VERSION ""
BS_:
BU_:

BO_ 1545 DAS_telemetryRadar: 8 ETH
 SG_ DAS_TR_Counter: 54|2@1+ (1,0) [0|0] "" X
 SG_ DAS_TR_ObjIndex M: 0|5@1+ (1,0) [0|0] "" X
 SG_ DAS_TR_Obj00_Class m0: 5|3@1+ (1,0) [0|0] "" X
 SG_ DAS_TR_Obj00_Dx m0: 8|10@1+ (0.15625,0) [0|0] "m" X
 SG_ DAS_TR_Obj00_Dy m0: 18|6@1+ (0.5,-15.5) [0|0] "m" X
 SG_ DAS_TR_Obj00_Vx m0: 24|8@1+ (0.5,-63.5) [0|0] "m/s" X
 SG_ DAS_TR_Obj00_RCS m0: 32|8@1+ (0.25,-14) [0|0] "dB" X
 SG_ DAS_TR_Obj00_Length m0: 40|6@1+ (0.125,0) [0|0] "m" X
 SG_ DAS_TR_Obj00_MovingState m0: 46|2@1+ (1,0) [0|0] "" X
 SG_ DAS_TR_Obj00_Dz m0: 48|6@1+ (0.25,-5) [0|0] "m" X
 SG_ DAS_TR_Obj00_Exist m0: 56|5@1+ (3.125,0) [0|0] "%" X
 SG_ DAS_TR_Obj01_Class m1: 5|3@1+ (1,0) [0|0] "" X
 SG_ DAS_TR_Obj01_Dx m1: 8|10@1+ (0.15625,0) [0|0] "m" X
 SG_ DAS_TR_Obj01_Dy m1: 18|6@1+ (0.5,-15.5) [0|0] "m" X
 SG_ DAS_TR_Obj01_Vx m1: 24|8@1+ (0.5,-63.5) [0|0] "m/s" X
 SG_ DAS_TR_Obj01_RCS m1: 32|8@1+ (0.25,-14) [0|0] "dB" X
 SG_ DAS_TR_Obj01_Length m1: 40|6@1+ (0.125,0) [0|0] "m" X
 SG_ DAS_TR_Obj01_MovingState m1: 46|2@1+ (1,0) [0|0] "" X
 SG_ DAS_TR_Obj01_Dz m1: 48|6@1+ (0.25,-5) [0|0] "m" X
 SG_ DAS_TR_Obj01_Exist m1: 56|5@1+ (3.125,0) [0|0] "%" X
 SG_ DAS_TR_Obj02_Class m2: 5|3@1+ (1,0) [0|0] "" X
 SG_ DAS_TR_Obj02_Dx m2: 8|10@1+ (0.15625,0) [0|0] "m" X
 SG_ DAS_TR_Obj02_Dy m2: 18|6@1+ (0.5,-15.5) [0|0] "m" X
 SG_ DAS_TR_Obj02_Vx m2: 24|8@1+ (0.5,-63.5) [0|0] "m/s" X
 SG_ DAS_TR_Obj02_RCS m2: 32|8@1+ (0.25,-14) [0|0] "dB" X
 SG_ DAS_TR_Obj02_Length m2: 40|6@1+ (0.125,0) [0|0] "m" X
 SG_ DAS_TR_Obj02_MovingState m2: 46|2@1+ (1,0) [0|0] "" X
 SG_ DAS_TR_Obj02_Dz m2: 48|6@1+ (0.25,-5) [0|0] "m" X
 SG_ DAS_TR_Obj02_Exist m2: 56|5@1+ (3.125,0) [0|0] "%" X
 SG_ DAS_TR_Obj03_Class m3: 5|3@1+ (1,0) [0|0] "" X
 SG_ DAS_TR_Obj03_Dx m3: 8|10@1+ (0.15625,0) [0|0] "m" X
 SG_ DAS_TR_Obj03_Dy m3: 18|6@1+ (0.5,-15.5) [0|0] "m" X
 SG_ DAS_TR_Obj03_Vx m3: 24|8@1+ (0.5,-63.5) [0|0] "m/s" X
 SG_ DAS_TR_Obj03_RCS m3: 32|8@1+ (0.25,-14) [0|0] "dB" X
 SG_ DAS_TR_Obj03_Length m3: 40|6@1+ (0.125,0) [0|0] "m" X
 SG_ DAS_TR_Obj03_MovingState m3: 46|2@1+ (1,0) [0|0] "" X
 SG_ DAS_TR_Obj03_Dz m3: 48|6@1+ (0.25,-5) [0|0] "m" X
 SG_ DAS_TR_Obj03_Exist m3: 56|5@1+ (3.125,0) [0|0] "%" X
 SG_ DAS_TR_Obj04_Class m4: 5|3@1+ (1,0) [0|0] "" X
 SG_ DAS_TR_Obj04_Dx m4: 8|10@1+ (0.15625,0) [0|0] "m" X
 SG_ DAS_TR_Obj04_Dy m4: 18|6@1+ (0.5,-15.5) [0|0] "m" X
 SG_ DAS_TR_Obj04_Vx m4: 24|8@1+ (0.5,-63.5) [0|0] "m/s" X
 SG_ DAS_TR_Obj04_RCS m4: 32|8@1+ (0.25,-14) [0|0] "dB" X
 SG_ DAS_TR_Obj04_Length m4: 40|6@1+ (0.125,0) [0|0] "m" X
 SG_ DAS_TR_Obj04_MovingState m4: 46|2@1+ (1,0) [0|0] "" X
 SG_ DAS_TR_Obj04_Dz m4: 48|6@1+ (0.25,-5) [0|0] "m" X
 SG_ DAS_TR_Obj04_Exist m4: 56|5@1+ (3.125,0) [0|0] "%" X
 SG_ DAS_TR_Obj05_Class m5: 5|3@1+ (1,0) [0|0] "" X
 SG_ DAS_TR_Obj05_Dx m5: 8|10@1+ (0.15625,0) [0|0] "m" X
 SG_ DAS_TR_Obj05_Dy m5: 18|6@1+ (0.5,-15.5) [0|0] "m" X
 SG_ DAS_TR_Obj05_Vx m5: 24|8@1+ (0.5,-63.5) [0|0] "m/s" X
 SG_ DAS_TR_Obj05_RCS m5: 32|8@1+ (0.25,-14) [0|0] "dB" X
 SG_ DAS_TR_Obj05_Length m5: 40|6@1+ (0.125,0) [0|0] "m" X
 SG_ DAS_TR_Obj05_MovingState m5: 46|2@1+ (1,0) [0|0] "" X
 SG_ DAS_TR_Obj05_Dz m5: 48|6@1+ (0.25,-5) [0|0] "m" X
 SG_ DAS_TR_Obj05_Exist m5: 56|5@1+ (3.125,0) [0|0] "%" X
 SG_ DAS_TR_Obj06_Class m6: 5|3@1+ (1,0) [0|0] "" X
 SG_ DAS_TR_Obj06_Dx m6: 8|10@1+ (0.15625,0) [0|0] "m" X
 SG_ DAS_TR_Obj06_Dy m6: 18|6@1+ (0.5,-15.5) [0|0] "m" X
 SG_ DAS_TR_Obj06_Vx m6: 24|8@1+ (0.5,-63.5) [0|0] "m/s" X
 SG_ DAS_TR_Obj06_RCS m6: 32|8@1+ (0.25,-14) [0|0] "dB" X
 SG_ DAS_TR_Obj06_Length m6: 40|6@1+ (0.125,0) [0|0] "m" X
 SG_ DAS_TR_Obj06_MovingState m6: 46|2@1+ (1,0) [0|0] "" X
 SG_ DAS_TR_Obj06_Dz m6: 48|6@1+ (0.25,-5) [0|0] "m" X
 SG_ DAS_TR_Obj06_Exist m6: 56|5@1+ (3.125,0) [0|0] "%" X
 SG_ DAS_TR_Obj07_Class m7: 5|3@1+ (1,0) [0|0] "" X
 SG_ DAS_TR_Obj07_Dx m7: 8|10@1+ (0.15625,0) [0|0] "m" X
 SG_ DAS_TR_Obj07_Dy m7: 18|6@1+ (0.5,-15.5) [0|0] "m" X
 SG_ DAS_TR_Obj07_Vx m7: 24|8@1+ (0.5,-63.5) [0|0] "m/s" X
 SG_ DAS_TR_Obj07_RCS m7: 32|8@1+ (0.25,-14) [0|0] "dB" X
 SG_ DAS_TR_Obj07_Length m7: 40|6@1+ (0.125,0) [0|0] "m" X
 SG_ DAS_TR_Obj07_MovingState m7: 46|2@1+ (1,0) [0|0] "" X
 SG_ DAS_TR_Obj07_Dz m7: 48|6@1+ (0.25,-5) [0|0] "m" X
 SG_ DAS_TR_Obj07_Exist m7: 56|5@1+ (3.125,0) [0|0] "%" X
 SG_ DAS_TR_Obj08_Class m8: 5|3@1+ (1,0) [0|0] "" X
 SG_ DAS_TR_Obj08_Dx m8: 8|10@1+ (0.15625,0) [0|0] "m" X
 SG_ DAS_TR_Obj08_Dy m8: 18|6@1+ (0.5,-15.5) [0|0] "m" X
 SG_ DAS_TR_Obj08_Vx m8: 24|8@1+ (0.5,-63.5) [0|0] "m/s" X
 SG_ DAS_TR_Obj08_RCS m8: 32|8@1+ (0.25,-14) [0|0] "dB" X
 SG_ DAS_TR_Obj08_Length m8: 40|6@1+ (0.125,0) [0|0] "m" X
 SG_ DAS_TR_Obj08_MovingState m8: 46|2@1+ (1,0) [0|0] "" X
 SG_ DAS_TR_Obj08_Dz m8: 48|6@1+ (0.25,-5) [0|0] "m" X
 SG_ DAS_TR_Obj08_Exist m8: 56|5@1+ (3.125,0) [0|0] "%" X
 SG_ DAS_TR_Obj09_Class m9: 5|3@1+ (1,0) [0|0] "" X
 SG_ DAS_TR_Obj09_Dx m9: 8|10@1+ (0.15625,0) [0|0] "m" X
 SG_ DAS_TR_Obj09_Dy m9: 18|6@1+ (0.5,-15.5) [0|0] "m" X
 SG_ DAS_TR_Obj09_Vx m9: 24|8@1+ (0.5,-63.5) [0|0] "m/s" X
 SG_ DAS_TR_Obj09_RCS m9: 32|8@1+ (0.25,-14) [0|0] "dB" X
 SG_ DAS_TR_Obj09_Length m9: 40|6@1+ (0.125,0) [0|0] "m" X
 SG_ DAS_TR_Obj09_MovingState m9: 46|2@1+ (1,0) [0|0] "" X
 SG_ DAS_TR_Obj09_Dz m9: 48|6@1+ (0.25,-5) [0|0] "m" X
 SG_ DAS_TR_Obj09_Exist m9: 56|5@1+ (3.125,0) [0|0] "%" X
 SG_ DAS_TR_Obj10_Class m10: 5|3@1+ (1,0) [0|0] "" X
 SG_ DAS_TR_Obj10_Dx m10: 8|10@1+ (0.15625,0) [0|0] "m" X
 SG_ DAS_TR_Obj10_Dy m10: 18|6@1+ (0.5,-15.5) [0|0] "m" X
 SG_ DAS_TR_Obj10_Vx m10: 24|8@1+ (0.5,-63.5) [0|0] "m/s" X
 SG_ DAS_TR_Obj10_RCS m10: 32|8@1+ (0.25,-14) [0|0] "dB" X
 SG_ DAS_TR_Obj10_Length m10: 40|6@1+ (0.125,0) [0|0] "m" X
 SG_ DAS_TR_Obj10_MovingState m10: 46|2@1+ (1,0) [0|0] "" X
 SG_ DAS_TR_Obj10_Dz m10: 48|6@1+ (0.25,-5) [0|0] "m" X
 SG_ DAS_TR_Obj10_Exist m10: 56|5@1+ (3.125,0) [0|0] "%" X
 SG_ DAS_TR_Obj11_Class m11: 5|3@1+ (1,0) [0|0] "" X
 SG_ DAS_TR_Obj11_Dx m11: 8|10@1+ (0.15625,0) [0|0] "m" X
 SG_ DAS_TR_Obj11_Dy m11: 18|6@1+ (0.5,-15.5) [0|0] "m" X
 SG_ DAS_TR_Obj11_Vx m11: 24|8@1+ (0.5,-63.5) [0|0] "m/s" X
 SG_ DAS_TR_Obj11_RCS m11: 32|8@1+ (0.25,-14) [0|0] "dB" X
 SG_ DAS_TR_Obj11_Length m11: 40|6@1+ (0.125,0) [0|0] "m" X
 SG_ DAS_TR_Obj11_MovingState m11: 46|2@1+ (1,0) [0|0] "" X
 SG_ DAS_TR_Obj11_Dz m11: 48|6@1+ (0.25,-5) [0|0] "m" X
 SG_ DAS_TR_Obj11_Exist m11: 56|5@1+ (3.125,0) [0|0] "%" X
 SG_ DAS_TR_Obj12_Class m12: 5|3@1+ (1,0) [0|0] "" X
 SG_ DAS_TR_Obj12_Dx m12: 8|10@1+ (0.15625,0) [0|0] "m" X
 SG_ DAS_TR_Obj12_Dy m12: 18|6@1+ (0.5,-15.5) [0|0] "m" X
 SG_ DAS_TR_Obj12_Vx m12: 24|8@1+ (0.5,-63.5) [0|0] "m/s" X
 SG_ DAS_TR_Obj12_RCS m12: 32|8@1+ (0.25,-14) [0|0] "dB" X
 SG_ DAS_TR_Obj12_Length m12: 40|6@1+ (0.125,0) [0|0] "m" X
 SG_ DAS_TR_Obj12_MovingState m12: 46|2@1+ (1,0) [0|0] "" X
 SG_ DAS_TR_Obj12_Dz m12: 48|6@1+ (0.25,-5) [0|0] "m" X
 SG_ DAS_TR_Obj12_Exist m12: 56|5@1+ (3.125,0) [0|0] "%" X
 SG_ DAS_TR_Obj13_Class m13: 5|3@1+ (1,0) [0|0] "" X
 SG_ DAS_TR_Obj13_Dx m13: 8|10@1+ (0.15625,0) [0|0] "m" X
 SG_ DAS_TR_Obj13_Dy m13: 18|6@1+ (0.5,-15.5) [0|0] "m" X
 SG_ DAS_TR_Obj13_Vx m13: 24|8@1+ (0.5,-63.5) [0|0] "m/s" X
 SG_ DAS_TR_Obj13_RCS m13: 32|8@1+ (0.25,-14) [0|0] "dB" X
 SG_ DAS_TR_Obj13_Length m13: 40|6@1+ (0.125,0) [0|0] "m" X
 SG_ DAS_TR_Obj13_MovingState m13: 46|2@1+ (1,0) [0|0] "" X
 SG_ DAS_TR_Obj13_Dz m13: 48|6@1+ (0.25,-5) [0|0] "m" X
 SG_ DAS_TR_Obj13_Exist m13: 56|5@1+ (3.125,0) [0|0] "%" X
 SG_ DAS_TR_Obj14_Class m14: 5|3@1+ (1,0) [0|0] "" X
 SG_ DAS_TR_Obj14_Dx m14: 8|10@1+ (0.15625,0) [0|0] "m" X
 SG_ DAS_TR_Obj14_Dy m14: 18|6@1+ (0.5,-15.5) [0|0] "m" X
 SG_ DAS_TR_Obj14_Vx m14: 24|8@1+ (0.5,-63.5) [0|0] "m/s" X
 SG_ DAS_TR_Obj14_RCS m14: 32|8@1+ (0.25,-14) [0|0] "dB" X
 SG_ DAS_TR_Obj14_Length m14: 40|6@1+ (0.125,0) [0|0] "m" X
 SG_ DAS_TR_Obj14_MovingState m14: 46|2@1+ (1,0) [0|0] "" X
 SG_ DAS_TR_Obj14_Dz m14: 48|6@1+ (0.25,-5) [0|0] "m" X
 SG_ DAS_TR_Obj14_Exist m14: 56|5@1+ (3.125,0) [0|0] "%" X
 SG_ DAS_TR_Obj15_Class m15: 5|3@1+ (1,0) [0|0] "" X
 SG_ DAS_TR_Obj15_Dx m15: 8|10@1+ (0.15625,0) [0|0] "m" X
 SG_ DAS_TR_Obj15_Dy m15: 18|6@1+ (0.5,-15.5) [0|0] "m" X
 SG_ DAS_TR_Obj15_Vx m15: 24|8@1+ (0.5,-63.5) [0|0] "m/s" X
 SG_ DAS_TR_Obj15_RCS m15: 32|8@1+ (0.25,-14) [0|0] "dB" X
 SG_ DAS_TR_Obj15_Length m15: 40|6@1+ (0.125,0) [0|0] "m" X
 SG_ DAS_TR_Obj15_MovingState m15: 46|2@1+ (1,0) [0|0] "" X
 SG_ DAS_TR_Obj15_Dz m15: 48|6@1+ (0.25,-5) [0|0] "m" X
 SG_ DAS_TR_Obj15_Exist m15: 56|5@1+ (3.125,0) [0|0] "%" X
 SG_ DAS_TR_Obj16_Class m16: 5|3@1+ (1,0) [0|0] "" X
 SG_ DAS_TR_Obj16_Dx m16: 8|10@1+ (0.15625,0) [0|0] "m" X
 SG_ DAS_TR_Obj16_Dy m16: 18|6@1+ (0.5,-15.5) [0|0] "m" X
 SG_ DAS_TR_Obj16_Vx m16: 24|8@1+ (0.5,-63.5) [0|0] "m/s" X
 SG_ DAS_TR_Obj16_RCS m16: 32|8@1+ (0.25,-14) [0|0] "dB" X
 SG_ DAS_TR_Obj16_Length m16: 40|6@1+ (0.125,0) [0|0] "m" X
 SG_ DAS_TR_Obj16_MovingState m16: 46|2@1+ (1,0) [0|0] "" X
 SG_ DAS_TR_Obj16_Dz m16: 48|6@1+ (0.25,-5) [0|0] "m" X
 SG_ DAS_TR_Obj16_Exist m16: 56|5@1+ (3.125,0) [0|0] "%" X
 SG_ DAS_TR_Obj17_Class m17: 5|3@1+ (1,0) [0|0] "" X
 SG_ DAS_TR_Obj17_Dx m17: 8|10@1+ (0.15625,0) [0|0] "m" X
 SG_ DAS_TR_Obj17_Dy m17: 18|6@1+ (0.5,-15.5) [0|0] "m" X
 SG_ DAS_TR_Obj17_Vx m17: 24|8@1+ (0.5,-63.5) [0|0] "m/s" X
 SG_ DAS_TR_Obj17_RCS m17: 32|8@1+ (0.25,-14) [0|0] "dB" X
 SG_ DAS_TR_Obj17_Length m17: 40|6@1+ (0.125,0) [0|0] "m" X
 SG_ DAS_TR_Obj17_MovingState m17: 46|2@1+ (1,0) [0|0] "" X
 SG_ DAS_TR_Obj17_Dz m17: 48|6@1+ (0.25,-5) [0|0] "m" X
 SG_ DAS_TR_Obj17_Exist m17: 56|5@1+ (3.125,0) [0|0] "%" X
 SG_ DAS_TR_Obj18_Class m18: 5|3@1+ (1,0) [0|0] "" X
 SG_ DAS_TR_Obj18_Dx m18: 8|10@1+ (0.15625,0) [0|0] "m" X
 SG_ DAS_TR_Obj18_Dy m18: 18|6@1+ (0.5,-15.5) [0|0] "m" X
 SG_ DAS_TR_Obj18_Vx m18: 24|8@1+ (0.5,-63.5) [0|0] "m/s" X
 SG_ DAS_TR_Obj18_RCS m18: 32|8@1+ (0.25,-14) [0|0] "dB" X
 SG_ DAS_TR_Obj18_Length m18: 40|6@1+ (0.125,0) [0|0] "m" X
 SG_ DAS_TR_Obj18_MovingState m18: 46|2@1+ (1,0) [0|0] "" X
 SG_ DAS_TR_Obj18_Dz m18: 48|6@1+ (0.25,-5) [0|0] "m" X
 SG_ DAS_TR_Obj18_Exist m18: 56|5@1+ (3.125,0) [0|0] "%" X
 SG_ DAS_TR_Obj19_Class m19: 5|3@1+ (1,0) [0|0] "" X
 SG_ DAS_TR_Obj19_Dx m19: 8|10@1+ (0.15625,0) [0|0] "m" X
 SG_ DAS_TR_Obj19_Dy m19: 18|6@1+ (0.5,-15.5) [0|0] "m" X
 SG_ DAS_TR_Obj19_Vx m19: 24|8@1+ (0.5,-63.5) [0|0] "m/s" X
 SG_ DAS_TR_Obj19_RCS m19: 32|8@1+ (0.25,-14) [0|0] "dB" X
 SG_ DAS_TR_Obj19_Length m19: 40|6@1+ (0.125,0) [0|0] "m" X
 SG_ DAS_TR_Obj19_MovingState m19: 46|2@1+ (1,0) [0|0] "" X
 SG_ DAS_TR_Obj19_Dz m19: 48|6@1+ (0.25,-5) [0|0] "m" X
 SG_ DAS_TR_Obj19_Exist m19: 56|5@1+ (3.125,0) [0|0] "%" X
 SG_ DAS_TR_Obj20_Class m20: 5|3@1+ (1,0) [0|0] "" X
 SG_ DAS_TR_Obj20_Dx m20: 8|10@1+ (0.15625,0) [0|0] "m" X
 SG_ DAS_TR_Obj20_Dy m20: 18|6@1+ (0.5,-15.5) [0|0] "m" X
 SG_ DAS_TR_Obj20_Vx m20: 24|8@1+ (0.5,-63.5) [0|0] "m/s" X
 SG_ DAS_TR_Obj20_RCS m20: 32|8@1+ (0.25,-14) [0|0] "dB" X
 SG_ DAS_TR_Obj20_Length m20: 40|6@1+ (0.125,0) [0|0] "m" X
 SG_ DAS_TR_Obj20_MovingState m20: 46|2@1+ (1,0) [0|0] "" X
 SG_ DAS_TR_Obj20_Dz m20: 48|6@1+ (0.25,-5) [0|0] "m" X
 SG_ DAS_TR_Obj20_Exist m20: 56|5@1+ (3.125,0) [0|0] "%" X
 SG_ DAS_TR_Obj21_Class m21: 5|3@1+ (1,0) [0|0] "" X
 SG_ DAS_TR_Obj21_Dx m21: 8|10@1+ (0.15625,0) [0|0] "m" X
 SG_ DAS_TR_Obj21_Dy m21: 18|6@1+ (0.5,-15.5) [0|0] "m" X
 SG_ DAS_TR_Obj21_Vx m21: 24|8@1+ (0.5,-63.5) [0|0] "m/s" X
 SG_ DAS_TR_Obj21_RCS m21: 32|8@1+ (0.25,-14) [0|0] "dB" X
 SG_ DAS_TR_Obj21_Length m21: 40|6@1+ (0.125,0) [0|0] "m" X
 SG_ DAS_TR_Obj21_MovingState m21: 46|2@1+ (1,0) [0|0] "" X
 SG_ DAS_TR_Obj21_Dz m21: 48|6@1+ (0.25,-5) [0|0] "m" X
 SG_ DAS_TR_Obj21_Exist m21: 56|5@1+ (3.125,0) [0|0] "%" X
 SG_ DAS_TR_Obj22_Class m22: 5|3@1+ (1,0) [0|0] "" X
 SG_ DAS_TR_Obj22_Dx m22: 8|10@1+ (0.15625,0) [0|0] "m" X
 SG_ DAS_TR_Obj22_Dy m22: 18|6@1+ (0.5,-15.5) [0|0] "m" X
 SG_ DAS_TR_Obj22_Vx m22: 24|8@1+ (0.5,-63.5) [0|0] "m/s" X
 SG_ DAS_TR_Obj22_RCS m22: 32|8@1+ (0.25,-14) [0|0] "dB" X
 SG_ DAS_TR_Obj22_Length m22: 40|6@1+ (0.125,0) [0|0] "m" X
 SG_ DAS_TR_Obj22_MovingState m22: 46|2@1+ (1,0) [0|0] "" X
 SG_ DAS_TR_Obj22_Dz m22: 48|6@1+ (0.25,-5) [0|0] "m" X
 SG_ DAS_TR_Obj22_Exist m22: 56|5@1+ (3.125,0) [0|0] "%" X
 SG_ DAS_TR_Obj23_Class m23: 5|3@1+ (1,0) [0|0] "" X
 SG_ DAS_TR_Obj23_Dx m23: 8|10@1+ (0.15625,0) [0|0] "m" X
 SG_ DAS_TR_Obj23_Dy m23: 18|6@1+ (0.5,-15.5) [0|0] "m" X
 SG_ DAS_TR_Obj23_Vx m23: 24|8@1+ (0.5,-63.5) [0|0] "m/s" X
 SG_ DAS_TR_Obj23_RCS m23: 32|8@1+ (0.25,-14) [0|0] "dB" X
 SG_ DAS_TR_Obj23_Length m23: 40|6@1+ (0.125,0) [0|0] "m" X
 SG_ DAS_TR_Obj23_MovingState m23: 46|2@1+ (1,0) [0|0] "" X
 SG_ DAS_TR_Obj23_Dz m23: 48|6@1+ (0.25,-5) [0|0] "m" X
 SG_ DAS_TR_Obj23_Exist m23: 56|5@1+ (3.125,0) [0|0] "%" X
 SG_ DAS_TR_Obj24_Class m24: 5|3@1+ (1,0) [0|0] "" X
 SG_ DAS_TR_Obj24_Dx m24: 8|10@1+ (0.15625,0) [0|0] "m" X
 SG_ DAS_TR_Obj24_Dy m24: 18|6@1+ (0.5,-15.5) [0|0] "m" X
 SG_ DAS_TR_Obj24_Vx m24: 24|8@1+ (0.5,-63.5) [0|0] "m/s" X
 SG_ DAS_TR_Obj24_RCS m24: 32|8@1+ (0.25,-14) [0|0] "dB" X
 SG_ DAS_TR_Obj24_Length m24: 40|6@1+ (0.125,0) [0|0] "m" X
 SG_ DAS_TR_Obj24_MovingState m24: 46|2@1+ (1,0) [0|0] "" X
 SG_ DAS_TR_Obj24_Dz m24: 48|6@1+ (0.25,-5) [0|0] "m" X
 SG_ DAS_TR_Obj24_Exist m24: 56|5@1+ (3.125,0) [0|0] "%" X
 SG_ DAS_TR_Obj25_Class m25: 5|3@1+ (1,0) [0|0] "" X
 SG_ DAS_TR_Obj25_Dx m25: 8|10@1+ (0.15625,0) [0|0] "m" X
 SG_ DAS_TR_Obj25_Dy m25: 18|6@1+ (0.5,-15.5) [0|0] "m" X
 SG_ DAS_TR_Obj25_Vx m25: 24|8@1+ (0.5,-63.5) [0|0] "m/s" X
 SG_ DAS_TR_Obj25_RCS m25: 32|8@1+ (0.25,-14) [0|0] "dB" X
 SG_ DAS_TR_Obj25_Length m25: 40|6@1+ (0.125,0) [0|0] "m" X
 SG_ DAS_TR_Obj25_MovingState m25: 46|2@1+ (1,0) [0|0] "" X
 SG_ DAS_TR_Obj25_Dz m25: 48|6@1+ (0.25,-5) [0|0] "m" X
 SG_ DAS_TR_Obj25_Exist m25: 56|5@1+ (3.125,0) [0|0] "%" X
 SG_ DAS_TR_Obj26_Class m26: 5|3@1+ (1,0) [0|0] "" X
 SG_ DAS_TR_Obj26_Dx m26: 8|10@1+ (0.15625,0) [0|0] "m" X
 SG_ DAS_TR_Obj26_Dy m26: 18|6@1+ (0.5,-15.5) [0|0] "m" X
 SG_ DAS_TR_Obj26_Vx m26: 24|8@1+ (0.5,-63.5) [0|0] "m/s" X
 SG_ DAS_TR_Obj26_RCS m26: 32|8@1+ (0.25,-14) [0|0] "dB" X
 SG_ DAS_TR_Obj26_Length m26: 40|6@1+ (0.125,0) [0|0] "m" X
 SG_ DAS_TR_Obj26_MovingState m26: 46|2@1+ (1,0) [0|0] "" X
 SG_ DAS_TR_Obj26_Dz m26: 48|6@1+ (0.25,-5) [0|0] "m" X
 SG_ DAS_TR_Obj26_Exist m26: 56|5@1+ (3.125,0) [0|0] "%" X
 SG_ DAS_TR_Obj27_Class m27: 5|3@1+ (1,0) [0|0] "" X
 SG_ DAS_TR_Obj27_Dx m27: 8|10@1+ (0.15625,0) [0|0] "m" X
 SG_ DAS_TR_Obj27_Dy m27: 18|6@1+ (0.5,-15.5) [0|0] "m" X
 SG_ DAS_TR_Obj27_Vx m27: 24|8@1+ (0.5,-63.5) [0|0] "m/s" X
 SG_ DAS_TR_Obj27_RCS m27: 32|8@1+ (0.25,-14) [0|0] "dB" X
 SG_ DAS_TR_Obj27_Length m27: 40|6@1+ (0.125,0) [0|0] "m" X
 SG_ DAS_TR_Obj27_MovingState m27: 46|2@1+ (1,0) [0|0] "" X
 SG_ DAS_TR_Obj27_Dz m27: 48|6@1+ (0.25,-5) [0|0] "m" X
 SG_ DAS_TR_Obj27_Exist m27: 56|5@1+ (3.125,0) [0|0] "%" X
 SG_ DAS_TR_Obj28_Class m28: 5|3@1+ (1,0) [0|0] "" X
 SG_ DAS_TR_Obj28_Dx m28: 8|10@1+ (0.15625,0) [0|0] "m" X
 SG_ DAS_TR_Obj28_Dy m28: 18|6@1+ (0.5,-15.5) [0|0] "m" X
 SG_ DAS_TR_Obj28_Vx m28: 24|8@1+ (0.5,-63.5) [0|0] "m/s" X
 SG_ DAS_TR_Obj28_RCS m28: 32|8@1+ (0.25,-14) [0|0] "dB" X
 SG_ DAS_TR_Obj28_Length m28: 40|6@1+ (0.125,0) [0|0] "m" X
 SG_ DAS_TR_Obj28_MovingState m28: 46|2@1+ (1,0) [0|0] "" X
 SG_ DAS_TR_Obj28_Dz m28: 48|6@1+ (0.25,-5) [0|0] "m" X
 SG_ DAS_TR_Obj28_Exist m28: 56|5@1+ (3.125,0) [0|0] "%" X
 SG_ DAS_TR_Obj29_Class m29: 5|3@1+ (1,0) [0|0] "" X
 SG_ DAS_TR_Obj29_Dx m29: 8|10@1+ (0.15625,0) [0|0] "m" X
 SG_ DAS_TR_Obj29_Dy m29: 18|6@1+ (0.5,-15.5) [0|0] "m" X
 SG_ DAS_TR_Obj29_Vx m29: 24|8@1+ (0.5,-63.5) [0|0] "m/s" X
 SG_ DAS_TR_Obj29_RCS m29: 32|8@1+ (0.25,-14) [0|0] "dB" X
 SG_ DAS_TR_Obj29_Length m29: 40|6@1+ (0.125,0) [0|0] "m" X
 SG_ DAS_TR_Obj29_MovingState m29: 46|2@1+ (1,0) [0|0] "" X
 SG_ DAS_TR_Obj29_Dz m29: 48|6@1+ (0.25,-5) [0|0] "m" X
 SG_ DAS_TR_Obj29_Exist m29: 56|5@1+ (3.125,0) [0|0] "%" X
 SG_ DAS_TR_Obj30_Class m30: 5|3@1+ (1,0) [0|0] "" X
 SG_ DAS_TR_Obj30_Dx m30: 8|10@1+ (0.15625,0) [0|0] "m" X
 SG_ DAS_TR_Obj30_Dy m30: 18|6@1+ (0.5,-15.5) [0|0] "m" X
 SG_ DAS_TR_Obj30_Vx m30: 24|8@1+ (0.5,-63.5) [0|0] "m/s" X
 SG_ DAS_TR_Obj30_RCS m30: 32|8@1+ (0.25,-14) [0|0] "dB" X
 SG_ DAS_TR_Obj30_Length m30: 40|6@1+ (0.125,0) [0|0] "m" X
 SG_ DAS_TR_Obj30_MovingState m30: 46|2@1+ (1,0) [0|0] "" X
 SG_ DAS_TR_Obj30_Dz m30: 48|6@1+ (0.25,-5) [0|0] "m" X
 SG_ DAS_TR_Obj30_Exist m30: 56|5@1+ (3.125,0) [0|0] "%" X
 SG_ DAS_TR_Obj31_Class m31: 5|3@1+ (1,0) [0|0] "" X
 SG_ DAS_TR_Obj31_Dx m31: 8|10@1+ (0.15625,0) [0|0] "m" X
 SG_ DAS_TR_Obj31_Dy m31: 18|6@1+ (0.5,-15.5) [0|0] "m" X
 SG_ DAS_TR_Obj31_Vx m31: 24|8@1+ (0.5,-63.5) [0|0] "m/s" X
 SG_ DAS_TR_Obj31_RCS m31: 32|8@1+ (0.25,-14) [0|0] "dB" X
 SG_ DAS_TR_Obj31_Length m31: 40|6@1+ (0.125,0) [0|0] "m" X
 SG_ DAS_TR_Obj31_MovingState m31: 46|2@1+ (1,0) [0|0] "" X
 SG_ DAS_TR_Obj31_Dz m31: 48|6@1+ (0.25,-5) [0|0] "m" X
 SG_ DAS_TR_Obj31_Exist m31: 56|5@1+ (3.125,0) [0|0] "%" X

BO_ 1625 DAS_udsResponse: 8 ETH
 SG_ DAS_udsResponseData: 0|54@0+ (1024,0) [0|0] "" X

BO_ 585 DAS_visualDebug: 8 ETH
 SG_ DAS_accSmartSpeedActive: 48|1@1+ (1,0) [0|0] "" X
 SG_ DAS_accSmartSpeedState: 49|3@1+ (1,0) [0|0] "" X
 SG_ DAS_autosteerBottsDotsUsage: 12|2@1+ (1,0) [0|0] "" X
 SG_ DAS_autosteerHPPUsage: 6|2@1+ (1,0) [0|0] "" X
 SG_ DAS_autosteerHealthAnomalyLevel: 18|3@1+ (1,0) [0|0] "" X
 SG_ DAS_autosteerHealthState: 21|3@1+ (1,0) [0|0] "" X
 SG_ DAS_autosteerModelUsage: 10|2@1+ (1,0) [0|0] "" X
 SG_ DAS_autosteerNavigationUsage: 8|2@1+ (1,0) [0|0] "" X
 SG_ DAS_autosteerVehiclesUsage: 4|2@1+ (1,0) [0|0] "" X
 SG_ DAS_behaviorType: 56|2@1+ (1,0) [0|0] "" X
 SG_ DAS_devAppInterfaceEnabled: 38|1@1+ (1,0) [0|0] "" X
 SG_ DAS_lastAutosteerAbortReason: 32|6@1+ (1,0) [0|0] "" X
 SG_ DAS_lastLinePreferenceReason: 24|4@1+ (1,0) [0|0] "" X
 SG_ DAS_navAvailable: 39|1@1+ (1,0) [0|0] "" X
 SG_ DAS_navDistance: 40|8@1+ (100,0) [0|0] "" X
 SG_ DAS_offsetSide: 14|2@1+ (1,0) [0|0] "" X
 SG_ DAS_plannerState: 28|4@1+ (1,0) [0|0] "" X
 SG_ DAS_rearVehDetectedThisCycle: 60|1@1+ (1,0) [0|0] "" X
 SG_ DAS_roadSurfaceType: 16|2@1+ (1,0) [0|0] "" X
 SG_ DAS_ulcInProgress: 52|1@1+ (1,0) [0|0] "" X
 SG_ DAS_ulcType: 58|2@1+ (1,0) [0|0] "" X

BO_ 809 DAS_warningMatrix0: 8 ETH
 SG_ DAS_w002_ldwDisabled: 1|1@1+ (1,0) [0|0] "" X
 SG_ DAS_w003_isaDisabled: 2|1@1+ (1,0) [0|0] "" X
 SG_ DAS_w004_accDisabled: 3|1@1+ (1,0) [0|0] "" X
 SG_ DAS_w005_fcwCancelled: 4|1@1+ (1,0) [0|0] "" X
 SG_ DAS_w006_aebCancelled: 5|1@1+ (1,0) [0|0] "" X
 SG_ DAS_w007_ahlbDisabled: 6|1@1+ (1,0) [0|0] "" X
 SG_ DAS_w008_parkDisabled: 7|1@1+ (1,0) [0|0] "" X
 SG_ DAS_w009_aebFault: 8|1@1+ (1,0) [0|0] "" X
 SG_ DAS_w010_radcCalibIssue: 9|1@1+ (1,0) [0|0] "" X
 SG_ DAS_w011_scaEvent: 10|1@1+ (1,0) [0|0] "" X
 SG_ DAS_w012_Cam_BootFailure: 11|1@1+ (1,0) [0|0] "" X
 SG_ DAS_w013_Cam_Watchdog: 12|1@1+ (1,0) [0|0] "" X
 SG_ DAS_w014_swAssert: 13|1@1+ (1,0) [0|0] "" X
 SG_ DAS_w015_Camera_Failsafes: 14|1@1+ (1,0) [0|0] "" X
 SG_ DAS_w016_aeb_e_event: 15|1@1+ (1,0) [0|0] "" X
 SG_ DAS_w017_Cam_Msg_MIA: 16|1@1+ (1,0) [0|0] "" X
 SG_ DAS_w018_ECU_Power_Issue: 17|1@1+ (1,0) [0|0] "" X
 SG_ DAS_w019_ECU_Stack_Overflow: 18|1@1+ (1,0) [0|0] "" X
 SG_ DAS_w020_ECU_checkstopError: 19|1@1+ (1,0) [0|0] "" X
 SG_ DAS_w021_ECU_Temperature_Issue: 20|1@1+ (1,0) [0|0] "" X
 SG_ DAS_w022_ECU_EEPROM_Failure: 21|1@1+ (1,0) [0|0] "" X
 SG_ DAS_w023_ECU_Cam_Statemismatc: 22|1@1+ (1,0) [0|0] "" X
 SG_ DAS_w024_ECU_Watchdog_Reset: 23|1@1+ (1,0) [0|0] "" X
 SG_ DAS_w025_LC_Steering_Override: 24|1@1+ (1,0) [0|0] "" X
 SG_ DAS_w026_ECU_timingIssue: 25|1@1+ (1,0) [0|0] "" X
 SG_ DAS_w027_ECU_Reset_Fault: 26|1@1+ (1,0) [0|0] "" X
 SG_ DAS_w028_spi_rx_error: 27|1@1+ (1,0) [0|0] "" X
 SG_ DAS_w029_spi_tx_error: 28|1@1+ (1,0) [0|0] "" X
 SG_ DAS_w030_Heater_Issue: 29|1@1+ (1,0) [0|0] "" X
 SG_ DAS_w031_canRxError: 30|1@1+ (1,0) [0|0] "" X
 SG_ DAS_w032_canTxError: 31|1@1+ (1,0) [0|0] "" X
 SG_ DAS_w033_gtwMia: 32|1@1+ (1,0) [0|0] "" X
 SG_ DAS_w034_sccmMia: 33|1@1+ (1,0) [0|0] "" X
 SG_ DAS_w035_espMia: 34|1@1+ (1,0) [0|0] "" X
 SG_ DAS_w036_bdyMia: 35|1@1+ (1,0) [0|0] "" X
 SG_ DAS_w037_camTacIssue: 36|1@1+ (1,0) [0|0] "" X
 SG_ DAS_w038_camFailure: 37|1@1+ (1,0) [0|0] "" X
 SG_ DAS_w039_sdm_rcm_Mia: 38|1@1+ (1,0) [0|0] "" X
 SG_ DAS_w040_autopilotAngleSaturated: 39|1@1+ (1,0) [0|0] "" X
 SG_ DAS_w041_autopilotRateSaturated: 40|1@1+ (1,0) [0|0] "" X
 SG_ DAS_w042_autopilotAborting: 41|1@1+ (1,0) [0|0] "" X
 SG_ DAS_w043_camLongRunTime: 42|1@1+ (1,0) [0|0] "" X
 SG_ DAS_w044_appMobileyeFailure: 43|1@1+ (1,0) [0|0] "" X
 SG_ DAS_w045_radMia: 44|1@1+ (1,0) [0|0] "" X
 SG_ DAS_w046_eepromRecordAbsent: 45|1@1+ (1,0) [0|0] "" X
 SG_ DAS_w047_edrEvent: 46|1@1+ (1,0) [0|0] "" X
 SG_ DAS_w048_DAS_Features_Disabled: 47|1@1+ (1,0) [0|0] "" X
 SG_ DAS_w049_eyeqVersionMismatch: 48|1@1+ (1,0) [0|0] "" X
 SG_ DAS_w050_aeb_event: 49|1@1+ (1,0) [0|0] "" X
 SG_ DAS_w051_radcEcuIssue: 50|1@1+ (1,0) [0|0] "" X
 SG_ DAS_w052_radcSensorIssue: 51|1@1+ (1,0) [0|0] "" X
 SG_ DAS_w053_radcCommIssue: 52|1@1+ (1,0) [0|0] "" X
 SG_ DAS_w054_camAutofix: 53|1@1+ (1,0) [0|0] "" X
 SG_ DAS_w055_radcVersionMismatch: 54|1@1+ (1,0) [0|0] "" X
 SG_ DAS_w056_diMia: 55|1@1+ (1,0) [0|0] "" X
 SG_ DAS_w057_mcuMia: 56|1@1+ (1,0) [0|0] "" X
 SG_ DAS_w058_epbMia: 57|1@1+ (1,0) [0|0] "" X
 SG_ DAS_w059_parkMia: 58|1@1+ (1,0) [0|0] "" X
 SG_ DAS_w060_fcw_event: 59|1@1+ (1,0) [0|0] "" X
 SG_ DAS_w061_airSuspensionMia: 60|1@1+ (1,0) [0|0] "" X
 SG_ DAS_w062_radcAlignment: 61|1@1+ (1,0) [0|0] "" X
 SG_ DAS_w063_parkVersionMismatch: 62|1@1+ (1,0) [0|0] "" X
 SG_ DAS_w064_epasMia: 63|1@1+ (1,0) [0|0] "" X

BO_ 873 DAS_warningMatrix1: 8 ETH
 SG_ DAS_w065_deserializerOvercurrent: 0|1@1+ (1,0) [0|0] "" X
 SG_ DAS_w066_deserializerLockLost: 1|1@1+ (1,0) [0|0] "" X
 SG_ DAS_w067_steeringAlignment: 2|1@1+ (1,0) [0|0] "" X
 SG_ DAS_w068_vlInconsistency: 3|1@1+ (1,0) [0|0] "" X
 SG_ DAS_w069_apcSpaceMasked: 4|1@1+ (1,0) [0|0] "" X
 SG_ DAS_w070_apcIncompleteCal: 5|1@1+ (1,0) [0|0] "" X
 SG_ DAS_w071_selfparkStarted: 6|1@1+ (1,0) [0|0] "" X
 SG_ DAS_w072_selfparkComplete: 7|1@1+ (1,0) [0|0] "" X
 SG_ DAS_w073_issueEscalatedLDW: 8|1@1+ (1,0) [0|0] "" X
 SG_ DAS_w074_inPathStationaryObst: 9|1@1+ (1,0) [0|0] "" X
 SG_ DAS_w075_scMia: 10|1@1+ (1,0) [0|0] "" X
 SG_ DAS_w076_mobilEyeSetC: 11|1@1+ (1,0) [0|0] "" X
 SG_ DAS_w077_pmmActive: 12|1@1+ (1,0) [0|0] "" X
 SG_ DAS_w078_pmmActive2: 13|1@1+ (1,0) [0|0] "" X
 SG_ DAS_w079_edrAvailable: 14|1@1+ (1,0) [0|0] "" X
 SG_ DAS_w080_accFailedActivation: 15|1@1+ (1,0) [0|0] "" X
 SG_ DAS_w081_pmmActiveBraking: 16|1@1+ (1,0) [0|0] "" X
 SG_ DAS_w082_inPathFSviolation: 17|1@1+ (1,0) [0|0] "" X
 SG_ DAS_w083_inPathRADObject: 18|1@1+ (1,0) [0|0] "" X
 SG_ DAS_w084_pmmIPSO: 19|1@1+ (1,0) [0|0] "" X
 SG_ DAS_w085_pmmSteering: 20|1@1+ (1,0) [0|0] "" X
 SG_ DAS_w086_robCollision: 21|1@1+ (1,0) [0|0] "" X
 SG_ DAS_w087_DEPRECATED: 22|1@1+ (1,0) [0|0] "" X
 SG_ DAS_w088_DEPRECATED: 23|1@1+ (1,0) [0|0] "" X
 SG_ DAS_w089_DEPRECATED: 24|1@1+ (1,0) [0|0] "" X
 SG_ DAS_w090_DEPRECATED: 25|1@1+ (1,0) [0|0] "" X
 SG_ DAS_w091_DEPRECATED: 26|1@1+ (1,0) [0|0] "" X
 SG_ DAS_w092_DEPRECATED: 27|1@1+ (1,0) [0|0] "" X
 SG_ DAS_w093_DEPRECATED: 28|1@1+ (1,0) [0|0] "" X
 SG_ DAS_w094_DEPRECATED: 29|1@1+ (1,0) [0|0] "" X
 SG_ DAS_w095_DEPRECATED: 30|1@1+ (1,0) [0|0] "" X
 SG_ DAS_w096_DEPRECATED: 31|1@1+ (1,0) [0|0] "" X
 SG_ DAS_w097_DEPRECATED: 32|1@1+ (1,0) [0|0] "" X
 SG_ DAS_w098_DEPRECATED: 33|1@1+ (1,0) [0|0] "" X
 SG_ DAS_w099_DEPRECATED: 34|1@1+ (1,0) [0|0] "" X
 SG_ DAS_w100_DEPRECATED: 35|1@1+ (1,0) [0|0] "" X
 SG_ DAS_w101_DEPRECATED: 36|1@1+ (1,0) [0|0] "" X
 SG_ DAS_w102_DEPRECATED: 37|1@1+ (1,0) [0|0] "" X
 SG_ DAS_w103_robExperimentalAEB: 38|1@1+ (1,0) [0|0] "" X
 SG_ DAS_w104_DEPRECATED: 39|1@1+ (1,0) [0|0] "" X
 SG_ DAS_w105_DEPRECATED: 40|1@1+ (1,0) [0|0] "" X
 SG_ DAS_w106_torsionBarCalibrated: 41|1@1+ (1,0) [0|0] "" X

BO_ 841 DAS_warningMatrix3: 8 ETH
 SG_ DAS_w193_camWindshieldUnclean: 0|1@1+ (1,0) [0|0] "" X
 SG_ DAS_w194_accDriverResumeRqrd: 1|1@1+ (1,0) [0|0] "" X
 SG_ DAS_w195_scwUnavailable: 2|1@1+ (1,0) [0|0] "" X
 SG_ DAS_w196_stopSignWarning: 3|1@1+ (1,0) [0|0] "" X
 SG_ DAS_w197_redLightWarning: 4|1@1+ (1,0) [0|0] "" X
 SG_ DAS_w198_tsrUnavailable: 5|1@1+ (1,0) [0|0] "" X
 SG_ DAS_w199_apcAbort: 6|1@1+ (1,0) [0|0] "" X
 SG_ DAS_w200_lcSlowdown: 7|1@1+ (1,0) [0|0] "" X
 SG_ DAS_w201_lcAborting: 8|1@1+ (1,0) [0|0] "" X
 SG_ DAS_w202_scwNoisyEnvironment: 9|1@1+ (1,0) [0|0] "" X
 SG_ DAS_w203_apcActivation: 10|1@1+ (1,0) [0|0] "" X
 SG_ DAS_w204_apcFinalFront: 11|1@1+ (1,0) [0|0] "" X
 SG_ DAS_w205_apcFinalRear: 12|1@1+ (1,0) [0|0] "" X
 SG_ DAS_w206_autosteerNotEnabled: 13|1@1+ (1,0) [0|0] "" X
 SG_ DAS_w207_autosteerUnavailable: 14|1@1+ (1,0) [0|0] "" X
 SG_ DAS_w208_rackDetected: 15|1@1+ (1,0) [0|0] "" X
 SG_ DAS_w209_autoSummonRequest: 16|1@1+ (1,0) [0|0] "" X
 SG_ DAS_w210_camObstrcted: 17|1@1+ (1,0) [0|0] "" X
 SG_ DAS_w211_accNoSeatBelt: 18|1@1+ (1,0) [0|0] "" X
 SG_ DAS_w212_lcUnavailableStrikeOut: 19|1@1+ (1,0) [0|0] "" X
 SG_ DAS_w213_autosteerStruckOut: 20|1@1+ (1,0) [0|0] "" X
 SG_ DAS_w214_driverNotIntracting: 21|1@1+ (1,0) [0|0] "" X
 SG_ DAS_w215_contDriverNotIntracting: 22|1@1+ (1,0) [0|0] "" X
 SG_ DAS_w216_driverOverriding: 23|1@1+ (1,0) [0|0] "" X
 SG_ DAS_w217_lcUnavailableSpeeding: 24|1@1+ (1,0) [0|0] "" X
 SG_ DAS_w218_lcSpeedExceededLimit: 25|1@1+ (1,0) [0|0] "" X
 SG_ DAS_w219_lcTempUnavailableSpeed: 26|1@1+ (1,0) [0|0] "" X
 SG_ DAS_w220_lcTempUnavailableRoad: 27|1@1+ (1,0) [0|0] "" X
 SG_ DAS_w221_accRadarBlind: 28|1@1+ (1,0) [0|0] "" X
 SG_ DAS_w222_accCameraBlind: 29|1@1+ (1,0) [0|0] "" X
 SG_ DAS_w223_accObjectInPath: 30|1@1+ (1,0) [0|0] "" X
 SG_ DAS_w224_accCameraCalibration: 31|1@1+ (1,0) [0|0] "" X
 SG_ DAS_w225_lcDegradedVisSpeedLmt: 32|1@1+ (1,0) [0|0] "" X
 SG_ DAS_w226_lcCamCalNeededSpeedLmt: 33|1@1+ (1,0) [0|0] "" X
 SG_ DAS_w227_virtualWallBlocked: 34|1@1+ (1,0) [0|0] "" X
 SG_ DAS_w228_DEPRECATED: 35|1@1+ (1,0) [0|0] "" X
 SG_ DAS_w229_alcUltrasoundDamaged: 36|1@1+ (1,0) [0|0] "" X
 SG_ DAS_w230_alcUltrasoundBlocked: 37|1@1+ (1,0) [0|0] "" X
 SG_ DAS_w231_idfEvent: 38|1@1+ (1,0) [0|0] "" X

BO_ 2020 DATLGR_info: 4 ETH
 SG_ DATLGR_serialNum: 0|32@0+ (1,0) [0|0] "" X

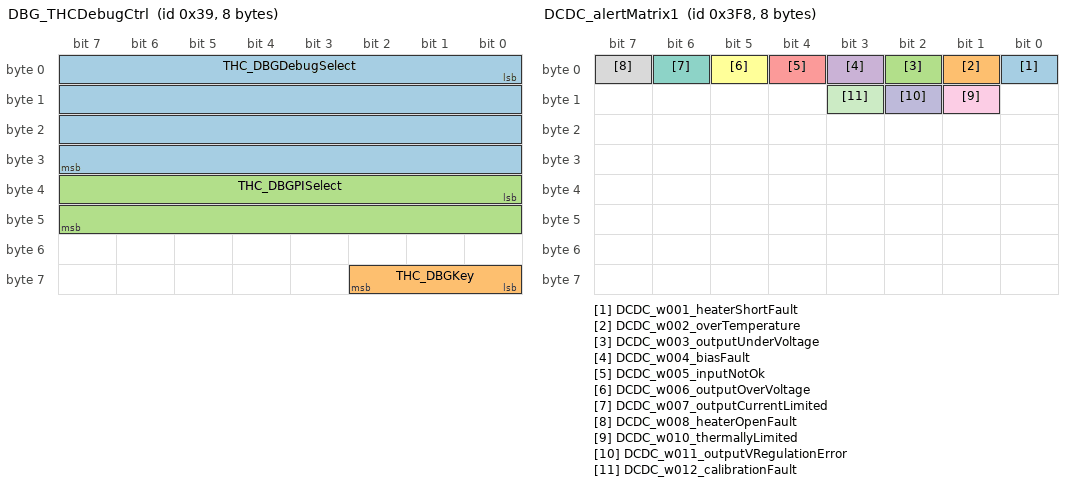
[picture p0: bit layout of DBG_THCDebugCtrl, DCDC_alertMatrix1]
BO_ 57 DBG_THCDebugCtrl: 8 ETH
 SG_ THC_DBGDebugSelect: 0|32@1+ (1,0) [0|0] "" X
 SG_ THC_DBGKey: 56|3@1+ (1,0) [0|0] "" X
 SG_ THC_DBGPISelect: 32|16@1+ (1,0) [0|0] "" X

BO_ 1016 DCDC_alertMatrix1: 8 ETH
 SG_ DCDC_w001_heaterShortFault: 0|1@1+ (1,0) [0|0] "" X
 SG_ DCDC_w002_overTemperature: 1|1@1+ (1,0) [0|0] "" X
 SG_ DCDC_w003_outputUnderVoltage: 2|1@1+ (1,0) [0|0] "" X
 SG_ DCDC_w004_biasFault: 3|1@1+ (1,0) [0|0] "" X
 SG_ DCDC_w005_inputNotOk: 4|1@1+ (1,0) [0|0] "" X
 SG_ DCDC_w006_outputOverVoltage: 5|1@1+ (1,0) [0|0] "" X
 SG_ DCDC_w007_outputCurrentLimited: 6|1@1+ (1,0) [0|0] "" X
 SG_ DCDC_w008_heaterOpenFault: 7|1@1+ (1,0) [0|0] "" X
 SG_ DCDC_w010_thermallyLimited: 9|1@1+ (1,0) [0|0] "" X
 SG_ DCDC_w011_outputVRegulationError: 10|1@1+ (1,0) [0|0] "" X
 SG_ DCDC_w012_calibrationFault: 11|1@1+ (1,0) [0|0] "" X

BO_ 1616 DCDC_info: 8 ETH
 SG_ DCDC_infoIndex M: 0|8@1+ (1,0) [0|0] "" X
 SG_ DCDC_buildType m0: 8|2@1+ (1,0) [0|0] "" X
 SG_ DCDC_buildConfiguration m0: 16|16@1+ (1,0) [0|0] "" X
 SG_ DCDC_binaryCRC m0: 32|32@1+ (1,0) [0|0] "" X
 SG_ DCDC_bootloaderSvnRevision m1: 8|24@1+ (1,0) [0|0] "" X
 SG_ DCDC_bootloaderSvnUrlHash m1: 32|32@1+ (1,0) [0|0] "" X
 SG_ DCDC_appComponentID m2: 16|16@1+ (1,0) [0|0] "" X
 SG_ DCDC_pcbaPlusAssemblyID m3: 16|16@1+ (1,0) [0|0] "" X
 SG_ DCDC_usagePlusSubusageID m3: 32|32@1+ (1,0) [0|0] "" X
 SG_ DCDC_componentSvnRevision m4: 8|24@1+ (1,0) [0|0] "" X
 SG_ DCDC_componentSvnUrlHash m4: 32|32@1+ (1,0) [0|0] "" X

BO_ 528 DCDC_statusPartial: 2 ETH
 SG_ DCDC_outputCurrent: 0|8@1+ (1,0) [0|0] "A" X
 SG_ DCDC_outputVoltage: 8|8@1+ (0.1,0) [0|0] "V" X

BO_ 1552 DCDC_udsResponse: 8 ETH
 SG_ DCDC_udsResponseData: 0|54@0+ (1024,0) [0|0] "" X

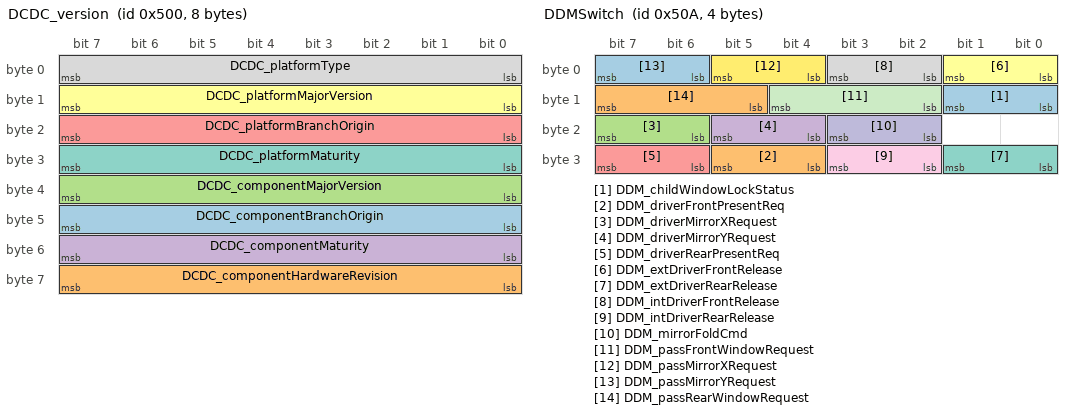
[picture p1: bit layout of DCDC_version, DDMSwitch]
BO_ 1280 DCDC_version: 8 ETH
 SG_ DCDC_componentBranchOrigin: 40|8@1+ (1,0) [0|0] "" X
 SG_ DCDC_componentHardwareRevision: 56|8@1+ (1,0) [0|0] "" X
 SG_ DCDC_componentMajorVersion: 32|8@1+ (1,0) [0|0] "" X
 SG_ DCDC_componentMaturity: 48|8@1+ (1,0) [0|0] "" X
 SG_ DCDC_platformBranchOrigin: 16|8@1+ (1,0) [0|0] "" X
 SG_ DCDC_platformMajorVersion: 8|8@1+ (1,0) [0|0] "" X
 SG_ DCDC_platformMaturity: 24|8@1+ (1,0) [0|0] "" X
 SG_ DCDC_platformType: 0|8@1+ (1,0) [0|0] "" X

BO_ 100 DDMStatus_partial: 1 ETH
 SG_ DDM_driverRepeaterState: 0|2@1+ (1,0) [0|0] "" X

BO_ 1290 DDMSwitch: 4 ETH
 SG_ DDM_childWindowLockStatus: 8|2@1+ (1,0) [0|0] "" X
 SG_ DDM_driverFrontPresentReq: 28|2@1+ (1,0) [0|0] "" X
 SG_ DDM_driverMirrorXRequest: 22|2@1+ (1,0) [0|0] "" X
 SG_ DDM_driverMirrorYRequest: 20|2@1+ (1,0) [0|0] "" X
 SG_ DDM_driverRearPresentReq: 30|2@1+ (1,0) [0|0] "" X
 SG_ DDM_extDriverFrontRelease: 0|2@1+ (1,0) [0|0] "" X
 SG_ DDM_extDriverRearRelease: 24|2@1+ (1,0) [0|0] "" X
 SG_ DDM_intDriverFrontRelease: 2|2@1+ (1,0) [0|0] "" X
 SG_ DDM_intDriverRearRelease: 26|2@1+ (1,0) [0|0] "" X
 SG_ DDM_mirrorFoldCmd: 18|2@1+ (1,0) [0|0] "" X
 SG_ DDM_passFrontWindowRequest: 10|3@1+ (1,0) [0|0] "" X
 SG_ DDM_passMirrorXRequest: 4|2@1+ (1,0) [0|0] "" X
 SG_ DDM_passMirrorYRequest: 6|2@1+ (1,0) [0|0] "" X
 SG_ DDM_passRearWindowRequest: 13|3@1+ (1,0) [0|0] "" X

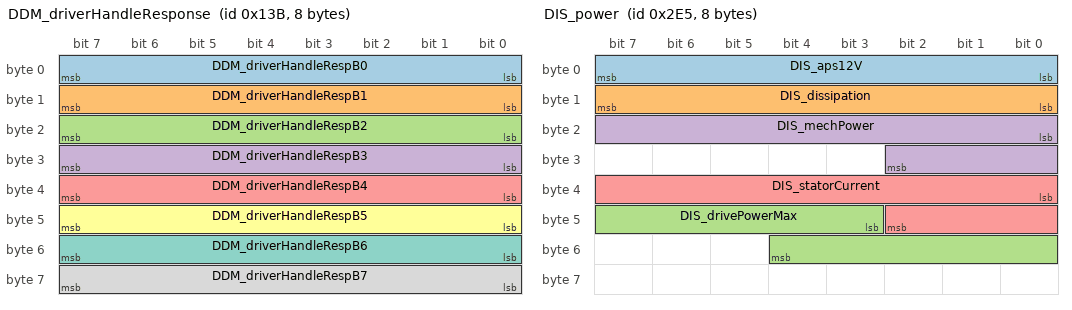
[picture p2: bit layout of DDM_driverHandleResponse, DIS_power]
BO_ 315 DDM_driverHandleResponse: 8 ETH
 SG_ DDM_driverHandleRespB0: 0|8@1+ (1,0) [0|0] "" X
 SG_ DDM_driverHandleRespB1: 8|8@1+ (1,0) [0|0] "" X
 SG_ DDM_driverHandleRespB2: 16|8@1+ (1,0) [0|0] "" X
 SG_ DDM_driverHandleRespB3: 24|8@1+ (1,0) [0|0] "" X
 SG_ DDM_driverHandleRespB4: 32|8@1+ (1,0) [0|0] "" X
 SG_ DDM_driverHandleRespB5: 40|8@1+ (1,0) [0|0] "" X
 SG_ DDM_driverHandleRespB6: 48|8@1+ (1,0) [0|0] "" X
 SG_ DDM_driverHandleRespB7: 56|8@1+ (1,0) [0|0] "" X

BO_ 554 DDM_frontHandleStatus: 8 ETH
 SG_ DF_componentHardwareId: 8|8@1+ (1,0) [0|0] "" X
 SG_ DF_componentMajorVersion: 16|8@1+ (1,0) [0|0] "" X
 SG_ DF_componentMinorVersion: 24|8@1+ (1,0) [0|0] "" X
 SG_ DF_errorResp: 0|1@1+ (1,0) [0|0] "" X
 SG_ DF_mainState: 48|8@1+ (1,0) [0|0] "" X
 SG_ DF_motorState: 56|8@1+ (1,0) [0|0] "" X
 SG_ DF_presentReq: 3|1@1+ (1,0) [0|0] "" X
 SG_ DF_releaseReq: 2|1@1+ (1,0) [0|0] "" X
 SG_ DF_svnOrAngle: 32|16@0+ (1,0) [0|0] "" X
 SG_ DF_targetPosition: 4|4@1+ (1,0) [0|0] "" X

BO_ 570 DDM_rearHandleStatus: 8 ETH
 SG_ DR_componentHardwareId: 8|8@1+ (1,0) [0|0] "" X
 SG_ DR_componentMajorVersion: 16|8@1+ (1,0) [0|0] "" X
 SG_ DR_componentMinorVersion: 24|8@1+ (1,0) [0|0] "" X
 SG_ DR_errorResp: 0|1@1+ (1,0) [0|0] "" X
 SG_ DR_mainState: 48|8@1+ (1,0) [0|0] "" X
 SG_ DR_motorState: 56|8@1+ (1,0) [0|0] "" X
 SG_ DR_presentReq: 3|1@1+ (1,0) [0|0] "" X
 SG_ DR_releaseReq: 2|1@1+ (1,0) [0|0] "" X
 SG_ DR_svnOrAngle: 32|16@0+ (1,0) [0|0] "" X
 SG_ DR_targetPosition: 4|4@1+ (1,0) [0|0] "" X

BO_ 1690 DDM_udsResponse: 8 ETH
 SG_ DDM_udsResponseData: 0|54@0+ (1024,0) [0|0] "" X

BO_ 1306 DDM_version: 8 ETH
 SG_ DDM_componentBranchOrigin: 40|8@1+ (1,0) [0|0] "" X
 SG_ DDM_componentHardwareRevision: 56|8@1+ (1,0) [0|0] "" X
 SG_ DDM_componentMajorVersion: 32|8@1+ (1,0) [0|0] "" X
 SG_ DDM_componentMaturity: 48|8@1+ (1,0) [0|0] "" X
 SG_ DDM_componentSvn: 8|24@0+ (1,0) [0|0] "" X
 SG_ DDM_platformType: 0|8@1+ (1,0) [0|0] "" X

BO_ 934 DIS_alertMatrix1: 8 ETH
 SG_ DIS_f001_hwPhaseAgateDrive: 0|1@1+ (1,0) [0|0] "" X
 SG_ DIS_f002_hwPhaseBgateDrive: 1|1@1+ (1,0) [0|0] "" X
 SG_ DIS_f003_hwPhaseCgateDrive: 2|1@1+ (1,0) [0|0] "" X
 SG_ DIS_f004_hwPhaseApeak: 3|1@1+ (1,0) [0|0] "" X
 SG_ DIS_f005_hwPhaseBpeak: 4|1@1+ (1,0) [0|0] "" X
 SG_ DIS_f006_hwPhaseCpeak: 5|1@1+ (1,0) [0|0] "" X
 SG_ DIS_f007_hwHvilNotPresent: 6|1@1+ (1,0) [0|0] "" X
 SG_ DIS_f008_hwEncoderA: 7|1@1+ (1,0) [0|0] "" X
 SG_ DIS_f009_hwEncoderB: 8|1@1+ (1,0) [0|0] "" X
 SG_ DIS_f010_hwPedalMonitorReset: 9|1@1+ (1,0) [0|0] "" X
 SG_ DIS_f011_swPowerStageNotReady: 10|1@1+ (1,0) [0|0] "" X
 SG_ DIS_f012_accel5VSupply: 11|1@1+ (1,0) [0|0] "" X
 SG_ DIS_f013_powerPcbSensor: 12|1@1+ (1,0) [0|0] "" X
 SG_ DIS_f014_activeDamping: 13|1@1+ (1,0) [0|0] "" X
 SG_ DIS_f015_immobilizer: 14|1@1+ (1,0) [0|0] "" X
 SG_ DIS_f016_safeStateApplied: 15|1@1+ (1,0) [0|0] "" X
 SG_ DIS_f017_hwPedalMonitor: 16|1@1+ (1,0) [0|0] "" X
 SG_ DIS_f018_hw12vSupplyUV: 17|1@1+ (1,0) [0|0] "" X
 SG_ DIS_f019_hwAccelPedalPower: 18|1@1+ (1,0) [0|0] "" X
 SG_ DIS_f020_hwMotorEncoder: 19|1@1+ (1,0) [0|0] "" X
 SG_ DIS_f021_hwBusOV: 20|1@1+ (1,0) [0|0] "" X
 SG_ DIS_f022_hw5vSupplyUV: 21|1@1+ (1,0) [0|0] "" X
 SG_ DIS_f023_carNotParked: 22|1@1+ (1,0) [0|0] "" X
 SG_ DIS_f024_selfTest: 23|1@1+ (1,0) [0|0] "" X
 SG_ DIS_f025_phaseApeak: 24|1@1+ (1,0) [0|0] "" X
 SG_ DIS_f026_phaseBpeak: 25|1@1+ (1,0) [0|0] "" X
 SG_ DIS_f027_phaseCpeak: 26|1@1+ (1,0) [0|0] "" X
 SG_ DIS_f028_phaseArms: 27|1@1+ (1,0) [0|0] "" X
 SG_ DIS_f029_phaseBrms: 28|1@1+ (1,0) [0|0] "" X
 SG_ DIS_f030_phaseCrms: 29|1@1+ (1,0) [0|0] "" X
 SG_ DIS_f031_phaseAcurrentOffset: 30|1@1+ (1,0) [0|0] "" X
 SG_ DIS_f032_phaseBcurrentOffset: 31|1@1+ (1,0) [0|0] "" X
 SG_ DIS_f033_phaseAcurrentSensor: 32|1@1+ (1,0) [0|0] "" X
 SG_ DIS_f034_phaseBcurrentSensor: 33|1@1+ (1,0) [0|0] "" X
 SG_ DIS_f035_phaseCurrentBalance: 34|1@1+ (1,0) [0|0] "" X
 SG_ DIS_f036_busOV: 35|1@1+ (1,0) [0|0] "" X
 SG_ DIS_f037_busUV: 36|1@1+ (1,0) [0|0] "" X
 SG_ DIS_f038_busVsensor: 37|1@1+ (1,0) [0|0] "" X
 SG_ DIS_f039_regenLimited: 38|1@1+ (1,0) [0|0] "" X
 SG_ DIS_f040_disMIA: 39|1@1+ (1,0) [0|0] "" X
 SG_ DIS_f041_hwFloodDetection: 40|1@1+ (1,0) [0|0] "" X
 SG_ DIS_f042_inletSensor: 41|1@1+ (1,0) [0|0] "" X
 SG_ DIS_f043_outletOT: 42|1@1+ (1,0) [0|0] "" X
 SG_ DIS_f044_outletUT: 43|1@1+ (1,0) [0|0] "" X
 SG_ DIS_f045_outletSensor: 44|1@1+ (1,0) [0|0] "" X
 SG_ DIS_f046_statorOT: 45|1@1+ (1,0) [0|0] "" X
 SG_ DIS_f047_statorSensor1: 46|1@1+ (1,0) [0|0] "" X
 SG_ DIS_f048_statorSensor2: 47|1@1+ (1,0) [0|0] "" X
 SG_ DIS_f049_statorSensorDiff: 48|1@1+ (1,0) [0|0] "" X
 SG_ DIS_f050_noStatorSensor: 49|1@1+ (1,0) [0|0] "" X
 SG_ DIS_f051_batteryOvercurrent: 50|1@1+ (1,0) [0|0] "" X
 SG_ DIS_f052_rotorBrazeFail: 51|1@1+ (1,0) [0|0] "" X
 SG_ DIS_f053_externalAlert: 52|1@1+ (1,0) [0|0] "" X
 SG_ DIS_f054_driveInverterOT: 53|1@1+ (1,0) [0|0] "" X
 SG_ DIS_f055_trqCrossCheck: 54|1@1+ (1,0) [0|0] "" X
 SG_ DIS_f056_ambientOT: 55|1@1+ (1,0) [0|0] "" X
 SG_ DIS_f057_ambientUT: 56|1@1+ (1,0) [0|0] "" X
 SG_ DIS_f058_ambientSensor: 57|1@1+ (1,0) [0|0] "" X
 SG_ DIS_f059_heatsinkOT: 58|1@1+ (1,0) [0|0] "" X
 SG_ DIS_f060_heatsinkUT: 59|1@1+ (1,0) [0|0] "" X
 SG_ DIS_f061_heatsinkSensor: 60|1@1+ (1,0) [0|0] "" X
 SG_ DIS_f062_systemLimpMode: 61|1@1+ (1,0) [0|0] "" X
 SG_ DIS_f063_systemGracefulPowerOff: 62|1@1+ (1,0) [0|0] "" X
 SG_ DIS_f064_torqueIntervention: 63|1@1+ (1,0) [0|0] "" X

BO_ 950 DIS_alertMatrix2: 8 ETH
 SG_ DIS_f065_unused65: 0|1@1+ (1,0) [0|0] "" X
 SG_ DIS_f066_unused66: 1|1@1+ (1,0) [0|0] "" X
 SG_ DIS_f067_unused67: 2|1@1+ (1,0) [0|0] "" X
 SG_ DIS_f068_stwAngleMIA: 3|1@1+ (1,0) [0|0] "" X
 SG_ DIS_f069_securityControlMIA: 4|1@1+ (1,0) [0|0] "" X
 SG_ DIS_f070_12vSupplySensor: 5|1@1+ (1,0) [0|0] "" X
 SG_ DIS_f071_busDisconnected: 6|1@1+ (1,0) [0|0] "" X
 SG_ DIS_f072_gateDriveFaultCounter: 7|1@1+ (1,0) [0|0] "" X
 SG_ DIS_f073_motorSpeed: 8|1@1+ (1,0) [0|0] "" X
 SG_ DIS_f074_motorEncoder: 9|1@1+ (1,0) [0|0] "" X
 SG_ DIS_f075_motorSpeedMismatch: 10|1@1+ (1,0) [0|0] "" X
 SG_ DIS_f076_12vSupplyOV: 11|1@1+ (1,0) [0|0] "" X
 SG_ DIS_f077_12vSupplyUV: 12|1@1+ (1,0) [0|0] "" X
 SG_ DIS_f078_adcRefLow: 13|1@1+ (1,0) [0|0] "" X
 SG_ DIS_f079_adcRefHigh: 14|1@1+ (1,0) [0|0] "" X
 SG_ DIS_f080_accelSynch: 15|1@1+ (1,0) [0|0] "" X
 SG_ DIS_f081_accelTrack1: 16|1@1+ (1,0) [0|0] "" X
 SG_ DIS_f082_accelTrack2: 17|1@1+ (1,0) [0|0] "" X
 SG_ DIS_f083_brakePedalSensor: 18|1@1+ (1,0) [0|0] "" X
 SG_ DIS_f084_batteryCurrentEstimate: 19|1@1+ (1,0) [0|0] "" X
 SG_ DIS_f085_proximityInEnable: 20|1@1+ (1,0) [0|0] "" X
 SG_ DIS_f086_hvilNotPresent: 21|1@1+ (1,0) [0|0] "" X
 SG_ DIS_f087_gtwMIA: 22|1@1+ (1,0) [0|0] "" X
 SG_ DIS_f088_mcuMIA: 23|1@1+ (1,0) [0|0] "" X
 SG_ DIS_f089_shifterMIA: 24|1@1+ (1,0) [0|0] "" X
 SG_ DIS_f090_pmMIA: 25|1@1+ (1,0) [0|0] "" X
 SG_ DIS_f091_espMIA: 26|1@1+ (1,0) [0|0] "" X
 SG_ DIS_f092_bmsMIA: 27|1@1+ (1,0) [0|0] "" X
 SG_ DIS_f093_canHardware: 28|1@1+ (1,0) [0|0] "" X
 SG_ DIS_f094_canData: 29|1@1+ (1,0) [0|0] "" X
 SG_ DIS_f095_canOverrun: 30|1@1+ (1,0) [0|0] "" X
 SG_ DIS_f096_memoryError: 31|1@1+ (1,0) [0|0] "" X
 SG_ DIS_f097_eepromError: 32|1@1+ (1,0) [0|0] "" X
 SG_ DIS_f098_intTimeTooLong: 33|1@1+ (1,0) [0|0] "" X
 SG_ DIS_f099_threadOverrun: 34|1@1+ (1,0) [0|0] "" X
 SG_ DIS_f100_assertion: 35|1@1+ (1,0) [0|0] "" X
 SG_ DIS_f101_cruiseInputInvalid: 36|1@1+ (1,0) [0|0] "" X
 SG_ DIS_f102_shiftInputInvalid: 37|1@1+ (1,0) [0|0] "" X
 SG_ DIS_f103_lowFlow: 38|1@1+ (1,0) [0|0] "" X
 SG_ DIS_f104_proximityIrrational: 39|1@1+ (1,0) [0|0] "" X
 SG_ DIS_f105_chgMIA: 40|1@1+ (1,0) [0|0] "" X
 SG_ DIS_f106_absMIA: 41|1@1+ (1,0) [0|0] "" X
 SG_ DIS_f107_fpgaError: 42|1@1+ (1,0) [0|0] "" X
 SG_ DIS_f108_stateTrans: 43|1@1+ (1,0) [0|0] "" X
 SG_ DIS_f109_cruiseMIA: 44|1@1+ (1,0) [0|0] "" X
 SG_ DIS_f110_brakeMIA: 45|1@1+ (1,0) [0|0] "" X
 SG_ DIS_f111_badPhaseSensorCalib: 46|1@1+ (1,0) [0|0] "" X
 SG_ DIS_f112_noPhaseCurrent: 47|1@1+ (1,0) [0|0] "" X
 SG_ DIS_f113_noFuncHeatsinkSensor: 48|1@1+ (1,0) [0|0] "" X
 SG_ DIS_f114_noMotorSpeed: 49|1@1+ (1,0) [0|0] "" X
 SG_ DIS_f115_heatsinkTempImbalance: 50|1@1+ (1,0) [0|0] "" X
 SG_ DIS_f116_powerConvIrrational: 51|1@1+ (1,0) [0|0] "" X
 SG_ DIS_f117_diMIA: 52|1@1+ (1,0) [0|0] "" X
 SG_ DIS_f118_canBusHeavy: 53|1@1+ (1,0) [0|0] "" X
 SG_ DIS_f119_canBusLight: 54|1@1+ (1,0) [0|0] "" X
 SG_ DIS_f120_canBusOff: 55|1@1+ (1,0) [0|0] "" X
 SG_ DIS_f121_motorControlRegulation: 56|1@1+ (1,0) [0|0] "" X
 SG_ DIS_f122_highStackUsage: 57|1@1+ (1,0) [0|0] "" X
 SG_ DIS_f123_lossMotorControl: 58|1@1+ (1,0) [0|0] "" X
 SG_ DIS_f124_cruiseFault: 59|1@1+ (1,0) [0|0] "" X
 SG_ DIS_f125_noBatteryPower: 60|1@1+ (1,0) [0|0] "" X
 SG_ DIS_f126_limpMode: 61|1@1+ (1,0) [0|0] "" X
 SG_ DIS_f127_gracefulPowerOff: 62|1@1+ (1,0) [0|0] "" X
 SG_ DIS_f128_fpgaVersionMismatch: 63|1@1+ (1,0) [0|0] "" X

BO_ 966 DIS_alertMatrix3: 8 ETH
 SG_ DIS_w001_hwPhaseAgateDrive: 0|1@1+ (1,0) [0|0] "" X
 SG_ DIS_w002_hwPhaseBgateDrive: 1|1@1+ (1,0) [0|0] "" X
 SG_ DIS_w003_hwPhaseCgateDrive: 2|1@1+ (1,0) [0|0] "" X
 SG_ DIS_w004_hwPhaseApeak: 3|1@1+ (1,0) [0|0] "" X
 SG_ DIS_w005_hwPhaseBpeak: 4|1@1+ (1,0) [0|0] "" X
 SG_ DIS_w006_hwPhaseCpeak: 5|1@1+ (1,0) [0|0] "" X
 SG_ DIS_w007_hwHvilNotPresent: 6|1@1+ (1,0) [0|0] "" X
 SG_ DIS_w008_hwEncoderA: 7|1@1+ (1,0) [0|0] "" X
 SG_ DIS_w009_hwEncoderB: 8|1@1+ (1,0) [0|0] "" X
 SG_ DIS_w010_hwPedalMonitorReset: 9|1@1+ (1,0) [0|0] "" X
 SG_ DIS_w011_swPowerStageNotReady: 10|1@1+ (1,0) [0|0] "" X
 SG_ DIS_w012_accel5VSupply: 11|1@1+ (1,0) [0|0] "" X
 SG_ DIS_w013_powerPcbSensor: 12|1@1+ (1,0) [0|0] "" X
 SG_ DIS_w014_activeDamping: 13|1@1+ (1,0) [0|0] "" X
 SG_ DIS_w015_immobilizer: 14|1@1+ (1,0) [0|0] "" X
 SG_ DIS_w016_safeStateApplied: 15|1@1+ (1,0) [0|0] "" X
 SG_ DIS_w017_hwPedalMonitor: 16|1@1+ (1,0) [0|0] "" X
 SG_ DIS_w018_hw12vSupplyUV: 17|1@1+ (1,0) [0|0] "" X
 SG_ DIS_w019_hwAccelPedalPower: 18|1@1+ (1,0) [0|0] "" X
 SG_ DIS_w020_hwMotorEncoder: 19|1@1+ (1,0) [0|0] "" X
 SG_ DIS_w021_hwBusOV: 20|1@1+ (1,0) [0|0] "" X
 SG_ DIS_w022_hw5vSupplyUV: 21|1@1+ (1,0) [0|0] "" X
 SG_ DIS_w023_carNotParked: 22|1@1+ (1,0) [0|0] "" X
 SG_ DIS_w024_selfTest: 23|1@1+ (1,0) [0|0] "" X
 SG_ DIS_w025_phaseApeak: 24|1@1+ (1,0) [0|0] "" X
 SG_ DIS_w026_phaseBpeak: 25|1@1+ (1,0) [0|0] "" X
 SG_ DIS_w027_phaseCpeak: 26|1@1+ (1,0) [0|0] "" X
 SG_ DIS_w028_phaseArms: 27|1@1+ (1,0) [0|0] "" X
 SG_ DIS_w029_phaseBrms: 28|1@1+ (1,0) [0|0] "" X
 SG_ DIS_w030_phaseCrms: 29|1@1+ (1,0) [0|0] "" X
 SG_ DIS_w031_phaseAcurrentOffset: 30|1@1+ (1,0) [0|0] "" X
 SG_ DIS_w032_phaseBcurrentOffset: 31|1@1+ (1,0) [0|0] "" X
 SG_ DIS_w033_phaseAcurrentSensor: 32|1@1+ (1,0) [0|0] "" X
 SG_ DIS_w034_phaseBcurrentSensor: 33|1@1+ (1,0) [0|0] "" X
 SG_ DIS_w035_phaseCurrentBalance: 34|1@1+ (1,0) [0|0] "" X
 SG_ DIS_w036_busOV: 35|1@1+ (1,0) [0|0] "" X
 SG_ DIS_w037_busUV: 36|1@1+ (1,0) [0|0] "" X
 SG_ DIS_w038_busVsensor: 37|1@1+ (1,0) [0|0] "" X
 SG_ DIS_w039_regenLimited: 38|1@1+ (1,0) [0|0] "" X
 SG_ DIS_w040_disMIA: 39|1@1+ (1,0) [0|0] "" X
 SG_ DIS_w041_hwFloodDetection: 40|1@1+ (1,0) [0|0] "" X
 SG_ DIS_w042_inletSensor: 41|1@1+ (1,0) [0|0] "" X
 SG_ DIS_w043_outletOT: 42|1@1+ (1,0) [0|0] "" X
 SG_ DIS_w044_outletUT: 43|1@1+ (1,0) [0|0] "" X
 SG_ DIS_w045_outletSensor: 44|1@1+ (1,0) [0|0] "" X
 SG_ DIS_w046_statorOT: 45|1@1+ (1,0) [0|0] "" X
 SG_ DIS_w047_statorSensor1: 46|1@1+ (1,0) [0|0] "" X
 SG_ DIS_w048_statorSensor2: 47|1@1+ (1,0) [0|0] "" X
 SG_ DIS_w049_statorSensorDiff: 48|1@1+ (1,0) [0|0] "" X
 SG_ DIS_w050_noStatorSensor: 49|1@1+ (1,0) [0|0] "" X
 SG_ DIS_w051_batteryOvercurrent: 50|1@1+ (1,0) [0|0] "" X
 SG_ DIS_w052_rotorBrazeFail: 51|1@1+ (1,0) [0|0] "" X
 SG_ DIS_w053_externalAlert: 52|1@1+ (1,0) [0|0] "" X
 SG_ DIS_w054_driveInverterOT: 53|1@1+ (1,0) [0|0] "" X
 SG_ DIS_w055_trqCrossCheck: 54|1@1+ (1,0) [0|0] "" X
 SG_ DIS_w056_ambientOT: 55|1@1+ (1,0) [0|0] "" X
 SG_ DIS_w057_ambientUT: 56|1@1+ (1,0) [0|0] "" X
 SG_ DIS_w058_ambientSensor: 57|1@1+ (1,0) [0|0] "" X
 SG_ DIS_w059_heatsinkOT: 58|1@1+ (1,0) [0|0] "" X
 SG_ DIS_w060_heatsinkUT: 59|1@1+ (1,0) [0|0] "" X
 SG_ DIS_w061_heatsinkSensor: 60|1@1+ (1,0) [0|0] "" X
 SG_ DIS_w062_systemLimpMode: 61|1@1+ (1,0) [0|0] "" X
 SG_ DIS_w063_systemGracefulPowerOff: 62|1@1+ (1,0) [0|0] "" X
 SG_ DIS_w064_torqueIntervention: 63|1@1+ (1,0) [0|0] "" X

BO_ 982 DIS_alertMatrix4: 8 ETH
 SG_ DIS_w065_unused65: 0|1@1+ (1,0) [0|0] "" X
 SG_ DIS_w066_unused66: 1|1@1+ (1,0) [0|0] "" X
 SG_ DIS_w067_unused67: 2|1@1+ (1,0) [0|0] "" X
 SG_ DIS_w068_stwAngleMIA: 3|1@1+ (1,0) [0|0] "" X
 SG_ DIS_w069_securityControlMIA: 4|1@1+ (1,0) [0|0] "" X
 SG_ DIS_w070_12vSupplySensor: 5|1@1+ (1,0) [0|0] "" X
 SG_ DIS_w071_busDisconnected: 6|1@1+ (1,0) [0|0] "" X
 SG_ DIS_w072_gateDriveFaultCounter: 7|1@1+ (1,0) [0|0] "" X
 SG_ DIS_w073_motorSpeed: 8|1@1+ (1,0) [0|0] "" X
 SG_ DIS_w074_motorEncoder: 9|1@1+ (1,0) [0|0] "" X
 SG_ DIS_w075_motorSpeedMismatch: 10|1@1+ (1,0) [0|0] "" X
 SG_ DIS_w076_12vSupplyOV: 11|1@1+ (1,0) [0|0] "" X
 SG_ DIS_w077_12vSupplyUV: 12|1@1+ (1,0) [0|0] "" X
 SG_ DIS_w078_adcRefLow: 13|1@1+ (1,0) [0|0] "" X
 SG_ DIS_w079_adcRefHigh: 14|1@1+ (1,0) [0|0] "" X
 SG_ DIS_w080_accelSynch: 15|1@1+ (1,0) [0|0] "" X
 SG_ DIS_w081_accelTrack1: 16|1@1+ (1,0) [0|0] "" X
 SG_ DIS_w082_accelTrack2: 17|1@1+ (1,0) [0|0] "" X
 SG_ DIS_w083_brakePedalSensor: 18|1@1+ (1,0) [0|0] "" X
 SG_ DIS_w084_batteryCurrentEstimate: 19|1@1+ (1,0) [0|0] "" X
 SG_ DIS_w085_proximityInEnable: 20|1@1+ (1,0) [0|0] "" X
 SG_ DIS_w086_hvilNotPresent: 21|1@1+ (1,0) [0|0] "" X
 SG_ DIS_w087_gtwMIA: 22|1@1+ (1,0) [0|0] "" X
 SG_ DIS_w088_mcuMIA: 23|1@1+ (1,0) [0|0] "" X
 SG_ DIS_w089_shifterMIA: 24|1@1+ (1,0) [0|0] "" X
 SG_ DIS_w090_pmMIA: 25|1@1+ (1,0) [0|0] "" X
 SG_ DIS_w091_espMIA: 26|1@1+ (1,0) [0|0] "" X
 SG_ DIS_w092_bmsMIA: 27|1@1+ (1,0) [0|0] "" X
 SG_ DIS_w093_canHardware: 28|1@1+ (1,0) [0|0] "" X
 SG_ DIS_w094_canData: 29|1@1+ (1,0) [0|0] "" X
 SG_ DIS_w095_canOverrun: 30|1@1+ (1,0) [0|0] "" X
 SG_ DIS_w096_memoryError: 31|1@1+ (1,0) [0|0] "" X
 SG_ DIS_w097_eepromError: 32|1@1+ (1,0) [0|0] "" X
 SG_ DIS_w098_intTimeTooLong: 33|1@1+ (1,0) [0|0] "" X
 SG_ DIS_w099_threadOverrun: 34|1@1+ (1,0) [0|0] "" X
 SG_ DIS_w100_assertion: 35|1@1+ (1,0) [0|0] "" X
 SG_ DIS_w101_cruiseInputInvalid: 36|1@1+ (1,0) [0|0] "" X
 SG_ DIS_w102_shiftInputInvalid: 37|1@1+ (1,0) [0|0] "" X
 SG_ DIS_w103_lowFlow: 38|1@1+ (1,0) [0|0] "" X
 SG_ DIS_w104_proximityIrrational: 39|1@1+ (1,0) [0|0] "" X
 SG_ DIS_w105_chgMIA: 40|1@1+ (1,0) [0|0] "" X
 SG_ DIS_w106_absMIA: 41|1@1+ (1,0) [0|0] "" X
 SG_ DIS_w107_fpgaError: 42|1@1+ (1,0) [0|0] "" X
 SG_ DIS_w108_stateTrans: 43|1@1+ (1,0) [0|0] "" X
 SG_ DIS_w109_cruiseMIA: 44|1@1+ (1,0) [0|0] "" X
 SG_ DIS_w110_brakeMIA: 45|1@1+ (1,0) [0|0] "" X
 SG_ DIS_w111_badPhaseSensorCalib: 46|1@1+ (1,0) [0|0] "" X
 SG_ DIS_w112_noPhaseCurrent: 47|1@1+ (1,0) [0|0] "" X
 SG_ DIS_w113_noFuncHeatsinkSensor: 48|1@1+ (1,0) [0|0] "" X
 SG_ DIS_w114_noMotorSpeed: 49|1@1+ (1,0) [0|0] "" X
 SG_ DIS_w115_heatsinkTempImbalance: 50|1@1+ (1,0) [0|0] "" X
 SG_ DIS_w116_powerConvIrrational: 51|1@1+ (1,0) [0|0] "" X
 SG_ DIS_w117_diMIA: 52|1@1+ (1,0) [0|0] "" X
 SG_ DIS_w118_canBusHeavy: 53|1@1+ (1,0) [0|0] "" X
 SG_ DIS_w119_canBusLight: 54|1@1+ (1,0) [0|0] "" X
 SG_ DIS_w120_canBusOff: 55|1@1+ (1,0) [0|0] "" X
 SG_ DIS_w121_motorControlRegulation: 56|1@1+ (1,0) [0|0] "" X
 SG_ DIS_w122_highStackUsage: 57|1@1+ (1,0) [0|0] "" X
 SG_ DIS_w123_lossMotorControl: 58|1@1+ (1,0) [0|0] "" X
 SG_ DIS_w124_cruiseFault: 59|1@1+ (1,0) [0|0] "" X
 SG_ DIS_w125_noBatteryPower: 60|1@1+ (1,0) [0|0] "" X
 SG_ DIS_w126_limpMode: 61|1@1+ (1,0) [0|0] "" X
 SG_ DIS_w127_gracefulPowerOff: 62|1@1+ (1,0) [0|0] "" X
 SG_ DIS_w128_fpgaVersionMismatch: 63|1@1+ (1,0) [0|0] "" X

BO_ 998 DIS_alertMatrix5: 8 ETH
 SG_ DIS_u001_brakeShiftReq: 0|1@1+ (1,0) [0|0] "" X
 SG_ DIS_u002_shiftDenied: 1|1@1+ (1,0) [0|0] "" X
 SG_ DIS_u003_unparkReq: 2|1@1+ (1,0) [0|0] "" X
 SG_ DIS_u004_brakeOverride: 3|1@1+ (1,0) [0|0] "" X
 SG_ DIS_u005_cruiseCancelled: 4|1@1+ (1,0) [0|0] "" X
 SG_ DIS_u006_driverLeft: 5|1@1+ (1,0) [0|0] "" X
 SG_ DIS_u007_keyNotAuthenticated: 6|1@1+ (1,0) [0|0] "" X
 SG_ DIS_u008_proximityDriveDenial: 7|1@1+ (1,0) [0|0] "" X
 SG_ DIS_u009_regenOffOverride: 8|1@1+ (1,0) [0|0] "" X
 SG_ DIS_u010_pedalFoul: 9|1@1+ (1,0) [0|0] "" X
 SG_ DIS_u011_driveRailNotRequested: 10|1@1+ (1,0) [0|0] "" X
 SG_ DIS_u012_accelPressedInNP: 11|1@1+ (1,0) [0|0] "" X
 SG_ DIS_u013_bothPedalsPressed: 12|1@1+ (1,0) [0|0] "" X
 SG_ DIS_u014_notOkToStartDrive: 13|1@1+ (1,0) [0|0] "" X
 SG_ DIS_u015_crsNotAvailable: 14|1@1+ (1,0) [0|0] "" X
 SG_ DIS_u016_EBRreleased: 15|1@1+ (1,0) [0|0] "" X
 SG_ DIS_u017_tireFitmentChanged: 16|1@1+ (1,0) [0|0] "" X
 SG_ DIS_u018_crsFrontCameraBlind: 17|1@1+ (1,0) [0|0] "" X
 SG_ DIS_u019_crsFrontRadarBlind: 18|1@1+ (1,0) [0|0] "" X
 SG_ DIS_u020_crsSeatbeltUnbuckled: 19|1@1+ (1,0) [0|0] "" X
 SG_ DIS_u021_rearMotorMode: 20|1@1+ (1,0) [0|0] "" X
 SG_ DIS_u022_frontMotorMode: 21|1@1+ (1,0) [0|0] "" X
 SG_ DIS_u023_holdReleaseRqrd: 22|1@1+ (1,0) [0|0] "" X
 SG_ DIS_u026_brakeStand: 23|1@1+ (1,0) [0|0] "" X
 SG_ DIS_u027_pedalMisapplication: 24|1@1+ (1,0) [0|0] "" X

BO_ 74 DIS_alertMatrix6: 8 ETH
 SG_ DIS_f129_epbNotApplied: 0|1@1+ (1,0) [0|0] "" X
 SG_ DIS_f130_aebFault: 1|1@1+ (1,0) [0|0] "" X
 SG_ DIS_f131_highSpeedWearLimit: 2|1@1+ (1,0) [0|0] "" X
 SG_ DIS_f132_floodSensor: 3|1@1+ (1,0) [0|0] "" X
 SG_ DIS_f133_capacitorOT: 4|1@1+ (1,0) [0|0] "" X
 SG_ DIS_f134_wheelSpeedIrrational: 5|1@1+ (1,0) [0|0] "" X
 SG_ DIS_f135_vehicleHoldFault: 6|1@1+ (1,0) [0|0] "" X
 SG_ DIS_f136_spiError: 7|1@1+ (1,0) [0|0] "" X
 SG_ DIS_f137_unused137: 8|1@1+ (1,0) [0|0] "" X
 SG_ DIS_f138_unused138: 9|1@1+ (1,0) [0|0] "" X
 SG_ DIS_f139_unused139: 10|1@1+ (1,0) [0|0] "" X
 SG_ DIS_f140_unused140: 11|1@1+ (1,0) [0|0] "" X
 SG_ DIS_f141_dasMIA: 12|1@1+ (1,0) [0|0] "" X
 SG_ DIS_f142_highLashAngle: 13|1@1+ (1,0) [0|0] "" X
 SG_ DIS_f143_mcuLimitActive: 14|1@1+ (1,0) [0|0] "" X
 SG_ DIS_f144_configMismatch: 15|1@1+ (1,0) [0|0] "" X
 SG_ DIS_f145_unused145: 16|1@1+ (1,0) [0|0] "" X
 SG_ DIS_f146_unused146: 17|1@1+ (1,0) [0|0] "" X
 SG_ DIS_f147_highTorqueWearLimit: 18|1@1+ (1,0) [0|0] "" X
 SG_ DIS_f148_overtorqueUsed: 19|1@1+ (1,0) [0|0] "" X
 SG_ DIS_f149_oilPumpFailure: 20|1@1+ (1,0) [0|0] "" X
 SG_ DIS_f150_busVD: 21|1@1+ (1,0) [0|0] "" X
 SG_ DIS_f151_shockTorqueLimiter: 22|1@1+ (1,0) [0|0] "" X
 SG_ DIS_f152_linError: 23|1@1+ (1,0) [0|0] "" X
 SG_ DIS_f153_oilPump: 24|1@1+ (1,0) [0|0] "" X
 SG_ DIS_f154_resolver: 25|1@1+ (1,0) [0|0] "" X
 SG_ DIS_f155_vcfrontMIA: 26|1@1+ (1,0) [0|0] "" X
 SG_ DIS_f156_currentObserver: 27|1@1+ (1,0) [0|0] "" X
 SG_ DIS_f157_unused157: 28|1@1+ (1,0) [0|0] "" X
 SG_ DIS_f158_unused158: 29|1@1+ (1,0) [0|0] "" X
 SG_ DIS_f159_unused159: 30|1@1+ (1,0) [0|0] "" X
 SG_ DIS_f160_busVoltageAnomaly: 31|1@1+ (1,0) [0|0] "" X
 SG_ DIS_f161_unused161: 32|1@1+ (1,0) [0|0] "" X
 SG_ DIS_f162_tasMIA: 33|1@1+ (1,0) [0|0] "" X
 SG_ DIS_f163_unused163: 34|1@1+ (1,0) [0|0] "" X
 SG_ DIS_f164_unused164: 35|1@1+ (1,0) [0|0] "" X
 SG_ DIS_f165_unused165: 36|1@1+ (1,0) [0|0] "" X
 SG_ DIS_f166_unused166: 37|1@1+ (1,0) [0|0] "" X
 SG_ DIS_f167_unused167: 38|1@1+ (1,0) [0|0] "" X
 SG_ DIS_f168_unused168: 39|1@1+ (1,0) [0|0] "" X
 SG_ DIS_f169_unused169: 40|1@1+ (1,0) [0|0] "" X
 SG_ DIS_f170_unused170: 41|1@1+ (1,0) [0|0] "" X
 SG_ DIS_f171_unused171: 42|1@1+ (1,0) [0|0] "" X
 SG_ DIS_f172_unused172: 43|1@1+ (1,0) [0|0] "" X
 SG_ DIS_f173_unused173: 44|1@1+ (1,0) [0|0] "" X
 SG_ DIS_f174_unused174: 45|1@1+ (1,0) [0|0] "" X
 SG_ DIS_f175_unused175: 46|1@1+ (1,0) [0|0] "" X
 SG_ DIS_f176_unused176: 47|1@1+ (1,0) [0|0] "" X
 SG_ DIS_f177_unused177: 48|1@1+ (1,0) [0|0] "" X
 SG_ DIS_f178_unused178: 49|1@1+ (1,0) [0|0] "" X
 SG_ DIS_f179_unused179: 50|1@1+ (1,0) [0|0] "" X
 SG_ DIS_f180_unused180: 51|1@1+ (1,0) [0|0] "" X
 SG_ DIS_f181_unused181: 52|1@1+ (1,0) [0|0] "" X
 SG_ DIS_f182_unused182: 53|1@1+ (1,0) [0|0] "" X
 SG_ DIS_f183_unused183: 54|1@1+ (1,0) [0|0] "" X
 SG_ DIS_f184_unused184: 55|1@1+ (1,0) [0|0] "" X
 SG_ DIS_f185_unused185: 56|1@1+ (1,0) [0|0] "" X
 SG_ DIS_f186_unused186: 57|1@1+ (1,0) [0|0] "" X
 SG_ DIS_f187_unused187: 58|1@1+ (1,0) [0|0] "" X
 SG_ DIS_f188_unused188: 59|1@1+ (1,0) [0|0] "" X
 SG_ DIS_f189_unused189: 60|1@1+ (1,0) [0|0] "" X
 SG_ DIS_f190_unused190: 61|1@1+ (1,0) [0|0] "" X
 SG_ DIS_f191_unused191: 62|1@1+ (1,0) [0|0] "" X
 SG_ DIS_f192_mechanical3PS: 63|1@1+ (1,0) [0|0] "" X

BO_ 75 DIS_alertMatrix7: 8 ETH
 SG_ DIS_w129_epbNotApplied: 0|1@1+ (1,0) [0|0] "" X
 SG_ DIS_w130_aebFault: 1|1@1+ (1,0) [0|0] "" X
 SG_ DIS_w131_highSpeedWearLimit: 2|1@1+ (1,0) [0|0] "" X
 SG_ DIS_w132_floodSensor: 3|1@1+ (1,0) [0|0] "" X
 SG_ DIS_w133_capacitorOT: 4|1@1+ (1,0) [0|0] "" X
 SG_ DIS_w134_wheelSpeedIrrational: 5|1@1+ (1,0) [0|0] "" X
 SG_ DIS_w135_vehicleHoldFault: 6|1@1+ (1,0) [0|0] "" X
 SG_ DIS_w136_spiError: 7|1@1+ (1,0) [0|0] "" X
 SG_ DIS_w137_unused137: 8|1@1+ (1,0) [0|0] "" X
 SG_ DIS_w138_unused138: 9|1@1+ (1,0) [0|0] "" X
 SG_ DIS_w139_unused139: 10|1@1+ (1,0) [0|0] "" X
 SG_ DIS_w140_unused140: 11|1@1+ (1,0) [0|0] "" X
 SG_ DIS_w141_dasMIA: 12|1@1+ (1,0) [0|0] "" X
 SG_ DIS_w142_highLashAngle: 13|1@1+ (1,0) [0|0] "" X
 SG_ DIS_w143_mcuLimitActive: 14|1@1+ (1,0) [0|0] "" X
 SG_ DIS_w144_configMismatch: 15|1@1+ (1,0) [0|0] "" X
 SG_ DIS_w145_unused145: 16|1@1+ (1,0) [0|0] "" X
 SG_ DIS_w146_unused146: 17|1@1+ (1,0) [0|0] "" X
 SG_ DIS_w147_highTorqueWearLimit: 18|1@1+ (1,0) [0|0] "" X
 SG_ DIS_w148_overtorqueUsed: 19|1@1+ (1,0) [0|0] "" X
 SG_ DIS_w149_oilPumpFailure: 20|1@1+ (1,0) [0|0] "" X
 SG_ DIS_w150_busVD: 21|1@1+ (1,0) [0|0] "" X
 SG_ DIS_w151_shockTorqueLimiter: 22|1@1+ (1,0) [0|0] "" X
 SG_ DIS_w152_linError: 23|1@1+ (1,0) [0|0] "" X
 SG_ DIS_w153_oilPump: 24|1@1+ (1,0) [0|0] "" X
 SG_ DIS_w154_resolver: 25|1@1+ (1,0) [0|0] "" X
 SG_ DIS_w155_vcfrontMIA: 26|1@1+ (1,0) [0|0] "" X
 SG_ DIS_w156_currentObserver: 27|1@1+ (1,0) [0|0] "" X
 SG_ DIS_w157_unused157: 28|1@1+ (1,0) [0|0] "" X
 SG_ DIS_w158_unused158: 29|1@1+ (1,0) [0|0] "" X
 SG_ DIS_w159_unused159: 30|1@1+ (1,0) [0|0] "" X
 SG_ DIS_w160_busVoltageAnomaly: 31|1@1+ (1,0) [0|0] "" X
 SG_ DIS_w161_unused161: 32|1@1+ (1,0) [0|0] "" X
 SG_ DIS_w162_tasMIA: 33|1@1+ (1,0) [0|0] "" X
 SG_ DIS_w163_unused163: 34|1@1+ (1,0) [0|0] "" X
 SG_ DIS_w164_unused164: 35|1@1+ (1,0) [0|0] "" X
 SG_ DIS_w165_unused165: 36|1@1+ (1,0) [0|0] "" X
 SG_ DIS_w166_unused166: 37|1@1+ (1,0) [0|0] "" X
 SG_ DIS_w167_unused167: 38|1@1+ (1,0) [0|0] "" X
 SG_ DIS_w168_unused168: 39|1@1+ (1,0) [0|0] "" X
 SG_ DIS_w169_unused169: 40|1@1+ (1,0) [0|0] "" X
 SG_ DIS_w170_unused170: 41|1@1+ (1,0) [0|0] "" X
 SG_ DIS_w171_unused171: 42|1@1+ (1,0) [0|0] "" X
 SG_ DIS_w172_unused172: 43|1@1+ (1,0) [0|0] "" X
 SG_ DIS_w173_unused173: 44|1@1+ (1,0) [0|0] "" X
 SG_ DIS_w174_unused174: 45|1@1+ (1,0) [0|0] "" X
 SG_ DIS_w175_unused175: 46|1@1+ (1,0) [0|0] "" X
 SG_ DIS_w176_unused176: 47|1@1+ (1,0) [0|0] "" X
 SG_ DIS_w177_unused177: 48|1@1+ (1,0) [0|0] "" X
 SG_ DIS_w178_unused178: 49|1@1+ (1,0) [0|0] "" X
 SG_ DIS_w179_unused179: 50|1@1+ (1,0) [0|0] "" X
 SG_ DIS_w180_unused180: 51|1@1+ (1,0) [0|0] "" X
 SG_ DIS_w181_unused181: 52|1@1+ (1,0) [0|0] "" X
 SG_ DIS_w182_unused182: 53|1@1+ (1,0) [0|0] "" X
 SG_ DIS_w183_unused183: 54|1@1+ (1,0) [0|0] "" X
 SG_ DIS_w184_unused184: 55|1@1+ (1,0) [0|0] "" X
 SG_ DIS_w185_unused185: 56|1@1+ (1,0) [0|0] "" X
 SG_ DIS_w186_unused186: 57|1@1+ (1,0) [0|0] "" X
 SG_ DIS_w187_unused187: 58|1@1+ (1,0) [0|0] "" X
 SG_ DIS_w188_unused188: 59|1@1+ (1,0) [0|0] "" X
 SG_ DIS_w189_unused189: 60|1@1+ (1,0) [0|0] "" X
 SG_ DIS_w190_unused190: 61|1@1+ (1,0) [0|0] "" X
 SG_ DIS_w191_unused191: 62|1@1+ (1,0) [0|0] "" X
 SG_ DIS_w192_mechanical3PS: 63|1@1+ (1,0) [0|0] "" X

BO_ 1654 DIS_info: 8 ETH
 SG_ DIS_infoIndex M: 0|8@1+ (1,0) [0|0] "" X
 SG_ DIS_buildType m10: 8|8@1+ (1,0) [0|0] "" X
 SG_ DIS_buildConfigurationId m10: 16|16@1+ (1,0) [0|0] "" X
 SG_ DIS_hardwareId m10: 32|16@1+ (1,0) [0|0] "" X
 SG_ DIS_componentId m10: 48|16@1+ (1,0) [0|0] "" X
 SG_ DIS_pcbaId m11: 16|8@1+ (1,0) [0|0] "" X
 SG_ DIS_assemblyId m11: 24|8@1+ (1,0) [0|0] "" X
 SG_ DIS_usageId m11: 32|16@1+ (1,0) [0|0] "" X
 SG_ DIS_subUsageId m11: 48|16@1+ (1,0) [0|0] "" X
 SG_ DIS_applicationSvnRevision m12: 8|24@1+ (1,0) [0|0] "" X
 SG_ DIS_applicationSvnUrlHash m12: 32|32@1+ (1,0) [0|0] "" X
 SG_ DIS_applicationCrc m13: 32|32@1+ (1,0) [0|0] "" X
 SG_ DIS_bootloaderSvnRevision m14: 8|24@1+ (1,0) [0|0] "" X
 SG_ DIS_bootloaderSvnUrlHash m14: 32|32@1+ (1,0) [0|0] "" X
 SG_ DIS_FPGA_version m16: 16|8@1+ (1,0) [0|0] "" X
 SG_ DIS_appGitHash m17: 10|54@1+ (4,0) [0|0] "" X
 SG_ DIS_bootGitHash m18: 10|54@1+ (4,0) [0|0] "" X
 SG_ DIS_platformTyp m19: 8|8@1+ (1,0) [0|0] "" X
 SG_ DIS_infoBootLdUdsProtocolVersion m20: 8|8@1+ (1,0) [0|0] "" X
 SG_ DIS_bootloaderCrc m20: 32|32@1+ (1,0) [0|0] "" X

BO_ 741 DIS_power: 8 ETH
 SG_ DIS_aps12V: 0|8@1+ (0.1,0) [0|0] "V" X
 SG_ DIS_dissipation: 8|8@1+ (125,0) [0|0] "W" X
 SG_ DIS_drivePowerMax: 43|10@1+ (1,0) [0|0] "kW" X
 SG_ DIS_mechPower: 16|11@1- (0.5,0) [0|0] "kW" X
 SG_ DIS_statorCurrent: 32|11@1+ (1,0) [0|0] "A" X

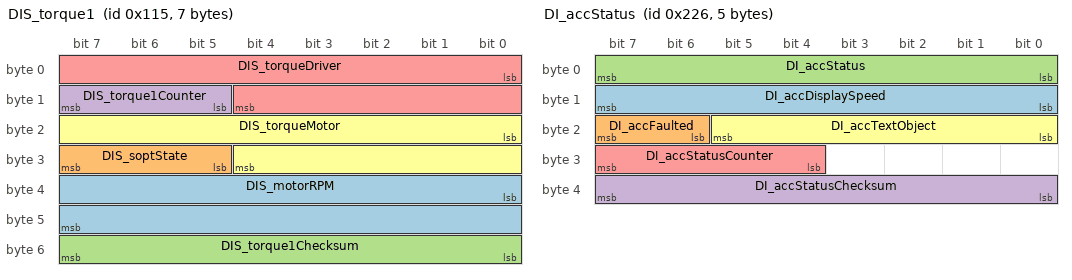
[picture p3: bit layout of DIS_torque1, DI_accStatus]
BO_ 277 DIS_torque1: 7 ETH
 SG_ DIS_motorRPM: 32|16@1- (1,0) [0|0] "RPM" X
 SG_ DIS_soptState: 29|3@1+ (1,0) [0|0] "" X
 SG_ DIS_torque1Checksum: 48|8@1+ (1,0) [0|0] "" X
 SG_ DIS_torque1Counter: 13|3@1+ (1,0) [0|0] "" X
 SG_ DIS_torqueDriver: 0|13@1- (0.25,0) [0|0] "Nm" X
 SG_ DIS_torqueMotor: 16|13@1- (0.25,0) [0|0] "Nm" X

BO_ 1686 DIS_udsResponse: 8 ETH
 SG_ DIS_udsResponseData: 0|54@0+ (1024,0) [0|0] "" X

BO_ 550 DI_accStatus: 5 ETH
 SG_ DI_accDisplaySpeed: 8|8@1+ (1,0) [0|0] "" X
 SG_ DI_accFaulted: 22|2@1+ (1,0) [0|0] "" X
 SG_ DI_accStatus: 0|8@1+ (2,0) [0|0] "" X
 SG_ DI_accStatusChecksum: 32|8@1+ (1,0) [0|0] "" X
 SG_ DI_accStatusCounter: 28|4@1+ (1,0) [0|0] "" X
 SG_ DI_accTextObject: 16|6@1+ (1,0) [0|0] "" X

BO_ 41 DI_alertMatrix1: 8 ETH
 SG_ DI_f001_hwPhaseAgateDrive: 0|1@1+ (1,0) [0|0] "" X
 SG_ DI_f002_hwPhaseBgateDrive: 1|1@1+ (1,0) [0|0] "" X
 SG_ DI_f003_hwPhaseCgateDrive: 2|1@1+ (1,0) [0|0] "" X
 SG_ DI_f004_hwPhaseApeak: 3|1@1+ (1,0) [0|0] "" X
 SG_ DI_f005_hwPhaseBpeak: 4|1@1+ (1,0) [0|0] "" X
 SG_ DI_f006_hwPhaseCpeak: 5|1@1+ (1,0) [0|0] "" X
 SG_ DI_f007_hwHvilNotPresent: 6|1@1+ (1,0) [0|0] "" X
 SG_ DI_f008_hwEncoderA: 7|1@1+ (1,0) [0|0] "" X
 SG_ DI_f009_hwEncoderB: 8|1@1+ (1,0) [0|0] "" X
 SG_ DI_f010_hwPedalMonitorReset: 9|1@1+ (1,0) [0|0] "" X
 SG_ DI_f011_swPowerStageNotReady: 10|1@1+ (1,0) [0|0] "" X
 SG_ DI_f012_accel5VSupply: 11|1@1+ (1,0) [0|0] "" X
 SG_ DI_f013_powerPcbSensor: 12|1@1+ (1,0) [0|0] "" X
 SG_ DI_f014_activeDamping: 13|1@1+ (1,0) [0|0] "" X
 SG_ DI_f015_immobilizer: 14|1@1+ (1,0) [0|0] "" X
 SG_ DI_f016_safeStateApplied: 15|1@1+ (1,0) [0|0] "" X
 SG_ DI_f017_hwPedalMonitor: 16|1@1+ (1,0) [0|0] "" X
 SG_ DI_f018_hw12vSupplyUV: 17|1@1+ (1,0) [0|0] "" X
 SG_ DI_f019_hwAccelPedalPower: 18|1@1+ (1,0) [0|0] "" X
 SG_ DI_f020_hwMotorEncoder: 19|1@1+ (1,0) [0|0] "" X
 SG_ DI_f021_hwBusOV: 20|1@1+ (1,0) [0|0] "" X
 SG_ DI_f022_hw5vSupplyUV: 21|1@1+ (1,0) [0|0] "" X
 SG_ DI_f023_carNotParked: 22|1@1+ (1,0) [0|0] "" X
 SG_ DI_f024_selfTest: 23|1@1+ (1,0) [0|0] "" X
 SG_ DI_f025_phaseApeak: 24|1@1+ (1,0) [0|0] "" X
 SG_ DI_f026_phaseBpeak: 25|1@1+ (1,0) [0|0] "" X
 SG_ DI_f027_phaseCpeak: 26|1@1+ (1,0) [0|0] "" X
 SG_ DI_f028_phaseArms: 27|1@1+ (1,0) [0|0] "" X
 SG_ DI_f029_phaseBrms: 28|1@1+ (1,0) [0|0] "" X
 SG_ DI_f030_phaseCrms: 29|1@1+ (1,0) [0|0] "" X
 SG_ DI_f031_phaseAcurrentOffset: 30|1@1+ (1,0) [0|0] "" X
 SG_ DI_f032_phaseBcurrentOffset: 31|1@1+ (1,0) [0|0] "" X
 SG_ DI_f033_phaseAcurrentSensor: 32|1@1+ (1,0) [0|0] "" X
 SG_ DI_f034_phaseBcurrentSensor: 33|1@1+ (1,0) [0|0] "" X
 SG_ DI_f035_phaseCurrentBalance: 34|1@1+ (1,0) [0|0] "" X
 SG_ DI_f036_busOV: 35|1@1+ (1,0) [0|0] "" X
 SG_ DI_f037_busUV: 36|1@1+ (1,0) [0|0] "" X
 SG_ DI_f038_busVsensor: 37|1@1+ (1,0) [0|0] "" X
 SG_ DI_f039_regenLimited: 38|1@1+ (1,0) [0|0] "" X
 SG_ DI_f040_disMIA: 39|1@1+ (1,0) [0|0] "" X
 SG_ DI_f041_hwFloodDetection: 40|1@1+ (1,0) [0|0] "" X
 SG_ DI_f042_inletSensor: 41|1@1+ (1,0) [0|0] "" X
 SG_ DI_f043_outletOT: 42|1@1+ (1,0) [0|0] "" X
 SG_ DI_f044_outletUT: 43|1@1+ (1,0) [0|0] "" X
 SG_ DI_f045_outletSensor: 44|1@1+ (1,0) [0|0] "" X
 SG_ DI_f046_statorOT: 45|1@1+ (1,0) [0|0] "" X
 SG_ DI_f047_statorSensor1: 46|1@1+ (1,0) [0|0] "" X
 SG_ DI_f048_statorSensor2: 47|1@1+ (1,0) [0|0] "" X
 SG_ DI_f049_statorSensorDiff: 48|1@1+ (1,0) [0|0] "" X
 SG_ DI_f050_noStatorSensor: 49|1@1+ (1,0) [0|0] "" X
 SG_ DI_f051_batteryOvercurrent: 50|1@1+ (1,0) [0|0] "" X
 SG_ DI_f052_rotorBrazeFail: 51|1@1+ (1,0) [0|0] "" X
 SG_ DI_f053_externalAlert: 52|1@1+ (1,0) [0|0] "" X
 SG_ DI_f054_driveInverterOT: 53|1@1+ (1,0) [0|0] "" X
 SG_ DI_f055_trqCrossCheck: 54|1@1+ (1,0) [0|0] "" X
 SG_ DI_f056_ambientOT: 55|1@1+ (1,0) [0|0] "" X
 SG_ DI_f057_ambientUT: 56|1@1+ (1,0) [0|0] "" X
 SG_ DI_f058_ambientSensor: 57|1@1+ (1,0) [0|0] "" X
 SG_ DI_f059_heatsinkOT: 58|1@1+ (1,0) [0|0] "" X
 SG_ DI_f060_heatsinkUT: 59|1@1+ (1,0) [0|0] "" X
 SG_ DI_f061_heatsinkSensor: 60|1@1+ (1,0) [0|0] "" X
 SG_ DI_f062_systemLimpMode: 61|1@1+ (1,0) [0|0] "" X
 SG_ DI_f063_systemGracefulPowerOff: 62|1@1+ (1,0) [0|0] "" X
 SG_ DI_f064_torqueIntervention: 63|1@1+ (1,0) [0|0] "" X

BO_ 42 DI_alertMatrix2: 8 ETH
 SG_ DI_f065_brkMIA: 0|1@1+ (1,0) [0|0] "" X
 SG_ DI_f066_cpcMIA: 1|1@1+ (1,0) [0|0] "" X
 SG_ DI_f067_engMIA: 2|1@1+ (1,0) [0|0] "" X
 SG_ DI_f068_stwAngleMIA: 3|1@1+ (1,0) [0|0] "" X
 SG_ DI_f069_securityControlMIA: 4|1@1+ (1,0) [0|0] "" X
 SG_ DI_f070_12vSupplySensor: 5|1@1+ (1,0) [0|0] "" X
 SG_ DI_f071_busDisconnected: 6|1@1+ (1,0) [0|0] "" X
 SG_ DI_f072_gateDriveFaultCounter: 7|1@1+ (1,0) [0|0] "" X
 SG_ DI_f073_motorSpeed: 8|1@1+ (1,0) [0|0] "" X
 SG_ DI_f074_motorEncoder: 9|1@1+ (1,0) [0|0] "" X
 SG_ DI_f075_motorSpeedMismatch: 10|1@1+ (1,0) [0|0] "" X
 SG_ DI_f076_12vSupplyOV: 11|1@1+ (1,0) [0|0] "" X
 SG_ DI_f077_12vSupplyUV: 12|1@1+ (1,0) [0|0] "" X
 SG_ DI_f078_adcRefLow: 13|1@1+ (1,0) [0|0] "" X
 SG_ DI_f079_adcRefHigh: 14|1@1+ (1,0) [0|0] "" X
 SG_ DI_f080_accelSynch: 15|1@1+ (1,0) [0|0] "" X
 SG_ DI_f081_accelTrack1: 16|1@1+ (1,0) [0|0] "" X
 SG_ DI_f082_accelTrack2: 17|1@1+ (1,0) [0|0] "" X
 SG_ DI_f083_brakePedalSensor: 18|1@1+ (1,0) [0|0] "" X
 SG_ DI_f084_batteryCurrentEstimate: 19|1@1+ (1,0) [0|0] "" X
 SG_ DI_f085_proximityInEnable: 20|1@1+ (1,0) [0|0] "" X
 SG_ DI_f086_hvilNotPresent: 21|1@1+ (1,0) [0|0] "" X
 SG_ DI_f087_gtwMIA: 22|1@1+ (1,0) [0|0] "" X
 SG_ DI_f088_mcuMIA: 23|1@1+ (1,0) [0|0] "" X
 SG_ DI_f089_shifterMIA: 24|1@1+ (1,0) [0|0] "" X
 SG_ DI_f090_pmMIA: 25|1@1+ (1,0) [0|0] "" X
 SG_ DI_f091_espMIA: 26|1@1+ (1,0) [0|0] "" X
 SG_ DI_f092_bmsMIA: 27|1@1+ (1,0) [0|0] "" X
 SG_ DI_f093_canHardware: 28|1@1+ (1,0) [0|0] "" X
 SG_ DI_f094_canData: 29|1@1+ (1,0) [0|0] "" X
 SG_ DI_f095_canOverrun: 30|1@1+ (1,0) [0|0] "" X
 SG_ DI_f096_memoryError: 31|1@1+ (1,0) [0|0] "" X
 SG_ DI_f097_eepromError: 32|1@1+ (1,0) [0|0] "" X
 SG_ DI_f098_intTimeTooLong: 33|1@1+ (1,0) [0|0] "" X
 SG_ DI_f099_threadOverrun: 34|1@1+ (1,0) [0|0] "" X
 SG_ DI_f100_assertion: 35|1@1+ (1,0) [0|0] "" X
 SG_ DI_f101_cruiseInputInvalid: 36|1@1+ (1,0) [0|0] "" X
 SG_ DI_f102_shiftInputInvalid: 37|1@1+ (1,0) [0|0] "" X
 SG_ DI_f103_lowFlow: 38|1@1+ (1,0) [0|0] "" X
 SG_ DI_f104_proximityIrrational: 39|1@1+ (1,0) [0|0] "" X
 SG_ DI_f105_chgMIA: 40|1@1+ (1,0) [0|0] "" X
 SG_ DI_f106_absMIA: 41|1@1+ (1,0) [0|0] "" X
 SG_ DI_f107_fpgaError: 42|1@1+ (1,0) [0|0] "" X
 SG_ DI_f108_stateTrans: 43|1@1+ (1,0) [0|0] "" X
 SG_ DI_f109_cruiseMIA: 44|1@1+ (1,0) [0|0] "" X
 SG_ DI_f110_brakeMIA: 45|1@1+ (1,0) [0|0] "" X
 SG_ DI_f111_badPhaseSensorCalib: 46|1@1+ (1,0) [0|0] "" X
 SG_ DI_f112_noPhaseCurrent: 47|1@1+ (1,0) [0|0] "" X
 SG_ DI_f113_noFuncHeatsinkSensor: 48|1@1+ (1,0) [0|0] "" X
 SG_ DI_f114_noMotorSpeed: 49|1@1+ (1,0) [0|0] "" X
 SG_ DI_f115_heatsinkTempImbalance: 50|1@1+ (1,0) [0|0] "" X
 SG_ DI_f116_powerConvIrrational: 51|1@1+ (1,0) [0|0] "" X
 SG_ DI_f117_diMIA: 52|1@1+ (1,0) [0|0] "" X
 SG_ DI_f118_canBusHeavy: 53|1@1+ (1,0) [0|0] "" X
 SG_ DI_f119_canBusLight: 54|1@1+ (1,0) [0|0] "" X
 SG_ DI_f120_canBusOff: 55|1@1+ (1,0) [0|0] "" X
 SG_ DI_f121_motorControlRegulation: 56|1@1+ (1,0) [0|0] "" X
 SG_ DI_f122_highStackUsage: 57|1@1+ (1,0) [0|0] "" X
 SG_ DI_f123_lossMotorControl: 58|1@1+ (1,0) [0|0] "" X
 SG_ DI_f124_cruiseFault: 59|1@1+ (1,0) [0|0] "" X
 SG_ DI_f125_noBatteryPower: 60|1@1+ (1,0) [0|0] "" X
 SG_ DI_f126_limpMode: 61|1@1+ (1,0) [0|0] "" X
 SG_ DI_f127_gracefulPowerOff: 62|1@1+ (1,0) [0|0] "" X
 SG_ DI_f128_fpgaVersionMismatch: 63|1@1+ (1,0) [0|0] "" X

BO_ 43 DI_alertMatrix3: 8 ETH
 SG_ DI_w001_hwPhaseAgateDrive: 0|1@1+ (1,0) [0|0] "" X
 SG_ DI_w002_hwPhaseBgateDrive: 1|1@1+ (1,0) [0|0] "" X
 SG_ DI_w003_hwPhaseCgateDrive: 2|1@1+ (1,0) [0|0] "" X
 SG_ DI_w004_hwPhaseApeak: 3|1@1+ (1,0) [0|0] "" X
 SG_ DI_w005_hwPhaseBpeak: 4|1@1+ (1,0) [0|0] "" X
 SG_ DI_w006_hwPhaseCpeak: 5|1@1+ (1,0) [0|0] "" X
 SG_ DI_w007_hwHvilNotPresent: 6|1@1+ (1,0) [0|0] "" X
 SG_ DI_w008_hwEncoderA: 7|1@1+ (1,0) [0|0] "" X
 SG_ DI_w009_hwEncoderB: 8|1@1+ (1,0) [0|0] "" X
 SG_ DI_w010_hwPedalMonitorReset: 9|1@1+ (1,0) [0|0] "" X
 SG_ DI_w011_swPowerStageNotReady: 10|1@1+ (1,0) [0|0] "" X
 SG_ DI_w012_accel5VSupply: 11|1@1+ (1,0) [0|0] "" X
 SG_ DI_w013_powerPcbSensor: 12|1@1+ (1,0) [0|0] "" X
 SG_ DI_w014_activeDamping: 13|1@1+ (1,0) [0|0] "" X
 SG_ DI_w015_immobilizer: 14|1@1+ (1,0) [0|0] "" X
 SG_ DI_w016_safeStateApplied: 15|1@1+ (1,0) [0|0] "" X
 SG_ DI_w017_hwPedalMonitor: 16|1@1+ (1,0) [0|0] "" X
 SG_ DI_w018_hw12vSupplyUV: 17|1@1+ (1,0) [0|0] "" X
 SG_ DI_w019_hwAccelPedalPower: 18|1@1+ (1,0) [0|0] "" X
 SG_ DI_w020_hwMotorEncoder: 19|1@1+ (1,0) [0|0] "" X
 SG_ DI_w021_hwBusOV: 20|1@1+ (1,0) [0|0] "" X
 SG_ DI_w022_hw5vSupplyUV: 21|1@1+ (1,0) [0|0] "" X
 SG_ DI_w023_carNotParked: 22|1@1+ (1,0) [0|0] "" X
 SG_ DI_w024_selfTest: 23|1@1+ (1,0) [0|0] "" X
 SG_ DI_w025_phaseApeak: 24|1@1+ (1,0) [0|0] "" X
 SG_ DI_w026_phaseBpeak: 25|1@1+ (1,0) [0|0] "" X
 SG_ DI_w027_phaseCpeak: 26|1@1+ (1,0) [0|0] "" X
 SG_ DI_w028_phaseArms: 27|1@1+ (1,0) [0|0] "" X
 SG_ DI_w029_phaseBrms: 28|1@1+ (1,0) [0|0] "" X
 SG_ DI_w030_phaseCrms: 29|1@1+ (1,0) [0|0] "" X
 SG_ DI_w031_phaseAcurrentOffset: 30|1@1+ (1,0) [0|0] "" X
 SG_ DI_w032_phaseBcurrentOffset: 31|1@1+ (1,0) [0|0] "" X
 SG_ DI_w033_phaseAcurrentSensor: 32|1@1+ (1,0) [0|0] "" X
 SG_ DI_w034_phaseBcurrentSensor: 33|1@1+ (1,0) [0|0] "" X
 SG_ DI_w035_phaseCurrentBalance: 34|1@1+ (1,0) [0|0] "" X
 SG_ DI_w036_busOV: 35|1@1+ (1,0) [0|0] "" X
 SG_ DI_w037_busUV: 36|1@1+ (1,0) [0|0] "" X
 SG_ DI_w038_busVsensor: 37|1@1+ (1,0) [0|0] "" X
 SG_ DI_w039_regenLimited: 38|1@1+ (1,0) [0|0] "" X
 SG_ DI_w040_disMIA: 39|1@1+ (1,0) [0|0] "" X
 SG_ DI_w041_hwFloodDetection: 40|1@1+ (1,0) [0|0] "" X
 SG_ DI_w042_inletSensor: 41|1@1+ (1,0) [0|0] "" X
 SG_ DI_w043_outletOT: 42|1@1+ (1,0) [0|0] "" X
 SG_ DI_w044_outletUT: 43|1@1+ (1,0) [0|0] "" X
 SG_ DI_w045_outletSensor: 44|1@1+ (1,0) [0|0] "" X
 SG_ DI_w046_statorOT: 45|1@1+ (1,0) [0|0] "" X
 SG_ DI_w047_statorSensor1: 46|1@1+ (1,0) [0|0] "" X
 SG_ DI_w048_statorSensor2: 47|1@1+ (1,0) [0|0] "" X
 SG_ DI_w049_statorSensorDiff: 48|1@1+ (1,0) [0|0] "" X
 SG_ DI_w050_noStatorSensor: 49|1@1+ (1,0) [0|0] "" X
 SG_ DI_w051_batteryOvercurrent: 50|1@1+ (1,0) [0|0] "" X
 SG_ DI_w052_rotorBrazeFail: 51|1@1+ (1,0) [0|0] "" X
 SG_ DI_w053_externalAlert: 52|1@1+ (1,0) [0|0] "" X
 SG_ DI_w054_driveInverterOT: 53|1@1+ (1,0) [0|0] "" X
 SG_ DI_w055_trqCrossCheck: 54|1@1+ (1,0) [0|0] "" X
 SG_ DI_w056_ambientOT: 55|1@1+ (1,0) [0|0] "" X
 SG_ DI_w057_ambientUT: 56|1@1+ (1,0) [0|0] "" X
 SG_ DI_w058_ambientSensor: 57|1@1+ (1,0) [0|0] "" X
 SG_ DI_w059_heatsinkOT: 58|1@1+ (1,0) [0|0] "" X
 SG_ DI_w060_heatsinkUT: 59|1@1+ (1,0) [0|0] "" X
 SG_ DI_w061_heatsinkSensor: 60|1@1+ (1,0) [0|0] "" X
 SG_ DI_w062_systemLimpMode: 61|1@1+ (1,0) [0|0] "" X
 SG_ DI_w063_systemGracefulPowerOff: 62|1@1+ (1,0) [0|0] "" X
 SG_ DI_w064_torqueIntervention: 63|1@1+ (1,0) [0|0] "" X

BO_ 44 DI_alertMatrix4: 8 ETH
 SG_ DI_w065_brkMIA: 0|1@1+ (1,0) [0|0] "" X
 SG_ DI_w066_cpcMIA: 1|1@1+ (1,0) [0|0] "" X
 SG_ DI_w067_engMIA: 2|1@1+ (1,0) [0|0] "" X
 SG_ DI_w068_stwAngleMIA: 3|1@1+ (1,0) [0|0] "" X
 SG_ DI_w069_securityControlMIA: 4|1@1+ (1,0) [0|0] "" X
 SG_ DI_w070_12vSupplySensor: 5|1@1+ (1,0) [0|0] "" X
 SG_ DI_w071_busDisconnected: 6|1@1+ (1,0) [0|0] "" X
 SG_ DI_w072_gateDriveFaultCounter: 7|1@1+ (1,0) [0|0] "" X
 SG_ DI_w073_motorSpeed: 8|1@1+ (1,0) [0|0] "" X
 SG_ DI_w074_motorEncoder: 9|1@1+ (1,0) [0|0] "" X
 SG_ DI_w075_motorSpeedMismatch: 10|1@1+ (1,0) [0|0] "" X
 SG_ DI_w076_12vSupplyOV: 11|1@1+ (1,0) [0|0] "" X
 SG_ DI_w077_12vSupplyUV: 12|1@1+ (1,0) [0|0] "" X
 SG_ DI_w078_adcRefLow: 13|1@1+ (1,0) [0|0] "" X
 SG_ DI_w079_adcRefHigh: 14|1@1+ (1,0) [0|0] "" X
 SG_ DI_w080_accelSynch: 15|1@1+ (1,0) [0|0] "" X
 SG_ DI_w081_accelTrack1: 16|1@1+ (1,0) [0|0] "" X
 SG_ DI_w082_accelTrack2: 17|1@1+ (1,0) [0|0] "" X
 SG_ DI_w083_brakePedalSensor: 18|1@1+ (1,0) [0|0] "" X
 SG_ DI_w084_batteryCurrentEstimate: 19|1@1+ (1,0) [0|0] "" X
 SG_ DI_w085_proximityInEnable: 20|1@1+ (1,0) [0|0] "" X
 SG_ DI_w086_hvilNotPresent: 21|1@1+ (1,0) [0|0] "" X
 SG_ DI_w087_gtwMIA: 22|1@1+ (1,0) [0|0] "" X
 SG_ DI_w088_mcuMIA: 23|1@1+ (1,0) [0|0] "" X
 SG_ DI_w089_shifterMIA: 24|1@1+ (1,0) [0|0] "" X
 SG_ DI_w090_pmMIA: 25|1@1+ (1,0) [0|0] "" X
 SG_ DI_w091_espMIA: 26|1@1+ (1,0) [0|0] "" X
 SG_ DI_w092_bmsMIA: 27|1@1+ (1,0) [0|0] "" X
 SG_ DI_w093_canHardware: 28|1@1+ (1,0) [0|0] "" X
 SG_ DI_w094_canData: 29|1@1+ (1,0) [0|0] "" X
 SG_ DI_w095_canOverrun: 30|1@1+ (1,0) [0|0] "" X
 SG_ DI_w096_memoryError: 31|1@1+ (1,0) [0|0] "" X
 SG_ DI_w097_eepromError: 32|1@1+ (1,0) [0|0] "" X
 SG_ DI_w098_intTimeTooLong: 33|1@1+ (1,0) [0|0] "" X
 SG_ DI_w099_threadOverrun: 34|1@1+ (1,0) [0|0] "" X
 SG_ DI_w100_assertion: 35|1@1+ (1,0) [0|0] "" X
 SG_ DI_w101_cruiseInputInvalid: 36|1@1+ (1,0) [0|0] "" X
 SG_ DI_w102_shiftInputInvalid: 37|1@1+ (1,0) [0|0] "" X
 SG_ DI_w103_lowFlow: 38|1@1+ (1,0) [0|0] "" X
 SG_ DI_w104_proximityIrrational: 39|1@1+ (1,0) [0|0] "" X
 SG_ DI_w105_chgMIA: 40|1@1+ (1,0) [0|0] "" X
 SG_ DI_w106_absMIA: 41|1@1+ (1,0) [0|0] "" X
 SG_ DI_w107_fpgaError: 42|1@1+ (1,0) [0|0] "" X
 SG_ DI_w108_stateTrans: 43|1@1+ (1,0) [0|0] "" X
 SG_ DI_w109_cruiseMIA: 44|1@1+ (1,0) [0|0] "" X
 SG_ DI_w110_brakeMIA: 45|1@1+ (1,0) [0|0] "" X
 SG_ DI_w111_badPhaseSensorCalib: 46|1@1+ (1,0) [0|0] "" X
 SG_ DI_w112_noPhaseCurrent: 47|1@1+ (1,0) [0|0] "" X
 SG_ DI_w113_noFuncHeatsinkSensor: 48|1@1+ (1,0) [0|0] "" X
 SG_ DI_w114_noMotorSpeed: 49|1@1+ (1,0) [0|0] "" X
 SG_ DI_w115_heatsinkTempImbalance: 50|1@1+ (1,0) [0|0] "" X
 SG_ DI_w116_powerConvIrrational: 51|1@1+ (1,0) [0|0] "" X
 SG_ DI_w117_diMIA: 52|1@1+ (1,0) [0|0] "" X
 SG_ DI_w118_canBusHeavy: 53|1@1+ (1,0) [0|0] "" X
 SG_ DI_w119_canBusLight: 54|1@1+ (1,0) [0|0] "" X
 SG_ DI_w120_canBusOff: 55|1@1+ (1,0) [0|0] "" X
 SG_ DI_w121_motorControlRegulation: 56|1@1+ (1,0) [0|0] "" X
 SG_ DI_w122_highStackUsage: 57|1@1+ (1,0) [0|0] "" X
 SG_ DI_w123_lossMotorControl: 58|1@1+ (1,0) [0|0] "" X
 SG_ DI_w124_cruiseFault: 59|1@1+ (1,0) [0|0] "" X
 SG_ DI_w125_noBatteryPower: 60|1@1+ (1,0) [0|0] "" X
 SG_ DI_w126_limpMode: 61|1@1+ (1,0) [0|0] "" X
 SG_ DI_w127_gracefulPowerOff: 62|1@1+ (1,0) [0|0] "" X
 SG_ DI_w128_fpgaVersionMismatch: 63|1@1+ (1,0) [0|0] "" X

BO_ 63 DI_alertMatrix5: 8 ETH
 SG_ DI_u001_brakeShiftReq: 0|1@1+ (1,0) [0|0] "" X
 SG_ DI_u002_shiftDenied: 1|1@1+ (1,0) [0|0] "" X
 SG_ DI_u003_unparkReq: 2|1@1+ (1,0) [0|0] "" X
 SG_ DI_u004_brakeOverride: 3|1@1+ (1,0) [0|0] "" X
 SG_ DI_u005_cruiseCancelled: 4|1@1+ (1,0) [0|0] "" X
 SG_ DI_u006_driverLeft: 5|1@1+ (1,0) [0|0] "" X
 SG_ DI_u007_keyNotAuthenticated: 6|1@1+ (1,0) [0|0] "" X
 SG_ DI_u008_proximityDriveDenial: 7|1@1+ (1,0) [0|0] "" X
 SG_ DI_u009_regenOffOverride: 8|1@1+ (1,0) [0|0] "" X
 SG_ DI_u010_pedalFoul: 9|1@1+ (1,0) [0|0] "" X
 SG_ DI_u011_driveRailNotRequested: 10|1@1+ (1,0) [0|0] "" X
 SG_ DI_u012_accelPressedInNP: 11|1@1+ (1,0) [0|0] "" X
 SG_ DI_u013_bothPedalsPressed: 12|1@1+ (1,0) [0|0] "" X
 SG_ DI_u014_notOkToStartDrive: 13|1@1+ (1,0) [0|0] "" X
 SG_ DI_u015_crsNotAvailable: 14|1@1+ (1,0) [0|0] "" X
 SG_ DI_u016_EBRreleased: 15|1@1+ (1,0) [0|0] "" X
 SG_ DI_u017_tireFitmentChanged: 16|1@1+ (1,0) [0|0] "" X
 SG_ DI_u018_crsFrontCameraBlind: 17|1@1+ (1,0) [0|0] "" X
 SG_ DI_u019_crsFrontRadarBlind: 18|1@1+ (1,0) [0|0] "" X
 SG_ DI_u020_crsSeatbeltUnbuckled: 19|1@1+ (1,0) [0|0] "" X
 SG_ DI_u021_rearMotorMode: 20|1@1+ (1,0) [0|0] "" X
 SG_ DI_u022_frontMotorMode: 21|1@1+ (1,0) [0|0] "" X
 SG_ DI_u023_holdReleaseRqrd: 22|1@1+ (1,0) [0|0] "" X
 SG_ DI_u024_autoparkCanceled: 23|1@1+ (1,0) [0|0] "" X
 SG_ DI_u025_autoparkAborted: 24|1@1+ (1,0) [0|0] "" X
 SG_ DI_u026_brakeStand: 25|1@1+ (1,0) [0|0] "" X
 SG_ DI_u027_pedalMisapplication: 26|1@1+ (1,0) [0|0] "" X
 SG_ DI_u028_crsPathNotClear: 27|1@1+ (1,0) [0|0] "" X
 SG_ DI_u029_garageShiftWithPedal: 28|1@1+ (1,0) [0|0] "" X
 SG_ DI_u030_crsCamsNotCalibrated: 29|1@1+ (1,0) [0|0] "" X
 SG_ DI_u031_sysStartConditionNotMet: 30|1@1+ (1,0) [0|0] "" X

BO_ 72 DI_alertMatrix6: 8 ETH
 SG_ DI_f129_epbNotApplied: 0|1@1+ (1,0) [0|0] "" X
 SG_ DI_f130_aebFault: 1|1@1+ (1,0) [0|0] "" X
 SG_ DI_f131_highSpeedWearLimit: 2|1@1+ (1,0) [0|0] "" X
 SG_ DI_f132_floodSensor: 3|1@1+ (1,0) [0|0] "" X
 SG_ DI_f133_capacitorOT: 4|1@1+ (1,0) [0|0] "" X
 SG_ DI_f134_wheelSpeedIrrational: 5|1@1+ (1,0) [0|0] "" X
 SG_ DI_f135_vehicleHoldFault: 6|1@1+ (1,0) [0|0] "" X
 SG_ DI_f136_spiError: 7|1@1+ (1,0) [0|0] "" X
 SG_ DI_f137_noCapableDriveUnits: 8|1@1+ (1,0) [0|0] "" X
 SG_ DI_f138_frontUnitDisabled: 9|1@1+ (1,0) [0|0] "" X
 SG_ DI_f139_rearUnitDisabled: 10|1@1+ (1,0) [0|0] "" X
 SG_ DI_f140_systemStateTrans: 11|1@1+ (1,0) [0|0] "" X
 SG_ DI_f141_dasMIA: 12|1@1+ (1,0) [0|0] "" X
 SG_ DI_f142_highLashAngle: 13|1@1+ (1,0) [0|0] "" X
 SG_ DI_f143_mcuLimitActive: 14|1@1+ (1,0) [0|0] "" X
 SG_ DI_f144_configMismatch: 15|1@1+ (1,0) [0|0] "" X
 SG_ DI_f145_pbrkPanicSkid: 16|1@1+ (1,0) [0|0] "" X
 SG_ DI_f146_pbrkPanicEpbFault: 17|1@1+ (1,0) [0|0] "" X
 SG_ DI_f147_highTorqueWearLimit: 18|1@1+ (1,0) [0|0] "" X
 SG_ DI_f148_overtorqueUsed: 19|1@1+ (1,0) [0|0] "" X
 SG_ DI_f149_oilPumpFailure: 20|1@1+ (1,0) [0|0] "" X
 SG_ DI_f150_busVD: 21|1@1+ (1,0) [0|0] "" X
 SG_ DI_f151_shockTorqueLimiter: 22|1@1+ (1,0) [0|0] "" X
 SG_ DI_f152_linError: 23|1@1+ (1,0) [0|0] "" X
 SG_ DI_f153_oilPump: 24|1@1+ (1,0) [0|0] "" X
 SG_ DI_f154_resolver: 25|1@1+ (1,0) [0|0] "" X
 SG_ DI_f155_vcfrontMIA: 26|1@1+ (1,0) [0|0] "" X
 SG_ DI_f156_currentObserver: 27|1@1+ (1,0) [0|0] "" X
 SG_ DI_f157_unused157: 28|1@1+ (1,0) [0|0] "" X
 SG_ DI_f158_unused158: 29|1@1+ (1,0) [0|0] "" X
 SG_ DI_f159_cruiseSelfCheck: 30|1@1+ (1,0) [0|0] "" X
 SG_ DI_f160_busVoltageAnomaly: 31|1@1+ (1,0) [0|0] "" X
 SG_ DI_f161_frontWheelImpactDetected: 32|1@1+ (1,0) [0|0] "" X
 SG_ DI_f162_tasMIA: 33|1@1+ (1,0) [0|0] "" X
 SG_ DI_f163_driverBrakeApplyCheck: 34|1@1+ (1,0) [0|0] "" X
 SG_ DI_f164_unused164: 35|1@1+ (1,0) [0|0] "" X
 SG_ DI_f165_unused165: 36|1@1+ (1,0) [0|0] "" X
 SG_ DI_f166_unused166: 37|1@1+ (1,0) [0|0] "" X
 SG_ DI_f167_unused167: 38|1@1+ (1,0) [0|0] "" X
 SG_ DI_f168_unused168: 39|1@1+ (1,0) [0|0] "" X
 SG_ DI_f169_unused169: 40|1@1+ (1,0) [0|0] "" X
 SG_ DI_f170_unused170: 41|1@1+ (1,0) [0|0] "" X
 SG_ DI_f171_unused171: 42|1@1+ (1,0) [0|0] "" X
 SG_ DI_f172_unused172: 43|1@1+ (1,0) [0|0] "" X
 SG_ DI_f173_unused173: 44|1@1+ (1,0) [0|0] "" X
 SG_ DI_f174_unused174: 45|1@1+ (1,0) [0|0] "" X
 SG_ DI_f175_unused175: 46|1@1+ (1,0) [0|0] "" X
 SG_ DI_f176_unused176: 47|1@1+ (1,0) [0|0] "" X
 SG_ DI_f177_unused177: 48|1@1+ (1,0) [0|0] "" X
 SG_ DI_f178_unused178: 49|1@1+ (1,0) [0|0] "" X
 SG_ DI_f179_unused179: 50|1@1+ (1,0) [0|0] "" X
 SG_ DI_f180_unused180: 51|1@1+ (1,0) [0|0] "" X
 SG_ DI_f181_unused181: 52|1@1+ (1,0) [0|0] "" X
 SG_ DI_f182_unused182: 53|1@1+ (1,0) [0|0] "" X
 SG_ DI_f183_unused183: 54|1@1+ (1,0) [0|0] "" X
 SG_ DI_f184_unused184: 55|1@1+ (1,0) [0|0] "" X
 SG_ DI_f185_unused185: 56|1@1+ (1,0) [0|0] "" X
 SG_ DI_f186_unused186: 57|1@1+ (1,0) [0|0] "" X
 SG_ DI_f187_unused187: 58|1@1+ (1,0) [0|0] "" X
 SG_ DI_f188_unused188: 59|1@1+ (1,0) [0|0] "" X
 SG_ DI_f189_unused189: 60|1@1+ (1,0) [0|0] "" X
 SG_ DI_f190_unused190: 61|1@1+ (1,0) [0|0] "" X
 SG_ DI_f191_unused191: 62|1@1+ (1,0) [0|0] "" X
 SG_ DI_f192_mechanical3PS: 63|1@1+ (1,0) [0|0] "" X

BO_ 73 DI_alertMatrix7: 8 ETH
 SG_ DI_w129_epbNotApplied: 0|1@1+ (1,0) [0|0] "" X
 SG_ DI_w130_aebFault: 1|1@1+ (1,0) [0|0] "" X
 SG_ DI_w131_highSpeedWearLimit: 2|1@1+ (1,0) [0|0] "" X
 SG_ DI_w132_floodSensor: 3|1@1+ (1,0) [0|0] "" X
 SG_ DI_w133_capacitorOT: 4|1@1+ (1,0) [0|0] "" X
 SG_ DI_w134_wheelSpeedIrrational: 5|1@1+ (1,0) [0|0] "" X
 SG_ DI_w135_vehicleHoldFault: 6|1@1+ (1,0) [0|0] "" X
 SG_ DI_w136_spiError: 7|1@1+ (1,0) [0|0] "" X
 SG_ DI_w137_noCapableDriveUnits: 8|1@1+ (1,0) [0|0] "" X
 SG_ DI_w138_frontUnitDisabled: 9|1@1+ (1,0) [0|0] "" X
 SG_ DI_w139_rearUnitDisabled: 10|1@1+ (1,0) [0|0] "" X
 SG_ DI_w140_systemStateTrans: 11|1@1+ (1,0) [0|0] "" X
 SG_ DI_w141_dasMIA: 12|1@1+ (1,0) [0|0] "" X
 SG_ DI_w142_highLashAngle: 13|1@1+ (1,0) [0|0] "" X
 SG_ DI_w143_mcuLimitActive: 14|1@1+ (1,0) [0|0] "" X
 SG_ DI_w144_configMismatch: 15|1@1+ (1,0) [0|0] "" X
 SG_ DI_w145_pbrkPanicSkid: 16|1@1+ (1,0) [0|0] "" X
 SG_ DI_w146_pbrkPanicEpbFault: 17|1@1+ (1,0) [0|0] "" X
 SG_ DI_w147_highTorqueWearLimit: 18|1@1+ (1,0) [0|0] "" X
 SG_ DI_w148_overtorqueUsed: 19|1@1+ (1,0) [0|0] "" X
 SG_ DI_w149_oilPumpFailure: 20|1@1+ (1,0) [0|0] "" X
 SG_ DI_w150_busVD: 21|1@1+ (1,0) [0|0] "" X
 SG_ DI_w151_shockTorqueLimiter: 22|1@1+ (1,0) [0|0] "" X
 SG_ DI_w152_linError: 23|1@1+ (1,0) [0|0] "" X
 SG_ DI_w153_oilPump: 24|1@1+ (1,0) [0|0] "" X
 SG_ DI_w154_resolver: 25|1@1+ (1,0) [0|0] "" X
 SG_ DI_w155_vcfrontMIA: 26|1@1+ (1,0) [0|0] "" X
 SG_ DI_w156_currentObserver: 27|1@1+ (1,0) [0|0] "" X
 SG_ DI_w157_unused157: 28|1@1+ (1,0) [0|0] "" X
 SG_ DI_w158_unused158: 29|1@1+ (1,0) [0|0] "" X
 SG_ DI_w159_cruiseSelfCheck: 30|1@1+ (1,0) [0|0] "" X
 SG_ DI_w160_busVoltageAnomaly: 31|1@1+ (1,0) [0|0] "" X
 SG_ DI_w161_frontWheelImpactDetected: 32|1@1+ (1,0) [0|0] "" X
 SG_ DI_w162_tasMIA: 33|1@1+ (1,0) [0|0] "" X
 SG_ DI_w163_driverBrakeApplyCheck: 34|1@1+ (1,0) [0|0] "" X
 SG_ DI_w164_unused164: 35|1@1+ (1,0) [0|0] "" X
 SG_ DI_w165_unused165: 36|1@1+ (1,0) [0|0] "" X
 SG_ DI_w166_unused166: 37|1@1+ (1,0) [0|0] "" X
 SG_ DI_w167_unused167: 38|1@1+ (1,0) [0|0] "" X
 SG_ DI_w168_unused168: 39|1@1+ (1,0) [0|0] "" X
 SG_ DI_w169_unused169: 40|1@1+ (1,0) [0|0] "" X
 SG_ DI_w170_unused170: 41|1@1+ (1,0) [0|0] "" X
 SG_ DI_w171_unused171: 42|1@1+ (1,0) [0|0] "" X
 SG_ DI_w172_unused172: 43|1@1+ (1,0) [0|0] "" X
 SG_ DI_w173_unused173: 44|1@1+ (1,0) [0|0] "" X
 SG_ DI_w174_unused174: 45|1@1+ (1,0) [0|0] "" X
 SG_ DI_w175_unused175: 46|1@1+ (1,0) [0|0] "" X
 SG_ DI_w176_unused176: 47|1@1+ (1,0) [0|0] "" X
 SG_ DI_w177_unused177: 48|1@1+ (1,0) [0|0] "" X
 SG_ DI_w178_unused178: 49|1@1+ (1,0) [0|0] "" X
 SG_ DI_w179_unused179: 50|1@1+ (1,0) [0|0] "" X
 SG_ DI_w180_unused180: 51|1@1+ (1,0) [0|0] "" X
 SG_ DI_w181_unused181: 52|1@1+ (1,0) [0|0] "" X
 SG_ DI_w182_unused182: 53|1@1+ (1,0) [0|0] "" X
 SG_ DI_w183_unused183: 54|1@1+ (1,0) [0|0] "" X
 SG_ DI_w184_unused184: 55|1@1+ (1,0) [0|0] "" X
 SG_ DI_w185_unused185: 56|1@1+ (1,0) [0|0] "" X
 SG_ DI_w186_unused186: 57|1@1+ (1,0) [0|0] "" X
 SG_ DI_w187_unused187: 58|1@1+ (1,0) [0|0] "" X
 SG_ DI_w188_unused188: 59|1@1+ (1,0) [0|0] "" X
 SG_ DI_w189_unused189: 60|1@1+ (1,0) [0|0] "" X
 SG_ DI_w190_unused190: 61|1@1+ (1,0) [0|0] "" X
 SG_ DI_w191_unused191: 62|1@1+ (1,0) [0|0] "" X
 SG_ DI_w192_mechanical3PS: 63|1@1+ (1,0) [0|0] "" X

BO_ 82 DI_dtcMatrix: 8 ETH
 SG_ DI_dtcIndex M: 0|8@1+ (1,0) [0|0] "" X
 SG_ DI_d001_replaceDriveUnit m0: 8|2@1+ (1,0) [0|0] "" X
 SG_ DI_d002_12vSupplyOV m0: 10|2@1+ (1,0) [0|0] "" X
 SG_ DI_d003_12vSupplyUV m0: 12|2@1+ (1,0) [0|0] "" X
 SG_ DI_d004_overTemp m0: 14|2@1+ (1,0) [0|0] "" X
 SG_ DI_d005_lowFlow m0: 16|2@1+ (1,0) [0|0] "" X
 SG_ DI_d006_proximityLine m0: 18|2@1+ (1,0) [0|0] "" X
 SG_ DI_d007_busUV m0: 20|2@1+ (1,0) [0|0] "" X
 SG_ DI_d008_motorEncoder m0: 22|2@1+ (1,0) [0|0] "" X
 SG_ DI_d009_brakePedal m0: 24|2@1+ (1,0) [0|0] "" X
 SG_ DI_d010_accelPedal m0: 26|2@1+ (1,0) [0|0] "" X
 SG_ DI_d011_unused11 m0: 28|2@1+ (1,0) [0|0] "" X
 SG_ DI_d012_unused12 m0: 30|2@1+ (1,0) [0|0] "" X
 SG_ DI_d013_unused13 m0: 32|2@1+ (1,0) [0|0] "" X
 SG_ DI_d014_unused14 m0: 34|2@1+ (1,0) [0|0] "" X
 SG_ DI_d015_unused15 m0: 36|2@1+ (1,0) [0|0] "" X
 SG_ DI_d016_unused16 m0: 38|2@1+ (1,0) [0|0] "" X
 SG_ DI_d017_unused17 m0: 40|2@1+ (1,0) [0|0] "" X
 SG_ DI_d018_unused18 m0: 42|2@1+ (1,0) [0|0] "" X
 SG_ DI_d019_unused19 m0: 44|2@1+ (1,0) [0|0] "" X
 SG_ DI_d020_unused20 m0: 46|2@1+ (1,0) [0|0] "" X
 SG_ DI_d021_unused21 m0: 48|2@1+ (1,0) [0|0] "" X
 SG_ DI_d022_unused22 m0: 50|2@1+ (1,0) [0|0] "" X
 SG_ DI_d023_unused23 m0: 52|2@1+ (1,0) [0|0] "" X
 SG_ DI_d024_unused24 m0: 54|2@1+ (1,0) [0|0] "" X
 SG_ DI_d025_unused25 m0: 56|2@1+ (1,0) [0|0] "" X
 SG_ DI_d026_unused26 m0: 58|2@1+ (1,0) [0|0] "" X
 SG_ DI_d027_unused27 m0: 60|2@1+ (1,0) [0|0] "" X
 SG_ DI_d028_unused28 m0: 62|2@1+ (1,0) [0|0] "" X

BO_ 1622 DI_info: 8 ETH
 SG_ DI_infoIndex M: 0|8@1+ (1,0) [0|0] "" X
 SG_ DI_buildType m10: 8|8@1+ (1,0) [0|0] "" X
 SG_ DI_buildConfigurationId m10: 16|16@1+ (1,0) [0|0] "" X
 SG_ DI_hardwareId m10: 32|16@1+ (1,0) [0|0] "" X
 SG_ DI_componentId m10: 48|16@1+ (1,0) [0|0] "" X
 SG_ DI_pcbaId m11: 16|8@1+ (1,0) [0|0] "" X
 SG_ DI_assemblyId m11: 24|8@1+ (1,0) [0|0] "" X
 SG_ DI_usageId m11: 32|16@1+ (1,0) [0|0] "" X
 SG_ DI_subUsageId m11: 48|16@1+ (1,0) [0|0] "" X
 SG_ DI_applicationSvnRevision m12: 8|24@1+ (1,0) [0|0] "" X
 SG_ DI_applicationSvnUrlHash m12: 32|32@1+ (1,0) [0|0] "" X
 SG_ DI_applicationCrc m13: 32|32@1+ (1,0) [0|0] "" X
 SG_ DI_bootloaderSvnRevision m14: 8|24@1+ (1,0) [0|0] "" X
 SG_ DI_bootloaderSvnUrlHash m14: 32|32@1+ (1,0) [0|0] "" X
 SG_ DI_FPGA_version m16: 16|8@1+ (1,0) [0|0] "" X
 SG_ DI_appGitHash m17: 10|54@1+ (4,0) [0|0] "" X
 SG_ DI_bootGitHash m18: 10|54@1+ (4,0) [0|0] "" X
 SG_ DI_platformTyp m19: 8|8@1+ (1,0) [0|0] "" X
 SG_ DI_infoBootLdUdsProtocolVersion m20: 8|8@1+ (1,0) [0|0] "" X
 SG_ DI_bootloaderCrc m20: 32|32@1+ (1,0) [0|0] "" X

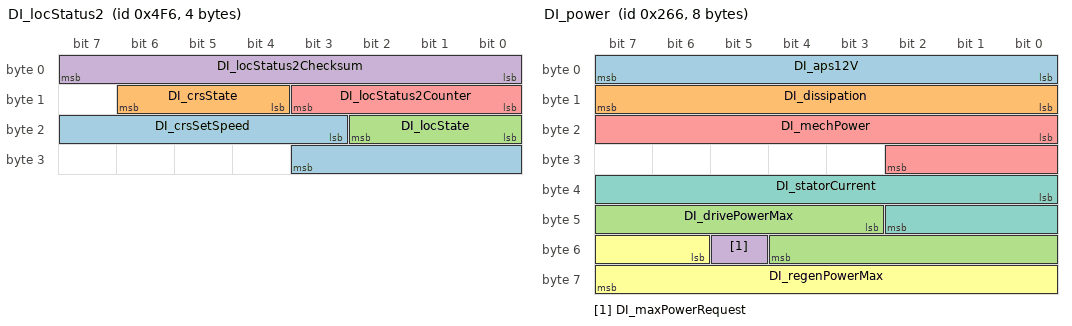
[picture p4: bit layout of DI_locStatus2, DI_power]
BO_ 1270 DI_locStatus2: 4 ETH
 SG_ DI_crsSetSpeed: 19|9@1+ (0.5,0) [0|0] "kph" X
 SG_ DI_crsState: 12|3@1+ (1,0) [0|0] "" X
 SG_ DI_locState: 16|3@1+ (1,0) [0|0] "" X
 SG_ DI_locStatus2Checksum: 0|8@1+ (1,0) [0|0] "" X
 SG_ DI_locStatus2Counter: 8|4@1+ (1,0) [0|0] "" X

BO_ 294 DI_motorControl: 8 ETH
 SG_ DI_limitBaseSpeed: 47|1@1+ (1,0) [0|0] "" X
 SG_ DI_limitDcCableTemp: 58|1@1+ (1,0) [0|0] "" X
 SG_ DI_limitDcCapTemp: 49|1@1+ (1,0) [0|0] "" X
 SG_ DI_limitDeltaFluidTemp: 37|1@1+ (1,0) [0|0] "" X
 SG_ DI_limitDiff: 54|1@1+ (1,0) [0|0] "" X
 SG_ DI_limitDischargePower: 38|1@1+ (1,0) [0|0] "" X
 SG_ DI_limitDriveTorque: 42|1@1+ (1,0) [0|0] "" X
 SG_ DI_limitGracefulPowerOff: 55|1@1+ (1,0) [0|0] "" X
 SG_ DI_limitIBat: 48|1@1+ (1,0) [0|0] "" X
 SG_ DI_limitIGBTJunctTemp: 56|1@1+ (1,0) [0|0] "" X
 SG_ DI_limitInverterTemp: 33|1@1+ (1,0) [0|0] "" X
 SG_ DI_limitLimpMode: 36|1@1+ (1,0) [0|0] "" X
 SG_ DI_limitMotorCurrent: 40|1@1+ (1,0) [0|0] "" X
 SG_ DI_limitMotorSpeed: 52|1@1+ (1,0) [0|0] "" X
 SG_ DI_limitMotorVoltage: 41|1@1+ (1,0) [0|0] "" X
 SG_ DI_limitObstacleDetection: 60|1@1+ (1,0) [0|0] "" X
 SG_ DI_limitOilPumpFluidTemp: 59|1@1+ (1,0) [0|0] "" X
 SG_ DI_limitPCBTemp: 32|1@1+ (1,0) [0|0] "" X
 SG_ DI_limitPoleTemp: 35|1@1+ (1,0) [0|0] "" X
 SG_ DI_limitRegenPower: 39|1@1+ (1,0) [0|0] "" X
 SG_ DI_limitRegenTorque: 43|1@1+ (1,0) [0|0] "" X
 SG_ DI_limitShift: 46|1@1+ (1,0) [0|0] "" X
 SG_ DI_limitShockTorque: 57|1@1+ (1,0) [0|0] "" X
 SG_ DI_limitStatorTemp: 34|1@1+ (1,0) [0|0] "" X
 SG_ DI_limitTCDrive: 44|1@1+ (1,0) [0|0] "" X
 SG_ DI_limitTCRegen: 45|1@1+ (1,0) [0|0] "" X
 SG_ DI_limitVBatHigh: 51|1@1+ (1,0) [0|0] "" X
 SG_ DI_limitVBatLow: 50|1@1+ (1,0) [0|0] "" X
 SG_ DI_limitVehicleSpeed: 53|1@1+ (1,0) [0|0] "" X
 SG_ DI_motorCurrent: 16|11@1+ (1,0) [0|0] "A" X
 SG_ DI_vBat: 0|10@1+ (0.5,0) [0|0] "V" X

BO_ 614 DI_power: 8 ETH
 SG_ DI_aps12V: 0|8@1+ (0.1,0) [0|0] "V" X
 SG_ DI_dissipation: 8|8@1+ (125,0) [0|0] "W" X
 SG_ DI_drivePowerMax: 43|10@1+ (1,0) [0|0] "kW" X
 SG_ DI_maxPowerRequest: 53|1@1+ (1,0) [0|0] "" X
 SG_ DI_mechPower: 16|11@1- (0.5,0) [0|0] "kW" X
 SG_ DI_regenPowerMax: 54|10@1+ (1,-200) [0|0] "kW" X
 SG_ DI_statorCurrent: 32|11@1+ (1,0) [0|0] "A" X

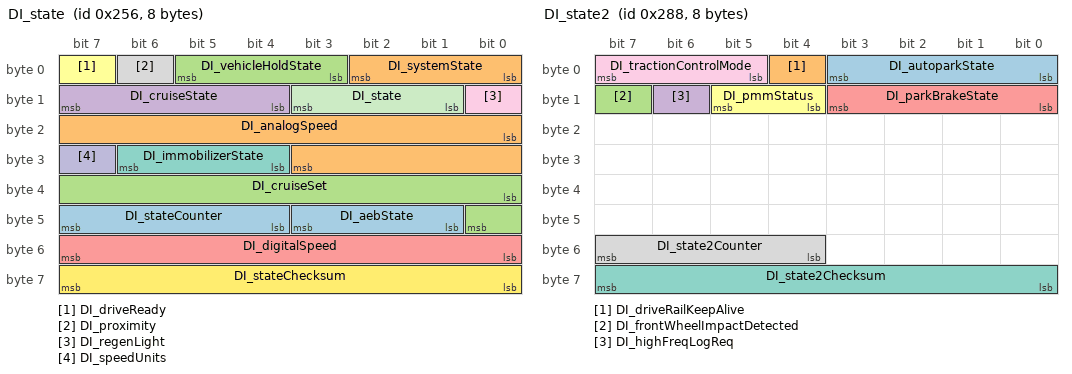
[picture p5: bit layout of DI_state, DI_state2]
BO_ 598 DI_state: 8 ETH
 SG_ DI_aebState: 41|3@1+ (1,0) [0|0] "" X
 SG_ DI_analogSpeed: 16|12@1+ (0.1,0) [0|0] "speed" X
 SG_ DI_cruiseSet: 32|9@1+ (0.5,0) [0|0] "speed" X
 SG_ DI_cruiseState: 12|4@1+ (1,0) [0|0] "" X
 SG_ DI_digitalSpeed: 48|8@1+ (1,0) [0|0] "" X
 SG_ DI_driveReady: 7|1@1+ (1,0) [0|0] "" X
 SG_ DI_immobilizerState: 28|3@1+ (1,0) [0|0] "" X
 SG_ DI_proximity: 6|1@1+ (1,0) [0|0] "" X
 SG_ DI_regenLight: 8|1@1+ (1,0) [0|0] "" X
 SG_ DI_speedUnits: 31|1@1+ (1,0) [0|0] "" X
 SG_ DI_state: 9|3@1+ (1,0) [0|0] "" X
 SG_ DI_stateChecksum: 56|8@1+ (1,0) [0|0] "" X
 SG_ DI_stateCounter: 44|4@1+ (1,0) [0|0] "" X
 SG_ DI_systemState: 0|3@1+ (1,0) [0|0] "" X
 SG_ DI_vehicleHoldState: 3|3@1+ (1,0) [0|0] "" X

BO_ 648 DI_state2: 8 ETH
 SG_ DI_autoparkState: 0|4@1+ (1,0) [0|0] "" X
 SG_ DI_driveRailKeepAlive: 4|1@1+ (1,0) [0|0] "" X
 SG_ DI_frontWheelImpactDetected: 15|1@1+ (1,0) [0|0] "" X
 SG_ DI_highFreqLogReq: 14|1@1+ (1,0) [0|0] "" X
 SG_ DI_parkBrakeState: 8|4@1+ (1,0) [0|0] "" X
 SG_ DI_pmmStatus: 12|2@1+ (1,0) [0|0] "" X
 SG_ DI_state2Checksum: 56|8@1+ (1,0) [0|0] "" X
 SG_ DI_state2Counter: 52|4@1+ (1,0) [0|0] "" X
 SG_ DI_tractionControlMode: 5|3@1+ (1,0) [0|0] "" X

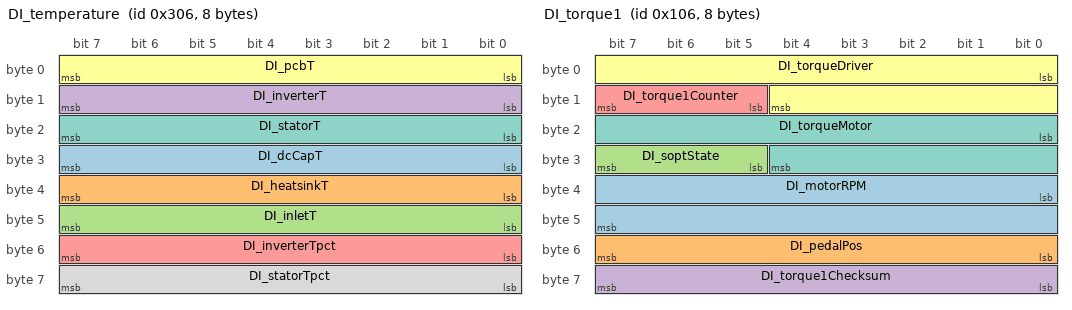
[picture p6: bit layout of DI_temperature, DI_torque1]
BO_ 774 DI_temperature: 8 ETH
 SG_ DI_dcCapT: 24|8@1+ (1,-40) [0|0] "DegC" X
 SG_ DI_heatsinkT: 32|8@1+ (1,-40) [0|0] "DegC" X
 SG_ DI_inletT: 40|8@1+ (1,-40) [0|0] "DegC" X
 SG_ DI_inverterT: 8|8@1+ (1,-40) [0|0] "DegC" X
 SG_ DI_inverterTpct: 48|8@1+ (0.4,0) [0|0] "%" X
 SG_ DI_pcbT: 0|8@1+ (1,-40) [0|0] "DegC" X
 SG_ DI_statorT: 16|8@1+ (1,-40) [0|0] "DegC" X
 SG_ DI_statorTpct: 56|8@1+ (0.4,0) [0|0] "%" X

BO_ 262 DI_torque1: 8 ETH
 SG_ DI_motorRPM: 32|16@1- (1,0) [0|0] "RPM" X
 SG_ DI_pedalPos: 48|8@1+ (0.4,0) [0|0] "%" X
 SG_ DI_soptState: 29|3@1+ (1,0) [0|0] "" X
 SG_ DI_torque1Checksum: 56|8@1+ (1,0) [0|0] "" X
 SG_ DI_torque1Counter: 13|3@1+ (1,0) [0|0] "" X
 SG_ DI_torqueDriver: 0|13@1- (0.25,0) [0|0] "Nm" X
 SG_ DI_torqueMotor: 16|13@1- (0.25,0) [0|0] "Nm" X

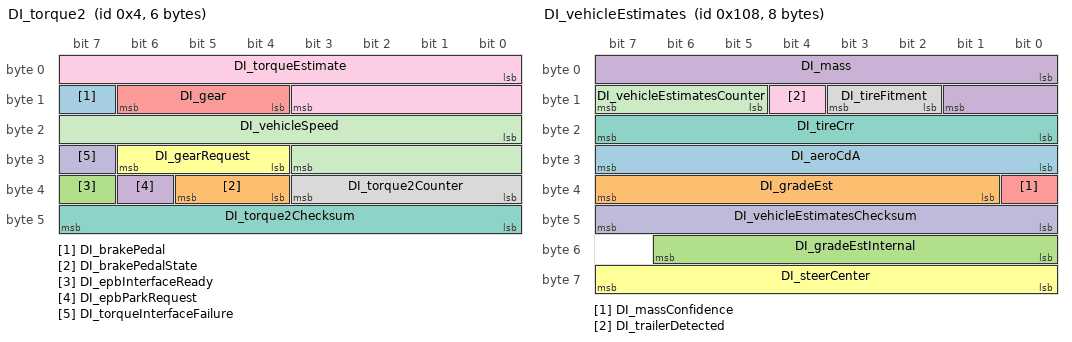
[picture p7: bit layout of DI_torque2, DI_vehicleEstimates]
BO_ 4 DI_torque2: 6 ETH
 SG_ DI_brakePedal: 15|1@1+ (1,0) [0|0] "" X
 SG_ DI_brakePedalState: 36|2@1+ (1,0) [0|0] "" X
 SG_ DI_epbInterfaceReady: 39|1@1+ (1,0) [0|0] "" X
 SG_ DI_epbParkRequest: 38|1@1+ (1,0) [0|0] "" X
 SG_ DI_gear: 12|3@1+ (1,0) [0|0] "" X
 SG_ DI_gearRequest: 28|3@1+ (1,0) [0|0] "" X
 SG_ DI_torque2Checksum: 40|8@1+ (1,0) [0|0] "" X
 SG_ DI_torque2Counter: 32|4@1+ (1,0) [0|0] "" X
 SG_ DI_torqueEstimate: 0|12@1- (0.5,0) [0|0] "Nm" X
 SG_ DI_torqueInterfaceFailure: 31|1@1+ (1,0) [0|0] "" X
 SG_ DI_vehicleSpeed: 16|12@1+ (0.05,-25) [0|0] "MPH" X

BO_ 1558 DI_udsResponse: 8 ETH
 SG_ DI_udsResponseData: 0|54@0+ (1024,0) [0|0] "" X

BO_ 264 DI_vehicleEstimates: 8 ETH
 SG_ DI_aeroCdA: 24|8@1+ (0.005,0.5) [0|0] "m^2" X
 SG_ DI_gradeEst: 33|7@1- (1,0) [0|0] "%" X
 SG_ DI_gradeEstInternal: 48|7@1- (1,0) [0|0] "%" X
 SG_ DI_mass: 0|10@1+ (5,1900) [0|0] "kg" X
 SG_ DI_massConfidence: 32|1@1+ (1,0) [0|0] "" X
 SG_ DI_steerCenter: 56|8@1- (0.2,0) [0|0] "deg" X
 SG_ DI_tireCrr: 16|8@1+ (5e-05,0.005) [0|0] "N/N" X
 SG_ DI_tireFitment: 10|2@1+ (1,0) [0|0] "" X
 SG_ DI_trailerDetected: 12|1@1+ (1,0) [0|0] "" X
 SG_ DI_vehicleEstimatesChecksum: 40|8@1+ (1,0) [0|0] "" X
 SG_ DI_vehicleEstimatesCounter: 13|3@1+ (1,0) [0|0] "" X

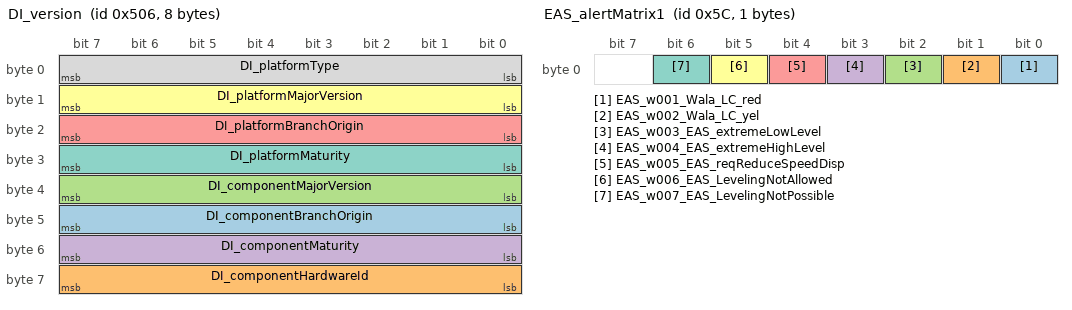
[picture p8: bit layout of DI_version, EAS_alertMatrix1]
BO_ 1286 DI_version: 8 ETH
 SG_ DI_componentBranchOrigin: 40|8@1+ (1,0) [0|0] "" X
 SG_ DI_componentHardwareId: 56|8@1+ (1,0) [0|0] "" X
 SG_ DI_componentMajorVersion: 32|8@1+ (1,0) [0|0] "" X
 SG_ DI_componentMaturity: 48|8@1+ (1,0) [0|0] "" X
 SG_ DI_platformBranchOrigin: 16|8@1+ (1,0) [0|0] "" X
 SG_ DI_platformMajorVersion: 8|8@1+ (1,0) [0|0] "" X
 SG_ DI_platformMaturity: 24|8@1+ (1,0) [0|0] "" X
 SG_ DI_platformType: 0|8@1+ (1,0) [0|0] "" X

BO_ 1156 D_RS_SCCM: 8 ETH
 SG_ D_RS_SCCM: 0|54@0+ (1024,0) [0|0] "" X

BO_ 92 EAS_alertMatrix1: 1 ETH
 SG_ EAS_w001_Wala_LC_red: 0|1@1+ (1,0) [0|0] "" X
 SG_ EAS_w002_Wala_LC_yel: 1|1@1+ (1,0) [0|0] "" X
 SG_ EAS_w003_EAS_extremeLowLevel: 2|1@1+ (1,0) [0|0] "" X
 SG_ EAS_w004_EAS_extremeHighLevel: 3|1@1+ (1,0) [0|0] "" X
 SG_ EAS_w005_EAS_reqReduceSpeedDisp: 4|1@1+ (1,0) [0|0] "" X
 SG_ EAS_w006_EAS_LevelingNotAllowed: 5|1@1+ (1,0) [0|0] "" X
 SG_ EAS_w007_EAS_LevelingNotPossible: 6|1@1+ (1,0) [0|0] "" X

BO_ 560 EFUSE_alertMatrix: 8 ETH
 SG_ EFUSE_matrixIndex M: 0|4@1+ (1,0) [0|0] "" X
 SG_ EFUSE_w001_WatchdogReset m0: 4|1@1+ (1,0) [0|0] "" X
 SG_ EFUSE_w002_PowerLossReset m0: 5|1@1+ (1,0) [0|0] "" X
 SG_ EFUSE_w003_SWAssertion m0: 6|1@1+ (1,0) [0|0] "" X
 SG_ EFUSE_w010_ExtSupplyVoltError m0: 13|1@1+ (1,0) [0|0] "" X
 SG_ EFUSE_w012_CPUReset m0: 15|1@1+ (1,0) [0|0] "" X
 SG_ EFUSE_w013_AlertManagerFault m0: 16|1@1+ (1,0) [0|0] "" X
 SG_ EFUSE_w015_NVMMAlert m0: 18|1@1+ (1,0) [0|0] "" X
 SG_ EFUSE_w021_TaskSchedulerError m0: 24|1@1+ (1,0) [0|0] "" X
 SG_ EFUSE_w022_TaskInitError m0: 25|1@1+ (1,0) [0|0] "" X
 SG_ EFUSE_w030_ECULogUploadRequest m0: 33|1@1+ (1,0) [0|0] "" X
 SG_ EFUSE_w031_UDSActive m0: 34|1@1+ (1,0) [0|0] "" X
 SG_ EFUSE_w041_HighCPULoad m0: 44|1@1+ (1,0) [0|0] "" X
 SG_ EFUSE_w042_HighStackUsage m0: 45|1@1+ (1,0) [0|0] "" X
 SG_ EFUSE_w043_Task1msError m0: 46|1@1+ (1,0) [0|0] "" X
 SG_ EFUSE_w044_Task10msError m0: 47|1@1+ (1,0) [0|0] "" X
 SG_ EFUSE_w045_Task100msError m0: 48|1@1+ (1,0) [0|0] "" X
 SG_ EFUSE_w046_Task1000msError m0: 49|1@1+ (1,0) [0|0] "" X
 SG_ EFUSE_w059_inputResistanceHigh m0: 62|1@1+ (1,0) [0|0] "" X
 SG_ EFUSE_w060_engineeringBuild m0: 63|1@1+ (1,0) [0|0] "" X
 SG_ EFUSE_w061_XCPConnected m1: 4|1@1+ (1,0) [0|0] "" X
 SG_ EFUSE_w062_XCPWasConnected m1: 5|1@1+ (1,0) [0|0] "" X
 SG_ EFUSE_w063_SwitchFault m1: 6|1@1+ (1,0) [0|0] "" X
 SG_ EFUSE_w064_busSleepReqTimeout m1: 7|1@1+ (1,0) [0|0] "" X
 SG_ EFUSE_w127_vBatFusedEFuseTrip m2: 10|1@1+ (1,0) [0|0] "" X
 SG_ EFUSE_w128_dcdcEFuseTrip m2: 11|1@1+ (1,0) [0|0] "" X
 SG_ EFUSE_w129_frunkBECEFuseTrip m2: 12|1@1+ (1,0) [0|0] "" X
 SG_ EFUSE_w130_epas1EFuseTrip m2: 13|1@1+ (1,0) [0|0] "" X
 SG_ EFUSE_w131_epas2EFuseTrip m2: 14|1@1+ (1,0) [0|0] "" X
 SG_ EFUSE_w132_cabinBECEFuseTrip m2: 15|1@1+ (1,0) [0|0] "" X
 SG_ EFUSE_w133_hcuEspAbsEFuseTrip m2: 16|1@1+ (1,0) [0|0] "" X
 SG_ EFUSE_w134_IBoosterEFuseTrip m2: 17|1@1+ (1,0) [0|0] "" X
 SG_ EFUSE_w135_condenserFanEFuseTrip m2: 18|1@1+ (1,0) [0|0] "" X
 SG_ EFUSE_w136_loadshedEvent m2: 19|1@1+ (1,0) [0|0] "" X
 SG_ EFUSE_w137_didNotSleep m2: 20|1@1+ (1,0) [0|0] "" X
 SG_ EFUSE_w138_vBatFusedSelfTestFail m2: 21|1@1+ (1,0) [0|0] "" X
 SG_ EFUSE_w139_dcdcSelfTestFail m2: 22|1@1+ (1,0) [0|0] "" X
 SG_ EFUSE_w140_frunkBECSelfTestFail m2: 23|1@1+ (1,0) [0|0] "" X
 SG_ EFUSE_w141_epas1SelfTestFail m2: 24|1@1+ (1,0) [0|0] "" X
 SG_ EFUSE_w142_epas2SelfTestFail m2: 25|1@1+ (1,0) [0|0] "" X
 SG_ EFUSE_w143_cabinBECSelfTestFail m2: 26|1@1+ (1,0) [0|0] "" X
 SG_ EFUSE_w144_hcuEspAbsSelfTestFail m2: 27|1@1+ (1,0) [0|0] "" X
 SG_ EFUSE_w145_IBoosterSelfTestFail m2: 28|1@1+ (1,0) [0|0] "" X
 SG_ EFUSE_w146_cndnserFanSlfTestFail m2: 29|1@1+ (1,0) [0|0] "" X
 SG_ EFUSE_w147_frunkOverCurrent m2: 30|1@1+ (1,0) [0|0] "" X
 SG_ EFUSE_w148_cabinOverCurrent m2: 31|1@1+ (1,0) [0|0] "" X
 SG_ EFUSE_w149_lockoutMalfunction m2: 32|1@1+ (1,0) [0|0] "" X
 SG_ EFUSE_w150_I2CFault m2: 33|1@1+ (1,0) [0|0] "" X
 SG_ EFUSE_w151_airCompUnderCurrent m2: 34|1@1+ (1,0) [0|0] "" X
 SG_ EFUSE_w152_airCompDriverFault m2: 35|1@1+ (1,0) [0|0] "" X
 SG_ EFUSE_w153_revBattEFuseTrip m2: 36|1@1+ (1,0) [0|0] "" X
 SG_ EFUSE_w154_revBattRetry m2: 37|1@1+ (1,0) [0|0] "" X
 SG_ EFUSE_w155_12VTempSensDiscnect m2: 38|1@1+ (1,0) [0|0] "" X
 SG_ EFUSE_w156_12VTempSensShort m2: 39|1@1+ (1,0) [0|0] "" X
 SG_ EFUSE_w157_voltageOutOfSpec m2: 40|1@1+ (1,0) [0|0] "" X
 SG_ EFUSE_w158_airCompOutputStuckOn m2: 41|1@1+ (1,0) [0|0] "" X
 SG_ EFUSE_w159_revBattFaulted m2: 42|1@1+ (1,0) [0|0] "" X

BO_ 1745 EFUSE_udsResponse: 8 ETH
 SG_ EFUSE_udsResponseData: 0|54@0+ (1024,0) [0|0] "" X

BO_ 912 EPAS2_dtcMatrix: 8 ETH
 SG_ EPAS2_matrixIndex M: 0|8@1+ (1,0) [0|0] "" X
 SG_ EPAS2_d001_csuFail m0: 8|2@1+ (1,0) [0|0] "" X
 SG_ EPAS2_d002_csvFail m0: 10|2@1+ (1,0) [0|0] "" X
 SG_ EPAS2_d003_runningReset m0: 12|2@1+ (1,0) [0|0] "" X
 SG_ EPAS2_d004_gateDriverEn m0: 14|2@1+ (1,0) [0|0] "" X
 SG_ EPAS2_d005_subTx m0: 16|2@1+ (1,0) [0|0] "" X
 SG_ EPAS2_d006_rlyOpen m0: 18|2@1+ (1,0) [0|0] "" X
 SG_ EPAS2_d007_rlyShort m0: 20|2@1+ (1,0) [0|0] "" X
 SG_ EPAS2_d008_programFlow m0: 22|2@1+ (1,0) [0|0] "" X
 SG_ EPAS2_d009_sentCrcError2 m0: 24|2@1+ (1,0) [0|0] "" X
 SG_ EPAS2_d010_sentCrcError1 m0: 26|2@1+ (1,0) [0|0] "" X
 SG_ EPAS2_d011_sentTimeOut2 m0: 28|2@1+ (1,0) [0|0] "" X
 SG_ EPAS2_d012_sentTimeOut1 m0: 30|2@1+ (1,0) [0|0] "" X
 SG_ EPAS2_d013_sentDiff m0: 32|2@1+ (1,0) [0|0] "" X
 SG_ EPAS2_d014_sent2 m0: 34|2@1+ (1,0) [0|0] "" X
 SG_ EPAS2_d015_sent1 m0: 36|2@1+ (1,0) [0|0] "" X
 SG_ EPAS2_d016_sentSyncTime2 m0: 38|2@1+ (1,0) [0|0] "" X
 SG_ EPAS2_d017_sentSyncTime1 m0: 40|2@1+ (1,0) [0|0] "" X
 SG_ EPAS2_d018_compatibleId m0: 42|2@1+ (1,0) [0|0] "" X
 SG_ EPAS2_d019_mainInterlock m0: 44|2@1+ (1,0) [0|0] "" X
 SG_ EPAS2_d020_posAbs m0: 46|2@1+ (1,0) [0|0] "" X
 SG_ EPAS2_d021_strokeOv m0: 48|2@1+ (1,0) [0|0] "" X
 SG_ EPAS2_d022_motIdiff m0: 50|2@1+ (1,0) [0|0] "" X
 SG_ EPAS2_d023_motOvc m0: 52|2@1+ (1,0) [0|0] "" X
 SG_ EPAS2_d024_gndFault m0: 54|2@1+ (1,0) [0|0] "" X
 SG_ EPAS2_d025_motShort m0: 56|2@1+ (1,0) [0|0] "" X
 SG_ EPAS2_d026_motOpen m0: 58|2@1+ (1,0) [0|0] "" X
 SG_ EPAS2_d027_svcc5 m0: 60|2@1+ (1,0) [0|0] "" X
 SG_ EPAS2_d028_svcc52 m0: 62|2@1+ (1,0) [0|0] "" X
 SG_ EPAS2_d029_variantCheck m1: 8|2@1+ (1,0) [0|0] "" X
 SG_ EPAS2_d030_batSigOpen m1: 10|2@1+ (1,0) [0|0] "" X
 SG_ EPAS2_d031_offsetOver m1: 12|2@1+ (1,0) [0|0] "" X
 SG_ EPAS2_d032_subSpiTime m1: 14|2@1+ (1,0) [0|0] "" X
 SG_ EPAS2_d033_subWatchdog m1: 16|2@1+ (1,0) [0|0] "" X
 SG_ EPAS2_d034_batUv m1: 18|2@1+ (1,0) [0|0] "" X
 SG_ EPAS2_d035_batOv m1: 20|2@1+ (1,0) [0|0] "" X
 SG_ EPAS2_d036_posInc m1: 22|2@1+ (1,0) [0|0] "" X
 SG_ EPAS2_d037_precharge m1: 24|2@1+ (1,0) [0|0] "" X
 SG_ EPAS2_d038_ceOpen m1: 26|2@1+ (1,0) [0|0] "" X
 SG_ EPAS2_d039_prechargeWl m1: 28|2@1+ (1,0) [0|0] "" X
 SG_ EPAS2_d040_offsetDiff m1: 30|2@1+ (1,0) [0|0] "" X
 SG_ EPAS2_d041_tempSensError m1: 32|2@1+ (1,0) [0|0] "" X
 SG_ EPAS2_d042_overHeatProtect m1: 34|2@1+ (1,0) [0|0] "" X
 SG_ EPAS2_d043_eepromError m1: 36|2@1+ (1,0) [0|0] "" X
 SG_ EPAS2_d044_trqSensCal m1: 38|2@1+ (1,0) [0|0] "" X
 SG_ EPAS2_d045_currentSensCal m1: 40|2@1+ (1,0) [0|0] "" X
 SG_ EPAS2_d046_canBusOff m1: 42|2@1+ (1,0) [0|0] "" X
 SG_ EPAS2_d047_dasMia m1: 44|2@1+ (1,0) [0|0] "" X
 SG_ EPAS2_d048_dasCntError m1: 46|2@1+ (1,0) [0|0] "" X
 SG_ EPAS2_d049_dasCsError m1: 48|2@1+ (1,0) [0|0] "" X
 SG_ EPAS2_d050_espWsMia m1: 50|2@1+ (1,0) [0|0] "" X
 SG_ EPAS2_d051_espWsCntError m1: 52|2@1+ (1,0) [0|0] "" X
 SG_ EPAS2_d052_espWsCsError m1: 54|2@1+ (1,0) [0|0] "" X
 SG_ EPAS2_d053_espbMia m1: 56|2@1+ (1,0) [0|0] "" X
 SG_ EPAS2_d054_espbCntError m1: 58|2@1+ (1,0) [0|0] "" X
 SG_ EPAS2_d055_espbCsError m1: 60|2@1+ (1,0) [0|0] "" X
 SG_ EPAS2_d056_espbQf m1: 62|2@1+ (1,0) [0|0] "" X
 SG_ EPAS2_d057_espcMia m2: 8|2@1+ (1,0) [0|0] "" X
 SG_ EPAS2_d058_espcCntError m2: 10|2@1+ (1,0) [0|0] "" X
 SG_ EPAS2_d059_espcCsError m2: 12|2@1+ (1,0) [0|0] "" X
 SG_ EPAS2_d060_espcQf m2: 14|2@1+ (1,0) [0|0] "" X
 SG_ EPAS2_d061_gtwMia m2: 16|2@1+ (1,0) [0|0] "" X
 SG_ EPAS2_d062_gtwCntError m2: 18|2@1+ (1,0) [0|0] "" X
 SG_ EPAS2_d063_gtwCsError m2: 20|2@1+ (1,0) [0|0] "" X
 SG_ EPAS2_d064_epbMia m2: 22|2@1+ (1,0) [0|0] "" X
 SG_ EPAS2_d065_epbCntError m2: 24|2@1+ (1,0) [0|0] "" X
 SG_ EPAS2_d066_epbCsError m2: 26|2@1+ (1,0) [0|0] "" X
 SG_ EPAS2_d067_diMia m2: 28|2@1+ (1,0) [0|0] "" X
 SG_ EPAS2_d068_diCntError m2: 30|2@1+ (1,0) [0|0] "" X
 SG_ EPAS2_d069_diCsError m2: 32|2@1+ (1,0) [0|0] "" X
 SG_ EPAS2_d070_sasMia m2: 34|2@1+ (1,0) [0|0] "" X
 SG_ EPAS2_d071_sasCntError m2: 36|2@1+ (1,0) [0|0] "" X
 SG_ EPAS2_d072_sasCsError m2: 38|2@1+ (1,0) [0|0] "" X
 SG_ EPAS2_d073_sasStat m2: 40|2@1+ (1,0) [0|0] "" X
 SG_ EPAS2_d074_eacCancelled m2: 42|2@1+ (1,0) [0|0] "" X
 SG_ EPAS2_d075_espWsQf m2: 44|2@1+ (1,0) [0|0] "" X
 SG_ EPAS2_d076_gtwOdoMia m2: 46|2@1+ (1,0) [0|0] "" X
 SG_ EPAS2_d077_pinionVelDiff m2: 48|2@1+ (1,0) [0|0] "" X
 SG_ EPAS2_d078_can2BusOff m2: 50|2@1+ (1,0) [0|0] "" X
 SG_ EPAS2_d079_espPrivate1Mia m2: 52|2@1+ (1,0) [0|0] "" X
 SG_ EPAS2_d080_abnormalShutdown m2: 54|2@1+ (1,0) [0|0] "" X

BO_ 914 EPAS3P_dtcMatrix: 8 ETH
 SG_ EPAS3P_matrixIndex M: 0|8@1+ (1,0) [0|0] "" X
 SG_ EPAS3P_d001_sent1Mia m0: 8|2@1+ (1,0) [0|0] "" X
 SG_ EPAS3P_d002_sent1Error m0: 10|2@1+ (1,0) [0|0] "" X
 SG_ EPAS3P_d003_trqSens1Supply m0: 12|2@1+ (1,0) [0|0] "" X
 SG_ EPAS3P_d004_trqSens1Eeprom m0: 14|2@1+ (1,0) [0|0] "" X
 SG_ EPAS3P_d005_sent2Mia m0: 16|2@1+ (1,0) [0|0] "" X
 SG_ EPAS3P_d006_sent2Error m0: 18|2@1+ (1,0) [0|0] "" X
 SG_ EPAS3P_d007_trqSens2Supply m0: 20|2@1+ (1,0) [0|0] "" X
 SG_ EPAS3P_d008_trqSens2Eeprom m0: 22|2@1+ (1,0) [0|0] "" X
 SG_ EPAS3P_d009_sentDiff m0: 24|2@1+ (1,0) [0|0] "" X
 SG_ EPAS3P_d010_trqSensCalError m0: 26|2@1+ (1,0) [0|0] "" X
 SG_ EPAS3P_d011_currentSensError m0: 28|2@1+ (1,0) [0|0] "" X
 SG_ EPAS3P_d012_currentSensCalError m0: 30|2@1+ (1,0) [0|0] "" X
 SG_ EPAS3P_d013_gateDriveError m0: 32|2@1+ (1,0) [0|0] "" X
 SG_ EPAS3P_d014_gateDriveTxError m0: 34|2@1+ (1,0) [0|0] "" X
 SG_ EPAS3P_d015_gateDriveEeprom m0: 36|2@1+ (1,0) [0|0] "" X
 SG_ EPAS3P_d016_phaseUhighUv m0: 38|2@1+ (1,0) [0|0] "" X
 SG_ EPAS3P_d017_phaseUlowUv m0: 40|2@1+ (1,0) [0|0] "" X
 SG_ EPAS3P_d018_phaseVhighUv m0: 42|2@1+ (1,0) [0|0] "" X
 SG_ EPAS3P_d019_phaseVlowUv m0: 44|2@1+ (1,0) [0|0] "" X
 SG_ EPAS3P_d020_phaseWhighUv m0: 46|2@1+ (1,0) [0|0] "" X
 SG_ EPAS3P_d021_phaseWlowUv m0: 48|2@1+ (1,0) [0|0] "" X
 SG_ EPAS3P_d022_phaseUhighOv m0: 50|2@1+ (1,0) [0|0] "" X
 SG_ EPAS3P_d023_phaseUlowOv m0: 52|2@1+ (1,0) [0|0] "" X
 SG_ EPAS3P_d024_phaseVhighOv m0: 54|2@1+ (1,0) [0|0] "" X
 SG_ EPAS3P_d025_phaseVlowOv m0: 56|2@1+ (1,0) [0|0] "" X
 SG_ EPAS3P_d026_phaseWhighOv m0: 58|2@1+ (1,0) [0|0] "" X
 SG_ EPAS3P_d027_phaseWlowOv m0: 60|2@1+ (1,0) [0|0] "" X
 SG_ EPAS3P_d028_phaseUbootUv m0: 62|2@1+ (1,0) [0|0] "" X
 SG_ EPAS3P_d029_phaseVbootUv m1: 8|2@1+ (1,0) [0|0] "" X
 SG_ EPAS3P_d030_phaseWbootUv m1: 10|2@1+ (1,0) [0|0] "" X
 SG_ EPAS3P_d031_abnormalShutdown m1: 12|2@1+ (1,0) [0|0] "" X
 SG_ EPAS3P_d032_vRegOutputUv m1: 14|2@1+ (1,0) [0|0] "" X
 SG_ EPAS3P_d033_vRegOutputOv m1: 16|2@1+ (1,0) [0|0] "" X
 SG_ EPAS3P_d034_vRegError m1: 18|2@1+ (1,0) [0|0] "" X
 SG_ EPAS3P_d035_vbbSupplyUv m1: 20|2@1+ (1,0) [0|0] "" X
 SG_ EPAS3P_d036_vbbSupplyOv m1: 22|2@1+ (1,0) [0|0] "" X
 SG_ EPAS3P_d037_motPos1ParityError m1: 24|2@1+ (1,0) [0|0] "" X
 SG_ EPAS3P_d038_motPos1Uv m1: 26|2@1+ (1,0) [0|0] "" X
 SG_ EPAS3P_d039_motPos1MagnetMia m1: 28|2@1+ (1,0) [0|0] "" X
 SG_ EPAS3P_d040_motPos1LogicError m1: 30|2@1+ (1,0) [0|0] "" X
 SG_ EPAS3P_d041_motPos1tempError m1: 32|2@1+ (1,0) [0|0] "" X
 SG_ EPAS3P_d042_motPos2ParityError m1: 34|2@1+ (1,0) [0|0] "" X
 SG_ EPAS3P_d043_motPos2Uv m1: 36|2@1+ (1,0) [0|0] "" X
 SG_ EPAS3P_d044_motPos2MagnetMia m1: 38|2@1+ (1,0) [0|0] "" X
 SG_ EPAS3P_d045_motPos2LogicError m1: 40|2@1+ (1,0) [0|0] "" X
 SG_ EPAS3P_d046_motPos2tempError m1: 42|2@1+ (1,0) [0|0] "" X
 SG_ EPAS3P_d047_motPosCorrError m1: 44|2@1+ (1,0) [0|0] "" X
 SG_ EPAS3P_d048_motPosCalError m1: 46|2@1+ (1,0) [0|0] "" X
 SG_ EPAS3P_d049_piCtrlError m1: 48|2@1+ (1,0) [0|0] "" X
 SG_ EPAS3P_d050_mcuSmuError m1: 50|2@1+ (1,0) [0|0] "" X
 SG_ EPAS3P_d051_mcuSupError m1: 52|2@1+ (1,0) [0|0] "" X
 SG_ EPAS3P_d052_intWatchdogError m1: 54|2@1+ (1,0) [0|0] "" X
 SG_ EPAS3P_d053_extWatchdogError m1: 56|2@1+ (1,0) [0|0] "" X
 SG_ EPAS3P_d054_memoryProtectError m1: 58|2@1+ (1,0) [0|0] "" X
 SG_ EPAS3P_d055_floatPointError m1: 60|2@1+ (1,0) [0|0] "" X
 SG_ EPAS3P_d056_battUv m1: 62|2@1+ (1,0) [0|0] "" X
 SG_ EPAS3P_d057_battUvReduced m2: 8|2@1+ (1,0) [0|0] "" X
 SG_ EPAS3P_d058_battOv m2: 10|2@1+ (1,0) [0|0] "" X
 SG_ EPAS3P_d059_battOvReduced m2: 12|2@1+ (1,0) [0|0] "" X
 SG_ EPAS3P_d060_battBridgeDiff m2: 14|2@1+ (1,0) [0|0] "" X
 SG_ EPAS3P_d061_bridgeUv m2: 16|2@1+ (1,0) [0|0] "" X
 SG_ EPAS3P_d062_assistCorrError m2: 18|2@1+ (1,0) [0|0] "" X
 SG_ EPAS3P_d063_dampCorrError m2: 20|2@1+ (1,0) [0|0] "" X
 SG_ EPAS3P_d064_phaseCompCorrError m2: 22|2@1+ (1,0) [0|0] "" X
 SG_ EPAS3P_d065_trqTarCorrError m2: 24|2@1+ (1,0) [0|0] "" X
 SG_ EPAS3P_d066_returnCorrError m2: 26|2@1+ (1,0) [0|0] "" X
 SG_ EPAS3P_d067_yawDampCorrError m2: 28|2@1+ (1,0) [0|0] "" X
 SG_ EPAS3P_d068_hystCorrError m2: 30|2@1+ (1,0) [0|0] "" X
 SG_ EPAS3P_d069_eacCorrError m2: 32|2@1+ (1,0) [0|0] "" X
 SG_ EPAS3P_d070_hodCorrError m2: 34|2@1+ (1,0) [0|0] "" X
 SG_ EPAS3P_d071_vehSpdCorrError m2: 36|2@1+ (1,0) [0|0] "" X
 SG_ EPAS3P_d072_motFeedFwdError m2: 38|2@1+ (1,0) [0|0] "" X
 SG_ EPAS3P_d073_motParEstError m2: 40|2@1+ (1,0) [0|0] "" X
 SG_ EPAS3P_d074_overHeatProtect m2: 42|2@1+ (1,0) [0|0] "" X
 SG_ EPAS3P_d075_fspPwrCut m2: 44|2@1+ (1,0) [0|0] "" X
 SG_ EPAS3P_d076_tempSensOutofRange m2: 46|2@1+ (1,0) [0|0] "" X
 SG_ EPAS3P_d077_highSideFetError m2: 48|2@1+ (1,0) [0|0] "" X
 SG_ EPAS3P_d078_phaseDisconnectError m2: 50|2@1+ (1,0) [0|0] "" X
 SG_ EPAS3P_d079_backupCurrentPlaus m2: 52|2@1+ (1,0) [0|0] "" X
 SG_ EPAS3P_d080_ecuInitArbError m2: 54|2@1+ (1,0) [0|0] "" X
 SG_ EPAS3P_d081_coggCompError m2: 56|2@1+ (1,0) [0|0] "" X
 SG_ EPAS3P_d082_polarityCalError m2: 58|2@1+ (1,0) [0|0] "" X
 SG_ EPAS3P_d083_crcMismatch m2: 60|2@1+ (1,0) [0|0] "" X
 SG_ EPAS3P_d084_eacCancelled m2: 62|2@1+ (1,0) [0|0] "" X
 SG_ EPAS3P_d085_canBusOff m3: 8|2@1+ (1,0) [0|0] "" X
 SG_ EPAS3P_d086_dasMia m3: 10|2@1+ (1,0) [0|0] "" X
 SG_ EPAS3P_d087_dasCntError m3: 12|2@1+ (1,0) [0|0] "" X
 SG_ EPAS3P_d088_dasCsError m3: 14|2@1+ (1,0) [0|0] "" X
 SG_ EPAS3P_d089_espWsMia m3: 16|2@1+ (1,0) [0|0] "" X
 SG_ EPAS3P_d090_espWsCntError m3: 18|2@1+ (1,0) [0|0] "" X
 SG_ EPAS3P_d091_espWsCsError m3: 20|2@1+ (1,0) [0|0] "" X
 SG_ EPAS3P_d092_espbMia m3: 22|2@1+ (1,0) [0|0] "" X
 SG_ EPAS3P_d093_espbCntError m3: 24|2@1+ (1,0) [0|0] "" X
 SG_ EPAS3P_d094_espbCsError m3: 26|2@1+ (1,0) [0|0] "" X
 SG_ EPAS3P_d095_espbQf m3: 28|2@1+ (1,0) [0|0] "" X
 SG_ EPAS3P_d096_espcMia m3: 30|2@1+ (1,0) [0|0] "" X
 SG_ EPAS3P_d097_espcCntError m3: 32|2@1+ (1,0) [0|0] "" X
 SG_ EPAS3P_d098_espcCsError m3: 34|2@1+ (1,0) [0|0] "" X
 SG_ EPAS3P_d099_espcQf m3: 36|2@1+ (1,0) [0|0] "" X
 SG_ EPAS3P_d100_gtwMia m3: 38|2@1+ (1,0) [0|0] "" X
 SG_ EPAS3P_d101_gtwCntError m3: 40|2@1+ (1,0) [0|0] "" X
 SG_ EPAS3P_d102_gtwCsError m3: 42|2@1+ (1,0) [0|0] "" X
 SG_ EPAS3P_d103_apsMia m3: 44|2@1+ (1,0) [0|0] "" X
 SG_ EPAS3P_d104_apsCntError m3: 46|2@1+ (1,0) [0|0] "" X
 SG_ EPAS3P_d105_apsCsError m3: 48|2@1+ (1,0) [0|0] "" X
 SG_ EPAS3P_d106_diMia m3: 50|2@1+ (1,0) [0|0] "" X
 SG_ EPAS3P_d107_diCntError m3: 52|2@1+ (1,0) [0|0] "" X
 SG_ EPAS3P_d108_diCsError m3: 54|2@1+ (1,0) [0|0] "" X
 SG_ EPAS3P_d109_sasMia m3: 56|2@1+ (1,0) [0|0] "" X
 SG_ EPAS3P_d110_sasCntError m3: 58|2@1+ (1,0) [0|0] "" X
 SG_ EPAS3P_d111_sasCsError m3: 60|2@1+ (1,0) [0|0] "" X
 SG_ EPAS3P_d112_sasStatError m3: 62|2@1+ (1,0) [0|0] "" X
 SG_ EPAS3P_d113_espWsQf m4: 8|2@1+ (1,0) [0|0] "" X
 SG_ EPAS3P_d114_gtwOdoMia m4: 10|2@1+ (1,0) [0|0] "" X
 SG_ EPAS3P_d115_ecuStatMia m4: 12|2@1+ (1,0) [0|0] "" X
 SG_ EPAS3P_d116_ecuStatCntError m4: 14|2@1+ (1,0) [0|0] "" X
 SG_ EPAS3P_d117_ecuStatCrcError m4: 16|2@1+ (1,0) [0|0] "" X
 SG_ EPAS3P_d118_espPriv1Mia m4: 18|2@1+ (1,0) [0|0] "" X
 SG_ EPAS3P_d119_espPriv1CntError m4: 20|2@1+ (1,0) [0|0] "" X
 SG_ EPAS3P_d120_espPriv1CsError m4: 22|2@1+ (1,0) [0|0] "" X
 SG_ EPAS3P_d121_espPriv1Qf m4: 24|2@1+ (1,0) [0|0] "" X
 SG_ EPAS3P_d122_privateBusOff m4: 26|2@1+ (1,0) [0|0] "" X
 SG_ EPAS3P_d123_pvtEcuStatMia m4: 28|2@1+ (1,0) [0|0] "" X
 SG_ EPAS3P_d124_pvtEcuStatCntError m4: 30|2@1+ (1,0) [0|0] "" X
 SG_ EPAS3P_d125_pvtEcuStatCrcError m4: 32|2@1+ (1,0) [0|0] "" X
 SG_ EPAS3P_d126_olpActive m4: 34|2@1+ (1,0) [0|0] "" X
 SG_ EPAS3P_d127_combEcu2StatFail m4: 36|2@1+ (1,0) [0|0] "" X
 SG_ EPAS3P_d128_tempSensStuckInRange m4: 38|2@1+ (1,0) [0|0] "" X
 SG_ EPAS3P_d129_trqSensTrimOutRange m4: 40|2@1+ (1,0) [0|0] "" X
 SG_ EPAS3P_d130_combEcu1StatFail m4: 42|2@1+ (1,0) [0|0] "" X
 SG_ EPAS3P_d131_sasOffsetNotCal m4: 44|2@1+ (1,0) [0|0] "" X
 SG_ EPAS3P_d132_phaseFeedbackError m4: 46|2@1+ (1,0) [0|0] "" X

BO_ 1592 EPAS3P_udsResponseCH: 8 ETH
 SG_ EPAS3P_udsResponseDataCH: 0|54@0+ (1024,0) [0|0] "" X

BO_ 913 EPAS3S_dtcMatrix: 8 ETH
 SG_ EPAS3S_matrixIndex M: 0|8@1+ (1,0) [0|0] "" X
 SG_ EPAS3S_d001_sent1Mia m0: 8|2@1+ (1,0) [0|0] "" X
 SG_ EPAS3S_d002_sent1Error m0: 10|2@1+ (1,0) [0|0] "" X
 SG_ EPAS3S_d003_trqSens1Supply m0: 12|2@1+ (1,0) [0|0] "" X
 SG_ EPAS3S_d004_trqSens1Eeprom m0: 14|2@1+ (1,0) [0|0] "" X
 SG_ EPAS3S_d005_sent2Mia m0: 16|2@1+ (1,0) [0|0] "" X
 SG_ EPAS3S_d006_sent2Error m0: 18|2@1+ (1,0) [0|0] "" X
 SG_ EPAS3S_d007_trqSens2Supply m0: 20|2@1+ (1,0) [0|0] "" X
 SG_ EPAS3S_d008_trqSens2Eeprom m0: 22|2@1+ (1,0) [0|0] "" X
 SG_ EPAS3S_d009_sentDiff m0: 24|2@1+ (1,0) [0|0] "" X
 SG_ EPAS3S_d010_trqSensCalError m0: 26|2@1+ (1,0) [0|0] "" X
 SG_ EPAS3S_d011_currentSensError m0: 28|2@1+ (1,0) [0|0] "" X
 SG_ EPAS3S_d012_currentSensCalError m0: 30|2@1+ (1,0) [0|0] "" X
 SG_ EPAS3S_d013_gateDriveError m0: 32|2@1+ (1,0) [0|0] "" X
 SG_ EPAS3S_d014_gateDriveTxError m0: 34|2@1+ (1,0) [0|0] "" X
 SG_ EPAS3S_d015_gateDriveEeprom m0: 36|2@1+ (1,0) [0|0] "" X
 SG_ EPAS3S_d016_phaseUhighUv m0: 38|2@1+ (1,0) [0|0] "" X
 SG_ EPAS3S_d017_phaseUlowUv m0: 40|2@1+ (1,0) [0|0] "" X
 SG_ EPAS3S_d018_phaseVhighUv m0: 42|2@1+ (1,0) [0|0] "" X
 SG_ EPAS3S_d019_phaseVlowUv m0: 44|2@1+ (1,0) [0|0] "" X
 SG_ EPAS3S_d020_phaseWhighUv m0: 46|2@1+ (1,0) [0|0] "" X
 SG_ EPAS3S_d021_phaseWlowUv m0: 48|2@1+ (1,0) [0|0] "" X
 SG_ EPAS3S_d022_phaseUhighOv m0: 50|2@1+ (1,0) [0|0] "" X
 SG_ EPAS3S_d023_phaseUlowOv m0: 52|2@1+ (1,0) [0|0] "" X
 SG_ EPAS3S_d024_phaseVhighOv m0: 54|2@1+ (1,0) [0|0] "" X
 SG_ EPAS3S_d025_phaseVlowOv m0: 56|2@1+ (1,0) [0|0] "" X
 SG_ EPAS3S_d026_phaseWhighOv m0: 58|2@1+ (1,0) [0|0] "" X
 SG_ EPAS3S_d027_phaseWlowOv m0: 60|2@1+ (1,0) [0|0] "" X
 SG_ EPAS3S_d028_phaseUbootUv m0: 62|2@1+ (1,0) [0|0] "" X
 SG_ EPAS3S_d029_phaseVbootUv m1: 8|2@1+ (1,0) [0|0] "" X
 SG_ EPAS3S_d030_phaseWbootUv m1: 10|2@1+ (1,0) [0|0] "" X
 SG_ EPAS3S_d031_abnormalShutdown m1: 12|2@1+ (1,0) [0|0] "" X
 SG_ EPAS3S_d032_vRegOutputUv m1: 14|2@1+ (1,0) [0|0] "" X
 SG_ EPAS3S_d033_vRegOutputOv m1: 16|2@1+ (1,0) [0|0] "" X
 SG_ EPAS3S_d034_vRegError m1: 18|2@1+ (1,0) [0|0] "" X
 SG_ EPAS3S_d035_vbbSupplyUv m1: 20|2@1+ (1,0) [0|0] "" X
 SG_ EPAS3S_d036_vbbSupplyOv m1: 22|2@1+ (1,0) [0|0] "" X
 SG_ EPAS3S_d037_motPos1ParityError m1: 24|2@1+ (1,0) [0|0] "" X
 SG_ EPAS3S_d038_motPos1Uv m1: 26|2@1+ (1,0) [0|0] "" X
 SG_ EPAS3S_d039_motPos1MagnetMia m1: 28|2@1+ (1,0) [0|0] "" X
 SG_ EPAS3S_d040_motPos1LogicError m1: 30|2@1+ (1,0) [0|0] "" X
 SG_ EPAS3S_d041_motPos1tempError m1: 32|2@1+ (1,0) [0|0] "" X
 SG_ EPAS3S_d042_motPos2ParityError m1: 34|2@1+ (1,0) [0|0] "" X
 SG_ EPAS3S_d043_motPos2Uv m1: 36|2@1+ (1,0) [0|0] "" X
 SG_ EPAS3S_d044_motPos2MagnetMia m1: 38|2@1+ (1,0) [0|0] "" X
 SG_ EPAS3S_d045_motPos2LogicError m1: 40|2@1+ (1,0) [0|0] "" X
 SG_ EPAS3S_d046_motPos2tempError m1: 42|2@1+ (1,0) [0|0] "" X
 SG_ EPAS3S_d047_motPosCorrError m1: 44|2@1+ (1,0) [0|0] "" X
 SG_ EPAS3S_d048_motPosCalError m1: 46|2@1+ (1,0) [0|0] "" X
 SG_ EPAS3S_d049_piCtrlError m1: 48|2@1+ (1,0) [0|0] "" X
 SG_ EPAS3S_d050_mcuSmuError m1: 50|2@1+ (1,0) [0|0] "" X
 SG_ EPAS3S_d051_mcuSupError m1: 52|2@1+ (1,0) [0|0] "" X
 SG_ EPAS3S_d052_intWatchdogError m1: 54|2@1+ (1,0) [0|0] "" X
 SG_ EPAS3S_d053_extWatchdogError m1: 56|2@1+ (1,0) [0|0] "" X
 SG_ EPAS3S_d054_memoryProtectError m1: 58|2@1+ (1,0) [0|0] "" X
 SG_ EPAS3S_d055_floatPointError m1: 60|2@1+ (1,0) [0|0] "" X
 SG_ EPAS3S_d056_battUv m1: 62|2@1+ (1,0) [0|0] "" X
 SG_ EPAS3S_d057_battUvReduced m2: 8|2@1+ (1,0) [0|0] "" X
 SG_ EPAS3S_d058_battOv m2: 10|2@1+ (1,0) [0|0] "" X
 SG_ EPAS3S_d059_battOvReduced m2: 12|2@1+ (1,0) [0|0] "" X
 SG_ EPAS3S_d060_battBridgeDiff m2: 14|2@1+ (1,0) [0|0] "" X
 SG_ EPAS3S_d061_bridgeUv m2: 16|2@1+ (1,0) [0|0] "" X
 SG_ EPAS3S_d062_assistCorrError m2: 18|2@1+ (1,0) [0|0] "" X
 SG_ EPAS3S_d063_dampCorrError m2: 20|2@1+ (1,0) [0|0] "" X
 SG_ EPAS3S_d064_phaseCompCorrError m2: 22|2@1+ (1,0) [0|0] "" X
 SG_ EPAS3S_d065_trqTarCorrError m2: 24|2@1+ (1,0) [0|0] "" X
 SG_ EPAS3S_d066_returnCorrError m2: 26|2@1+ (1,0) [0|0] "" X
 SG_ EPAS3S_d067_yawDampCorrError m2: 28|2@1+ (1,0) [0|0] "" X
 SG_ EPAS3S_d068_hystCorrError m2: 30|2@1+ (1,0) [0|0] "" X
 SG_ EPAS3S_d069_eacCorrError m2: 32|2@1+ (1,0) [0|0] "" X
 SG_ EPAS3S_d070_hodCorrError m2: 34|2@1+ (1,0) [0|0] "" X
 SG_ EPAS3S_d071_vehSpdCorrError m2: 36|2@1+ (1,0) [0|0] "" X
 SG_ EPAS3S_d072_motFeedFwdError m2: 38|2@1+ (1,0) [0|0] "" X
 SG_ EPAS3S_d073_motParEstError m2: 40|2@1+ (1,0) [0|0] "" X
 SG_ EPAS3S_d074_overHeatProtect m2: 42|2@1+ (1,0) [0|0] "" X
 SG_ EPAS3S_d075_fspPwrCut m2: 44|2@1+ (1,0) [0|0] "" X
 SG_ EPAS3S_d076_tempSensOutofRange m2: 46|2@1+ (1,0) [0|0] "" X
 SG_ EPAS3S_d077_highSideFetError m2: 48|2@1+ (1,0) [0|0] "" X
 SG_ EPAS3S_d078_phaseDisconnectError m2: 50|2@1+ (1,0) [0|0] "" X
 SG_ EPAS3S_d079_backupCurrentPlaus m2: 52|2@1+ (1,0) [0|0] "" X
 SG_ EPAS3S_d080_ecuInitArbError m2: 54|2@1+ (1,0) [0|0] "" X
 SG_ EPAS3S_d081_coggCompError m2: 56|2@1+ (1,0) [0|0] "" X
 SG_ EPAS3S_d082_polarityCalError m2: 58|2@1+ (1,0) [0|0] "" X
 SG_ EPAS3S_d083_crcMismatch m2: 60|2@1+ (1,0) [0|0] "" X
 SG_ EPAS3S_d084_eacCancelled m2: 62|2@1+ (1,0) [0|0] "" X
 SG_ EPAS3S_d085_canBusOff m3: 8|2@1+ (1,0) [0|0] "" X
 SG_ EPAS3S_d086_dasMia m3: 10|2@1+ (1,0) [0|0] "" X
 SG_ EPAS3S_d087_dasCntError m3: 12|2@1+ (1,0) [0|0] "" X
 SG_ EPAS3S_d088_dasCsError m3: 14|2@1+ (1,0) [0|0] "" X
 SG_ EPAS3S_d089_espWsMia m3: 16|2@1+ (1,0) [0|0] "" X
 SG_ EPAS3S_d090_espWsCntError m3: 18|2@1+ (1,0) [0|0] "" X
 SG_ EPAS3S_d091_espWsCsError m3: 20|2@1+ (1,0) [0|0] "" X
 SG_ EPAS3S_d092_espbMia m3: 22|2@1+ (1,0) [0|0] "" X
 SG_ EPAS3S_d093_espbCntError m3: 24|2@1+ (1,0) [0|0] "" X
 SG_ EPAS3S_d094_espbCsError m3: 26|2@1+ (1,0) [0|0] "" X
 SG_ EPAS3S_d095_espbQf m3: 28|2@1+ (1,0) [0|0] "" X
 SG_ EPAS3S_d096_espcMia m3: 30|2@1+ (1,0) [0|0] "" X
 SG_ EPAS3S_d097_espcCntError m3: 32|2@1+ (1,0) [0|0] "" X
 SG_ EPAS3S_d098_espcCsError m3: 34|2@1+ (1,0) [0|0] "" X
 SG_ EPAS3S_d099_espcQf m3: 36|2@1+ (1,0) [0|0] "" X
 SG_ EPAS3S_d100_gtwMia m3: 38|2@1+ (1,0) [0|0] "" X
 SG_ EPAS3S_d101_gtwCntError m3: 40|2@1+ (1,0) [0|0] "" X
 SG_ EPAS3S_d102_gtwCsError m3: 42|2@1+ (1,0) [0|0] "" X
 SG_ EPAS3S_d103_apsMia m3: 44|2@1+ (1,0) [0|0] "" X
 SG_ EPAS3S_d104_apsCntError m3: 46|2@1+ (1,0) [0|0] "" X
 SG_ EPAS3S_d105_apsCsError m3: 48|2@1+ (1,0) [0|0] "" X
 SG_ EPAS3S_d106_diMia m3: 50|2@1+ (1,0) [0|0] "" X
 SG_ EPAS3S_d107_diCntError m3: 52|2@1+ (1,0) [0|0] "" X
 SG_ EPAS3S_d108_diCsError m3: 54|2@1+ (1,0) [0|0] "" X
 SG_ EPAS3S_d109_sasMia m3: 56|2@1+ (1,0) [0|0] "" X
 SG_ EPAS3S_d110_sasCntError m3: 58|2@1+ (1,0) [0|0] "" X
 SG_ EPAS3S_d111_sasCsError m3: 60|2@1+ (1,0) [0|0] "" X
 SG_ EPAS3S_d112_sasStatError m3: 62|2@1+ (1,0) [0|0] "" X
 SG_ EPAS3S_d113_espWsQf m4: 8|2@1+ (1,0) [0|0] "" X
 SG_ EPAS3S_d114_gtwOdoMia m4: 10|2@1+ (1,0) [0|0] "" X
 SG_ EPAS3S_d115_ecuStatMia m4: 12|2@1+ (1,0) [0|0] "" X
 SG_ EPAS3S_d116_ecuStatCntError m4: 14|2@1+ (1,0) [0|0] "" X
 SG_ EPAS3S_d117_ecuStatCrcError m4: 16|2@1+ (1,0) [0|0] "" X
 SG_ EPAS3S_d118_espPriv1Mia m4: 18|2@1+ (1,0) [0|0] "" X
 SG_ EPAS3S_d119_espPriv1CntError m4: 20|2@1+ (1,0) [0|0] "" X
 SG_ EPAS3S_d120_espPriv1CsError m4: 22|2@1+ (1,0) [0|0] "" X
 SG_ EPAS3S_d121_espPriv1Qf m4: 24|2@1+ (1,0) [0|0] "" X
 SG_ EPAS3S_d122_privateBusOff m4: 26|2@1+ (1,0) [0|0] "" X
 SG_ EPAS3S_d123_pvtEcuStatMia m4: 28|2@1+ (1,0) [0|0] "" X
 SG_ EPAS3S_d124_pvtEcuStatCntError m4: 30|2@1+ (1,0) [0|0] "" X
 SG_ EPAS3S_d125_pvtEcuStatCrcError m4: 32|2@1+ (1,0) [0|0] "" X
 SG_ EPAS3S_d126_olpActive m4: 34|2@1+ (1,0) [0|0] "" X
 SG_ EPAS3S_d127_combEcu2StatFail m4: 36|2@1+ (1,0) [0|0] "" X
 SG_ EPAS3S_d128_tempSensStuckInRange m4: 38|2@1+ (1,0) [0|0] "" X
 SG_ EPAS3S_d129_trqSensTrimOutRange m4: 40|2@1+ (1,0) [0|0] "" X
 SG_ EPAS3S_d130_combEcu1StatFail m4: 42|2@1+ (1,0) [0|0] "" X
 SG_ EPAS3S_d131_sasOffsetNotCal m4: 44|2@1+ (1,0) [0|0] "" X
 SG_ EPAS3S_d132_phaseFeedbackError m4: 46|2@1+ (1,0) [0|0] "" X

BO_ 90 EPAS_alertMatrix1: 1 ETH
 SG_ EPAS_w001_steeringFault: 0|1@1+ (1,0) [0|0] "" X
 SG_ EPAS_w002_steeringReduced: 1|1@1+ (1,0) [0|0] "" X

BO_ 896 EPAS_dtcMatrix: 8 ETH
 SG_ EPAS_matrixIndex M: 0|8@1+ (1,0) [0|0] "" X
 SG_ EPAS_d001_KFC_STORQUE_0 m0: 8|2@1+ (1,0) [0|0] "" X
 SG_ EPAS_d002_KFC_NVRAM_MNG_READ m0: 10|2@1+ (1,0) [0|0] "" X
 SG_ EPAS_d003_KFC_NVRAM_MNG_WRITE m0: 12|2@1+ (1,0) [0|0] "" X
 SG_ EPAS_d004_KFC_NVRAM_MNG_VERIFY m0: 14|2@1+ (1,0) [0|0] "" X
 SG_ EPAS_d005_KFC_ASIC m0: 16|2@1+ (1,0) [0|0] "" X
 SG_ EPAS_d006_KFC_CLOCKMON m0: 18|2@1+ (1,0) [0|0] "" X
 SG_ EPAS_d007_KFC_OUTPUT_STAGE_DRV m0: 20|2@1+ (1,0) [0|0] "" X
 SG_ EPAS_d008_KFC_SHUT_DOWN m0: 22|2@1+ (1,0) [0|0] "" X
 SG_ EPAS_d009_KFC_WD_CHECK m0: 24|2@1+ (1,0) [0|0] "" X
 SG_ EPAS_d010_KFC_COMP_L1 m0: 26|2@1+ (1,0) [0|0] "" X
 SG_ EPAS_d011_KFC_COMP_L2 m0: 28|2@1+ (1,0) [0|0] "" X
 SG_ EPAS_d012_KFC_ADC m0: 30|2@1+ (1,0) [0|0] "" X
 SG_ EPAS_d013_KFC_UKL30_2H m0: 32|2@1+ (1,0) [0|0] "" X
 SG_ EPAS_d014_KFC_UKL30_2L m0: 34|2@1+ (1,0) [0|0] "" X
 SG_ EPAS_d015_KFC_UCU_RED m0: 36|2@1+ (1,0) [0|0] "" X
 SG_ EPAS_d016_KFC_CCU_RED m0: 38|2@1+ (1,0) [0|0] "" X
 SG_ EPAS_d017_KFC_UUT_RED m0: 40|2@1+ (1,0) [0|0] "" X
 SG_ EPAS_d018_KFC_UKL30_2H_OFF m0: 42|2@1+ (1,0) [0|0] "" X
 SG_ EPAS_d019_KFC_UKL30_2L_OFF m0: 44|2@1+ (1,0) [0|0] "" X
 SG_ EPAS_d020_KFC_RAM m0: 46|2@1+ (1,0) [0|0] "" X
 SG_ EPAS_d021_KFC_SPI_COM_TIMO m0: 48|2@1+ (1,0) [0|0] "" X
 SG_ EPAS_d022_KFC_SPI_SYNC_REG m0: 50|2@1+ (1,0) [0|0] "" X
 SG_ EPAS_d023_KFC_PWD m0: 52|2@1+ (1,0) [0|0] "" X
 SG_ EPAS_d024_KFC_PROGFLOW m0: 54|2@1+ (1,0) [0|0] "" X
 SG_ EPAS_d025_KFC_STORQUE_OC m0: 56|2@1+ (1,0) [0|0] "" X
 SG_ EPAS_d026_KFC_STORQUE_RAD m0: 58|2@1+ (1,0) [0|0] "" X
 SG_ EPAS_d027_KFC_FOR_TIMO m0: 60|2@1+ (1,0) [0|0] "" X
 SG_ EPAS_d028_KFC_PROG_WD m0: 62|2@1+ (1,0) [0|0] "" X
 SG_ EPAS_d029_KFC_CST m1: 8|2@1+ (1,0) [0|0] "" X
 SG_ EPAS_d030_KFC_REG_CHECK m1: 10|2@1+ (1,0) [0|0] "" X
 SG_ EPAS_d031_KFC_CR_RED m1: 12|2@1+ (1,0) [0|0] "" X
 SG_ EPAS_d032_KFC_ROM m1: 14|2@1+ (1,0) [0|0] "" X
 SG_ EPAS_d033_KFC_SWGEN m1: 16|2@1+ (1,0) [0|0] "" X
 SG_ EPAS_d034_KFC_FOR_OC m1: 18|2@1+ (1,0) [0|0] "" X
 SG_ EPAS_d035_KFC_FOR_WREL m1: 20|2@1+ (1,0) [0|0] "" X
 SG_ EPAS_d036_KFC_FOR_ANGLE m1: 22|2@1+ (1,0) [0|0] "" X
 SG_ EPAS_d037_KFC_FOR_LENGTH m1: 24|2@1+ (1,0) [0|0] "" X
 SG_ EPAS_d038_KFC_BUS_OFF m1: 26|2@1+ (1,0) [0|0] "" X
 SG_ EPAS_d039_KFC_RESET m1: 28|2@1+ (1,0) [0|0] "" X
 SG_ EPAS_d040_KFC_RSRADIUS m1: 30|2@1+ (1,0) [0|0] "" X
 SG_ EPAS_d041_KFC_U_REDUNDANT m1: 32|2@1+ (1,0) [0|0] "" X
 SG_ EPAS_d042_KFC_RSDIFF m1: 34|2@1+ (1,0) [0|0] "" X
 SG_ EPAS_d043_KFC_ESP_TIMO m1: 36|2@1+ (1,0) [0|0] "" X
 SG_ EPAS_d044_KFC_GTW_TIMO m1: 38|2@1+ (1,0) [0|0] "" X
 SG_ EPAS_d045_KFC_DI_Torque1_TIMO m1: 40|2@1+ (1,0) [0|0] "" X
 SG_ EPAS_d046_KFC_SAS_TIMO m1: 42|2@1+ (1,0) [0|0] "" X
 SG_ EPAS_d047_KFC_EACALLOW m1: 44|2@1+ (1,0) [0|0] "" X
 SG_ EPAS_d048_KFC_EPB_TIMO m1: 46|2@1+ (1,0) [0|0] "" X
 SG_ EPAS_d049_KFC_ESRA_CANCELLED m1: 48|2@1+ (1,0) [0|0] "" X
 SG_ EPAS_d050_KFC_STEERING_ANGLE m1: 50|2@1+ (1,0) [0|0] "" X
 SG_ EPAS_d051_KFC_VEHICLE_SPEED m1: 52|2@1+ (1,0) [0|0] "" X
 SG_ EPAS_d052_KFC_UNUSED_52 m1: 54|2@1+ (1,0) [0|0] "" X
 SG_ EPAS_d053_KFC_UNUSED_53 m1: 56|2@1+ (1,0) [0|0] "" X
 SG_ EPAS_d054_KFC_CCF_NOT_CONFIGURED m1: 58|2@1+ (1,0) [0|0] "" X
 SG_ EPAS_d055_KFC_CCF_INVALID m1: 60|2@1+ (1,0) [0|0] "" X
 SG_ EPAS_d056_KFC_UNUSED_56 m1: 62|2@1+ (1,0) [0|0] "" X
 SG_ EPAS_d057_KFC_FRICTION m2: 8|2@1+ (1,0) [0|0] "" X
 SG_ EPAS_d058_KFC_EXPULSION_MODE m2: 10|2@1+ (1,0) [0|0] "" X
 SG_ EPAS_d059_KFC_TEMP_DIAG_DEV m2: 12|2@1+ (1,0) [0|0] "" X
 SG_ EPAS_d060_KFC_POWER_MODE m2: 14|2@1+ (1,0) [0|0] "" X
 SG_ EPAS_d061_KFC_UNUSED_61 m2: 16|2@1+ (1,0) [0|0] "" X
 SG_ EPAS_d062_KFC_WHEEL_SPEEDS m2: 18|2@1+ (1,0) [0|0] "" X
 SG_ EPAS_d063_KFC_UNUSED_63 m2: 20|2@1+ (1,0) [0|0] "" X
 SG_ EPAS_d064_KFC_DI_MOTORRPM m2: 22|2@1+ (1,0) [0|0] "" X
 SG_ EPAS_d065_KFC_YAW_RATE m2: 24|2@1+ (1,0) [0|0] "" X
 SG_ EPAS_d066_KFC_UCU_RED_INFO m2: 26|2@1+ (1,0) [0|0] "" X
 SG_ EPAS_d067_KFC_CCU_RED_INFO m2: 28|2@1+ (1,0) [0|0] "" X
 SG_ EPAS_d068_KFC_UCO_RED_INFO m2: 30|2@1+ (1,0) [0|0] "" X
 SG_ EPAS_d069_KFC_CR_RED_INFO m2: 32|2@1+ (1,0) [0|0] "" X
 SG_ EPAS_d070_KFC_ROTANG m2: 34|2@1+ (1,0) [0|0] "" X
 SG_ EPAS_d071_KFC_PD_RED m2: 36|2@1+ (1,0) [0|0] "" X
 SG_ EPAS_d072_KFC_OS_MON m2: 38|2@1+ (1,0) [0|0] "" X
 SG_ EPAS_d073_KFC_UCO_RED m2: 40|2@1+ (1,0) [0|0] "" X
 SG_ EPAS_d074_KFC_SSW m2: 42|2@1+ (1,0) [0|0] "" X
 SG_ EPAS_d075_KFC_BLOCKED_STEERING m2: 44|2@1+ (1,0) [0|0] "" X
 SG_ EPAS_d076_KFC_DAS_TIMO m2: 46|2@1+ (1,0) [0|0] "" X
 SG_ EPAS_d077_KFC_STEERING_CONTROL m2: 48|2@1+ (1,0) [0|0] "" X

BO_ 1328 EPAS_info: 8 ETH
 SG_ EPAS_infoIndex M: 0|8@1+ (1,0) [0|0] "" X
 SG_ EPAS_infoBuildType m10: 8|8@1+ (1,0) [0|0] "" X
 SG_ EPAS_infoComponentID m10: 48|16@1+ (1,0) [0|0] "" X
 SG_ EPAS_infoPcbaID m11: 16|8@1+ (1,0) [0|0] "" X
 SG_ EPAS_infoAssemblyID m11: 24|8@1+ (1,0) [0|0] "" X
 SG_ EPAS_infoUsageID m11: 32|16@1+ (1,0) [0|0] "" X
 SG_ EPAS_infoBootUdsProtoVersion m20: 8|8@1+ (1,0) [0|0] "" X
 SG_ EPAS_infoBootloaderCRC m20: 32|32@1+ (1,0) [0|0] "" X
 SG_ EPAS_infoApplicationCRC m13: 32|32@1+ (1,0) [0|0] "" X

BO_ 880 EPAS_sysStatus: 8 EPAS
 SG_ EPAS_handsOnLevel : 39|2@0+ (1,0) [0|3] "" NEO
 SG_ EPAS_torsionBarTorque : 19|12@0+ (0.01,-20.5) [-20.5|20.45] "Nm" NEO

BO_ 1848 EPAS_udsResponse: 8 ETH
 SG_ EPAS_udsResponseData: 0|54@0+ (1024,0) [0|0] "" X

BO_ 1505 EPAS_version: 7 ETH
 SG_ EPAS_versionMux M: 0|8@1+ (1,0) [0|0] "" X
 SG_ EPAS_version0 m0: 8|8@1+ (1,0) [0|0] "" X
 SG_ EPAS_version1 m0: 16|8@1+ (1,0) [0|0] "" X
 SG_ EPAS_version2 m0: 24|8@1+ (1,0) [0|0] "" X
 SG_ EPAS_version3 m0: 32|8@1+ (1,0) [0|0] "" X
 SG_ EPAS_version4 m0: 40|8@1+ (1,0) [0|0] "" X
 SG_ EPAS_version5 m0: 48|8@1+ (1,0) [0|0] "" X
 SG_ EPAS_version6 m1: 8|8@1+ (1,0) [0|0] "" X
 SG_ EPAS_version7 m1: 16|8@1+ (1,0) [0|0] "" X
 SG_ EPAS_version8 m1: 24|8@1+ (1,0) [0|0] "" X
 SG_ EPAS_version9 m1: 32|8@1+ (1,0) [0|0] "" X
 SG_ EPAS_version10 m1: 40|8@1+ (1,0) [0|0] "" X
 SG_ EPAS_version11 m1: 48|8@1+ (1,0) [0|0] "" X

BO_ 775 EPBM_alertMatrix0: 8 ETH
 SG_ EPBM_f001_leftEncIntrpt: 0|1@1+ (1,0) [0|0] "" X
 SG_ EPBM_f002_leftIdleOc: 1|1@1+ (1,0) [0|0] "" X
 SG_ EPBM_f003_leftEncIrrational: 2|1@1+ (1,0) [0|0] "" X
 SG_ EPBM_f004_leftEncoderSna: 3|1@1+ (1,0) [0|0] "" X
 SG_ EPBM_f005_leftOc: 4|1@1+ (1,0) [0|0] "" X
 SG_ EPBM_f006_leftUc: 5|1@1+ (1,0) [0|0] "" X
 SG_ EPBM_f007_leftEndStop: 6|1@1+ (1,0) [0|0] "" X
 SG_ EPBM_f008_leftShortApply: 7|1@1+ (1,0) [0|0] "" X
 SG_ EPBM_f009_leftNShort: 8|1@1+ (1,0) [0|0] "" X
 SG_ EPBM_f010_leftPShort: 9|1@1+ (1,0) [0|0] "" X
 SG_ EPBM_f011_leftNOpen: 10|1@1+ (1,0) [0|0] "" X
 SG_ EPBM_f012_leftPOpen: 11|1@1+ (1,0) [0|0] "" X
 SG_ EPBM_f013_leftEnaStuckHigh: 12|1@1+ (1,0) [0|0] "" X
 SG_ EPBM_f014_leftEnaStuckLow: 13|1@1+ (1,0) [0|0] "" X
 SG_ EPBM_f015_leftDriveDuration: 14|1@1+ (1,0) [0|0] "" X
 SG_ EPBM_f016_leftPHalfBridge: 15|1@1+ (1,0) [0|0] "" X
 SG_ EPBM_f017_leftNHalfBridge: 16|1@1+ (1,0) [0|0] "" X
 SG_ EPBM_f018_leftNvOv: 17|1@1+ (1,0) [0|0] "" X
 SG_ EPBM_f019_leftNvUv: 18|1@1+ (1,0) [0|0] "" X
 SG_ EPBM_f020_leftPvOv: 19|1@1+ (1,0) [0|0] "" X
 SG_ EPBM_f021_leftPvUv: 20|1@1+ (1,0) [0|0] "" X
 SG_ EPBM_f022_leftSubstateErr: 21|1@1+ (1,0) [0|0] "" X
 SG_ EPBM_f023_leftOverApply: 22|1@1+ (1,0) [0|0] "" X
 SG_ EPBM_f024_leftUnderApply: 23|1@1+ (1,0) [0|0] "" X
 SG_ EPBM_f025_leftOverRelease: 24|1@1+ (1,0) [0|0] "" X
 SG_ EPBM_f026_leftUnderRelease: 25|1@1+ (1,0) [0|0] "" X
 SG_ EPBM_f027_spuriousEncIntL: 26|1@1+ (1,0) [0|0] "" X
 SG_ EPBM_f028_noCurrentCalL: 27|1@1+ (1,0) [0|0] "" X
 SG_ EPBM_f029_canDisabled: 28|1@1+ (1,0) [0|0] "" X
 SG_ EPBM_f030_interProcSpi: 29|1@1+ (1,0) [0|0] "" X
 SG_ EPBM_f031_stateErr: 30|1@1+ (1,0) [0|0] "" X
 SG_ EPBM_f032_reqStateErr: 31|1@1+ (1,0) [0|0] "" X
 SG_ EPBM_f033_canHardware: 32|1@1+ (1,0) [0|0] "" X
 SG_ EPBM_f034_canData: 33|1@1+ (1,0) [0|0] "" X
 SG_ EPBM_f035_canErr: 34|1@1+ (1,0) [0|0] "" X
 SG_ EPBM_f036_canOverrun: 35|1@1+ (1,0) [0|0] "" X
 SG_ EPBM_f037_firmware: 36|1@1+ (1,0) [0|0] "" X
 SG_ EPBM_f038_eeprom: 37|1@1+ (1,0) [0|0] "" X
 SG_ EPBM_f039_watchdogReset: 38|1@1+ (1,0) [0|0] "" X
 SG_ EPBM_f040_memoryError: 39|1@1+ (1,0) [0|0] "" X
 SG_ EPBM_f041_spiOpen: 40|1@1+ (1,0) [0|0] "" X
 SG_ EPBM_f042_spiRead: 41|1@1+ (1,0) [0|0] "" X
 SG_ EPBM_f043_absMIA: 42|1@1+ (1,0) [0|0] "" X
 SG_ EPBM_f044_diMIA: 43|1@1+ (1,0) [0|0] "" X
 SG_ EPBM_f045_gtwMIA: 44|1@1+ (1,0) [0|0] "" X
 SG_ EPBM_f046_sccmMIA: 45|1@1+ (1,0) [0|0] "" X
 SG_ EPBM_f047_epbMIA: 46|1@1+ (1,0) [0|0] "" X
 SG_ EPBM_f048_chgMIA: 47|1@1+ (1,0) [0|0] "" X
 SG_ EPBM_f049_espMIA: 48|1@1+ (1,0) [0|0] "" X
 SG_ EPBM_f050_mcuMIA: 49|1@1+ (1,0) [0|0] "" X
 SG_ EPBM_f051_leftNVoltageLow: 50|1@1+ (1,0) [0|0] "" X
 SG_ EPBM_f052_leftPVoltageHigh: 51|1@1+ (1,0) [0|0] "" X
 SG_ EPBM_f053_unused: 52|1@1+ (1,0) [0|0] "" X
 SG_ EPBM_f054_unused: 53|1@1+ (1,0) [0|0] "" X
 SG_ EPBM_f055_stackOverflow: 54|1@1+ (1,0) [0|0] "" X
 SG_ EPBM_f056_12vOv: 55|1@1+ (1,0) [0|0] "" X
 SG_ EPBM_f057_12vUv: 56|1@1+ (1,0) [0|0] "" X
 SG_ EPBM_f058_5vLost: 57|1@1+ (1,0) [0|0] "" X
 SG_ EPBM_f059_battMismatch: 58|1@1+ (1,0) [0|0] "" X
 SG_ EPBM_f060_maxCycles1: 59|1@1+ (1,0) [0|0] "" X
 SG_ EPBM_f061_maxCycles2: 60|1@1+ (1,0) [0|0] "" X
 SG_ EPBM_f062_diGearInvld: 61|1@1+ (1,0) [0|0] "" X
 SG_ EPBM_f063_unused: 62|1@1+ (1,0) [0|0] "" X
 SG_ EPBM_f064_unused: 63|1@1+ (1,0) [0|0] "" X

BA_DEF_ BO_ "GenMsgSendType" ENUM "Cyclic";
BA_DEF_ BO_ "GenMsgCycleTime" INT 0 60000;

BA_ "GenMsgSendType" BO_ 585 0;
BA_ "GenMsgCycleTime" BO_ 585 100;

BA_ "GenMsgSendType" BO_ 809 0;
BA_ "GenMsgCycleTime" BO_ 809 1000;

BA_ "GenMsgSendType" BO_ 873 0;
BA_ "GenMsgCycleTime" BO_ 873 1000;

BA_ "GenMsgSendType" BO_ 841 0;
BA_ "GenMsgCycleTime" BO_ 841 1000;

BA_ "GenMsgSendType" BO_ 2020 0;
BA_ "GenMsgCycleTime" BO_ 2020 60000;

BA_ "GenMsgSendType" BO_ 1016 0;
BA_ "GenMsgCycleTime" BO_ 1016 1000;

BA_ "GenMsgSendType" BO_ 1616 0;
BA_ "GenMsgCycleTime" BO_ 1616 1000;

BA_ "GenMsgSendType" BO_ 528 0;
BA_ "GenMsgCycleTime" BO_ 528 100;

BA_ "GenMsgSendType" BO_ 100 0;
BA_ "GenMsgCycleTime" BO_ 100 100;

BA_ "GenMsgSendType" BO_ 1290 0;
BA_ "GenMsgCycleTime" BO_ 1290 500;

BA_ "GenMsgSendType" BO_ 1306 0;
BA_ "GenMsgCycleTime" BO_ 1306 1000;

BA_ "GenMsgSendType" BO_ 934 0;
BA_ "GenMsgCycleTime" BO_ 934 1000;

BA_ "GenMsgSendType" BO_ 950 0;
BA_ "GenMsgCycleTime" BO_ 950 1000;

BA_ "GenMsgSendType" BO_ 966 0;
BA_ "GenMsgCycleTime" BO_ 966 1000;

BA_ "GenMsgSendType" BO_ 982 0;
BA_ "GenMsgCycleTime" BO_ 982 1000;

BA_ "GenMsgSendType" BO_ 998 0;
BA_ "GenMsgCycleTime" BO_ 998 1000;

BA_ "GenMsgSendType" BO_ 74 0;
BA_ "GenMsgCycleTime" BO_ 74 1000;

BA_ "GenMsgSendType" BO_ 75 0;
BA_ "GenMsgCycleTime" BO_ 75 1000;

BA_ "GenMsgSendType" BO_ 1654 0;
BA_ "GenMsgCycleTime" BO_ 1654 1000;

BA_ "GenMsgSendType" BO_ 741 0;
BA_ "GenMsgCycleTime" BO_ 741 100;

BA_ "GenMsgSendType" BO_ 277 0;
BA_ "GenMsgCycleTime" BO_ 277 100;

BA_ "GenMsgSendType" BO_ 41 0;
BA_ "GenMsgCycleTime" BO_ 41 1000;

BA_ "GenMsgSendType" BO_ 42 0;
BA_ "GenMsgCycleTime" BO_ 42 1000;

BA_ "GenMsgSendType" BO_ 43 0;
BA_ "GenMsgCycleTime" BO_ 43 1000;

BA_ "GenMsgSendType" BO_ 44 0;
BA_ "GenMsgCycleTime" BO_ 44 1000;

BA_ "GenMsgSendType" BO_ 63 0;
BA_ "GenMsgCycleTime" BO_ 63 1000;

BA_ "GenMsgSendType" BO_ 72 0;
BA_ "GenMsgCycleTime" BO_ 72 1000;

BA_ "GenMsgSendType" BO_ 73 0;
BA_ "GenMsgCycleTime" BO_ 73 1000;

BA_ "GenMsgSendType" BO_ 82 0;
BA_ "GenMsgCycleTime" BO_ 82 1000;

BA_ "GenMsgSendType" BO_ 1622 0;
BA_ "GenMsgCycleTime" BO_ 1622 1000;

BA_ "GenMsgSendType" BO_ 1270 0;
BA_ "GenMsgCycleTime" BO_ 1270 100;

BA_ "GenMsgSendType" BO_ 294 0;
BA_ "GenMsgCycleTime" BO_ 294 100;

BA_ "GenMsgSendType" BO_ 614 0;
BA_ "GenMsgCycleTime" BO_ 614 100;

BA_ "GenMsgSendType" BO_ 598 0;
BA_ "GenMsgCycleTime" BO_ 598 100;

BA_ "GenMsgSendType" BO_ 648 0;
BA_ "GenMsgCycleTime" BO_ 648 100;

BA_ "GenMsgSendType" BO_ 774 0;
BA_ "GenMsgCycleTime" BO_ 774 1000;

BA_ "GenMsgSendType" BO_ 262 0;
BA_ "GenMsgCycleTime" BO_ 262 1000;

BA_ "GenMsgSendType" BO_ 4 0;
BA_ "GenMsgCycleTime" BO_ 4 100;

BA_ "GenMsgSendType" BO_ 264 0;
BA_ "GenMsgCycleTime" BO_ 264 1000;

BA_ "GenMsgSendType" BO_ 1286 0;
BA_ "GenMsgCycleTime" BO_ 1286 1000;

BA_ "GenMsgSendType" BO_ 92 0;
BA_ "GenMsgCycleTime" BO_ 92 1000;

BA_ "GenMsgSendType" BO_ 560 0;
BA_ "GenMsgCycleTime" BO_ 560 100;

BA_ "GenMsgSendType" BO_ 912 0;
BA_ "GenMsgCycleTime" BO_ 912 1000;

BA_ "GenMsgSendType" BO_ 914 0;
BA_ "GenMsgCycleTime" BO_ 914 1000;

BA_ "GenMsgSendType" BO_ 913 0;
BA_ "GenMsgCycleTime" BO_ 913 1000;

BA_ "GenMsgSendType" BO_ 90 0;
BA_ "GenMsgCycleTime" BO_ 90 1000;

BA_ "GenMsgSendType" BO_ 896 0;
BA_ "GenMsgCycleTime" BO_ 896 1000;

BA_ "GenMsgSendType" BO_ 1328 0;
BA_ "GenMsgCycleTime" BO_ 1328 10000;

BA_ "GenMsgSendType" BO_ 880 0;
BA_ "GenMsgCycleTime" BO_ 880 1000;

BA_ "GenMsgSendType" BO_ 1505 0;
BA_ "GenMsgCycleTime" BO_ 1505 10000;

BA_ "GenMsgSendType" BO_ 775 0;
BA_ "GenMsgCycleTime" BO_ 775 1000;

VAL_ 1545 DAS_TR_Obj00_Class 0 "UNKNOWN" 1 "MOVING_FOUR_WHEEL_VEHICLE" 2 "MOVING_TWO_WHEEL_VEHICLE" 3 "MOVING_PEDESTRIAN" 4 "CONSTRUCTION_ELEMENT";
VAL_ 1545 DAS_TR_Obj00_MovingState 0 "INDETERMINATE" 1 "MOVING" 2 "STOPPED" 3 "STANDING";
VAL_ 1545 DAS_TR_Obj01_Class 0 "UNKNOWN" 1 "MOVING_FOUR_WHEEL_VEHICLE" 2 "MOVING_TWO_WHEEL_VEHICLE" 3 "MOVING_PEDESTRIAN" 4 "CONSTRUCTION_ELEMENT";
VAL_ 1545 DAS_TR_Obj01_MovingState 0 "INDETERMINATE" 1 "MOVING" 2 "STOPPED" 3 "STANDING";
VAL_ 1545 DAS_TR_Obj02_Class 0 "UNKNOWN" 1 "MOVING_FOUR_WHEEL_VEHICLE" 2 "MOVING_TWO_WHEEL_VEHICLE" 3 "MOVING_PEDESTRIAN" 4 "CONSTRUCTION_ELEMENT";
VAL_ 1545 DAS_TR_Obj02_MovingState 0 "INDETERMINATE" 1 "MOVING" 2 "STOPPED" 3 "STANDING";
VAL_ 1545 DAS_TR_Obj03_Class 0 "UNKNOWN" 1 "MOVING_FOUR_WHEEL_VEHICLE" 2 "MOVING_TWO_WHEEL_VEHICLE" 3 "MOVING_PEDESTRIAN" 4 "CONSTRUCTION_ELEMENT";
VAL_ 1545 DAS_TR_Obj03_MovingState 0 "INDETERMINATE" 1 "MOVING" 2 "STOPPED" 3 "STANDING";
VAL_ 1545 DAS_TR_Obj04_Class 0 "UNKNOWN" 1 "MOVING_FOUR_WHEEL_VEHICLE" 2 "MOVING_TWO_WHEEL_VEHICLE" 3 "MOVING_PEDESTRIAN" 4 "CONSTRUCTION_ELEMENT";
VAL_ 1545 DAS_TR_Obj04_MovingState 0 "INDETERMINATE" 1 "MOVING" 2 "STOPPED" 3 "STANDING";
VAL_ 1545 DAS_TR_Obj05_Class 0 "UNKNOWN" 1 "MOVING_FOUR_WHEEL_VEHICLE" 2 "MOVING_TWO_WHEEL_VEHICLE" 3 "MOVING_PEDESTRIAN" 4 "CONSTRUCTION_ELEMENT";
VAL_ 1545 DAS_TR_Obj05_MovingState 0 "INDETERMINATE" 1 "MOVING" 2 "STOPPED" 3 "STANDING";
VAL_ 1545 DAS_TR_Obj06_Class 0 "UNKNOWN" 1 "MOVING_FOUR_WHEEL_VEHICLE" 2 "MOVING_TWO_WHEEL_VEHICLE" 3 "MOVING_PEDESTRIAN" 4 "CONSTRUCTION_ELEMENT";
VAL_ 1545 DAS_TR_Obj06_MovingState 0 "INDETERMINATE" 1 "MOVING" 2 "STOPPED" 3 "STANDING";
VAL_ 1545 DAS_TR_Obj07_Class 0 "UNKNOWN" 1 "MOVING_FOUR_WHEEL_VEHICLE" 2 "MOVING_TWO_WHEEL_VEHICLE" 3 "MOVING_PEDESTRIAN" 4 "CONSTRUCTION_ELEMENT";
VAL_ 1545 DAS_TR_Obj07_MovingState 0 "INDETERMINATE" 1 "MOVING" 2 "STOPPED" 3 "STANDING";
VAL_ 1545 DAS_TR_Obj08_Class 0 "UNKNOWN" 1 "MOVING_FOUR_WHEEL_VEHICLE" 2 "MOVING_TWO_WHEEL_VEHICLE" 3 "MOVING_PEDESTRIAN" 4 "CONSTRUCTION_ELEMENT";
VAL_ 1545 DAS_TR_Obj08_MovingState 0 "INDETERMINATE" 1 "MOVING" 2 "STOPPED" 3 "STANDING";
VAL_ 1545 DAS_TR_Obj09_Class 0 "UNKNOWN" 1 "MOVING_FOUR_WHEEL_VEHICLE" 2 "MOVING_TWO_WHEEL_VEHICLE" 3 "MOVING_PEDESTRIAN" 4 "CONSTRUCTION_ELEMENT";
VAL_ 1545 DAS_TR_Obj09_MovingState 0 "INDETERMINATE" 1 "MOVING" 2 "STOPPED" 3 "STANDING";
VAL_ 1545 DAS_TR_Obj10_Class 0 "UNKNOWN" 1 "MOVING_FOUR_WHEEL_VEHICLE" 2 "MOVING_TWO_WHEEL_VEHICLE" 3 "MOVING_PEDESTRIAN" 4 "CONSTRUCTION_ELEMENT";
VAL_ 1545 DAS_TR_Obj10_MovingState 0 "INDETERMINATE" 1 "MOVING" 2 "STOPPED" 3 "STANDING";
VAL_ 1545 DAS_TR_Obj11_Class 0 "UNKNOWN" 1 "MOVING_FOUR_WHEEL_VEHICLE" 2 "MOVING_TWO_WHEEL_VEHICLE" 3 "MOVING_PEDESTRIAN" 4 "CONSTRUCTION_ELEMENT";
VAL_ 1545 DAS_TR_Obj11_MovingState 0 "INDETERMINATE" 1 "MOVING" 2 "STOPPED" 3 "STANDING";
VAL_ 1545 DAS_TR_Obj12_Class 0 "UNKNOWN" 1 "MOVING_FOUR_WHEEL_VEHICLE" 2 "MOVING_TWO_WHEEL_VEHICLE" 3 "MOVING_PEDESTRIAN" 4 "CONSTRUCTION_ELEMENT";
VAL_ 1545 DAS_TR_Obj12_MovingState 0 "INDETERMINATE" 1 "MOVING" 2 "STOPPED" 3 "STANDING";
VAL_ 1545 DAS_TR_Obj13_Class 0 "UNKNOWN" 1 "MOVING_FOUR_WHEEL_VEHICLE" 2 "MOVING_TWO_WHEEL_VEHICLE" 3 "MOVING_PEDESTRIAN" 4 "CONSTRUCTION_ELEMENT";
VAL_ 1545 DAS_TR_Obj13_MovingState 0 "INDETERMINATE" 1 "MOVING" 2 "STOPPED" 3 "STANDING";
VAL_ 1545 DAS_TR_Obj14_Class 0 "UNKNOWN" 1 "MOVING_FOUR_WHEEL_VEHICLE" 2 "MOVING_TWO_WHEEL_VEHICLE" 3 "MOVING_PEDESTRIAN" 4 "CONSTRUCTION_ELEMENT";
VAL_ 1545 DAS_TR_Obj14_MovingState 0 "INDETERMINATE" 1 "MOVING" 2 "STOPPED" 3 "STANDING";
VAL_ 1545 DAS_TR_Obj15_Class 0 "UNKNOWN" 1 "MOVING_FOUR_WHEEL_VEHICLE" 2 "MOVING_TWO_WHEEL_VEHICLE" 3 "MOVING_PEDESTRIAN" 4 "CONSTRUCTION_ELEMENT";
VAL_ 1545 DAS_TR_Obj15_MovingState 0 "INDETERMINATE" 1 "MOVING" 2 "STOPPED" 3 "STANDING";
VAL_ 1545 DAS_TR_Obj16_Class 0 "UNKNOWN" 1 "MOVING_FOUR_WHEEL_VEHICLE" 2 "MOVING_TWO_WHEEL_VEHICLE" 3 "MOVING_PEDESTRIAN" 4 "CONSTRUCTION_ELEMENT";
VAL_ 1545 DAS_TR_Obj16_MovingState 0 "INDETERMINATE" 1 "MOVING" 2 "STOPPED" 3 "STANDING";
VAL_ 1545 DAS_TR_Obj17_Class 0 "UNKNOWN" 1 "MOVING_FOUR_WHEEL_VEHICLE" 2 "MOVING_TWO_WHEEL_VEHICLE" 3 "MOVING_PEDESTRIAN" 4 "CONSTRUCTION_ELEMENT";
VAL_ 1545 DAS_TR_Obj17_MovingState 0 "INDETERMINATE" 1 "MOVING" 2 "STOPPED" 3 "STANDING";
VAL_ 1545 DAS_TR_Obj18_Class 0 "UNKNOWN" 1 "MOVING_FOUR_WHEEL_VEHICLE" 2 "MOVING_TWO_WHEEL_VEHICLE" 3 "MOVING_PEDESTRIAN" 4 "CONSTRUCTION_ELEMENT";
VAL_ 1545 DAS_TR_Obj18_MovingState 0 "INDETERMINATE" 1 "MOVING" 2 "STOPPED" 3 "STANDING";
VAL_ 1545 DAS_TR_Obj19_Class 0 "UNKNOWN" 1 "MOVING_FOUR_WHEEL_VEHICLE" 2 "MOVING_TWO_WHEEL_VEHICLE" 3 "MOVING_PEDESTRIAN" 4 "CONSTRUCTION_ELEMENT";
VAL_ 1545 DAS_TR_Obj19_MovingState 0 "INDETERMINATE" 1 "MOVING" 2 "STOPPED" 3 "STANDING";
VAL_ 1545 DAS_TR_Obj20_Class 0 "UNKNOWN" 1 "MOVING_FOUR_WHEEL_VEHICLE" 2 "MOVING_TWO_WHEEL_VEHICLE" 3 "MOVING_PEDESTRIAN" 4 "CONSTRUCTION_ELEMENT";
VAL_ 1545 DAS_TR_Obj20_MovingState 0 "INDETERMINATE" 1 "MOVING" 2 "STOPPED" 3 "STANDING";
VAL_ 1545 DAS_TR_Obj21_Class 0 "UNKNOWN" 1 "MOVING_FOUR_WHEEL_VEHICLE" 2 "MOVING_TWO_WHEEL_VEHICLE" 3 "MOVING_PEDESTRIAN" 4 "CONSTRUCTION_ELEMENT";
VAL_ 1545 DAS_TR_Obj21_MovingState 0 "INDETERMINATE" 1 "MOVING" 2 "STOPPED" 3 "STANDING";
VAL_ 1545 DAS_TR_Obj22_Class 0 "UNKNOWN" 1 "MOVING_FOUR_WHEEL_VEHICLE" 2 "MOVING_TWO_WHEEL_VEHICLE" 3 "MOVING_PEDESTRIAN" 4 "CONSTRUCTION_ELEMENT";
VAL_ 1545 DAS_TR_Obj22_MovingState 0 "INDETERMINATE" 1 "MOVING" 2 "STOPPED" 3 "STANDING";
VAL_ 1545 DAS_TR_Obj23_Class 0 "UNKNOWN" 1 "MOVING_FOUR_WHEEL_VEHICLE" 2 "MOVING_TWO_WHEEL_VEHICLE" 3 "MOVING_PEDESTRIAN" 4 "CONSTRUCTION_ELEMENT";
VAL_ 1545 DAS_TR_Obj23_MovingState 0 "INDETERMINATE" 1 "MOVING" 2 "STOPPED" 3 "STANDING";
VAL_ 1545 DAS_TR_Obj24_Class 0 "UNKNOWN" 1 "MOVING_FOUR_WHEEL_VEHICLE" 2 "MOVING_TWO_WHEEL_VEHICLE" 3 "MOVING_PEDESTRIAN" 4 "CONSTRUCTION_ELEMENT";
VAL_ 1545 DAS_TR_Obj24_MovingState 0 "INDETERMINATE" 1 "MOVING" 2 "STOPPED" 3 "STANDING";
VAL_ 1545 DAS_TR_Obj25_Class 0 "UNKNOWN" 1 "MOVING_FOUR_WHEEL_VEHICLE" 2 "MOVING_TWO_WHEEL_VEHICLE" 3 "MOVING_PEDESTRIAN" 4 "CONSTRUCTION_ELEMENT";
VAL_ 1545 DAS_TR_Obj25_MovingState 0 "INDETERMINATE" 1 "MOVING" 2 "STOPPED" 3 "STANDING";
VAL_ 1545 DAS_TR_Obj26_Class 0 "UNKNOWN" 1 "MOVING_FOUR_WHEEL_VEHICLE" 2 "MOVING_TWO_WHEEL_VEHICLE" 3 "MOVING_PEDESTRIAN" 4 "CONSTRUCTION_ELEMENT";
VAL_ 1545 DAS_TR_Obj26_MovingState 0 "INDETERMINATE" 1 "MOVING" 2 "STOPPED" 3 "STANDING";
VAL_ 1545 DAS_TR_Obj27_Class 0 "UNKNOWN" 1 "MOVING_FOUR_WHEEL_VEHICLE" 2 "MOVING_TWO_WHEEL_VEHICLE" 3 "MOVING_PEDESTRIAN" 4 "CONSTRUCTION_ELEMENT";
VAL_ 1545 DAS_TR_Obj27_MovingState 0 "INDETERMINATE" 1 "MOVING" 2 "STOPPED" 3 "STANDING";
VAL_ 1545 DAS_TR_Obj28_Class 0 "UNKNOWN" 1 "MOVING_FOUR_WHEEL_VEHICLE" 2 "MOVING_TWO_WHEEL_VEHICLE" 3 "MOVING_PEDESTRIAN" 4 "CONSTRUCTION_ELEMENT";
VAL_ 1545 DAS_TR_Obj28_MovingState 0 "INDETERMINATE" 1 "MOVING" 2 "STOPPED" 3 "STANDING";
VAL_ 1545 DAS_TR_Obj29_Class 0 "UNKNOWN" 1 "MOVING_FOUR_WHEEL_VEHICLE" 2 "MOVING_TWO_WHEEL_VEHICLE" 3 "MOVING_PEDESTRIAN" 4 "CONSTRUCTION_ELEMENT";
VAL_ 1545 DAS_TR_Obj29_MovingState 0 "INDETERMINATE" 1 "MOVING" 2 "STOPPED" 3 "STANDING";
VAL_ 1545 DAS_TR_Obj30_Class 0 "UNKNOWN" 1 "MOVING_FOUR_WHEEL_VEHICLE" 2 "MOVING_TWO_WHEEL_VEHICLE" 3 "MOVING_PEDESTRIAN" 4 "CONSTRUCTION_ELEMENT";
VAL_ 1545 DAS_TR_Obj30_MovingState 0 "INDETERMINATE" 1 "MOVING" 2 "STOPPED" 3 "STANDING";
VAL_ 1545 DAS_TR_Obj31_Class 0 "UNKNOWN" 1 "MOVING_FOUR_WHEEL_VEHICLE" 2 "MOVING_TWO_WHEEL_VEHICLE" 3 "MOVING_PEDESTRIAN" 4 "CONSTRUCTION_ELEMENT";
VAL_ 1545 DAS_TR_Obj31_MovingState 0 "INDETERMINATE" 1 "MOVING" 2 "STOPPED" 3 "STANDING";

VAL_ 585 DAS_accSmartSpeedState 0 "NOT_ACTIVE" 1 "ACTIVE_OFFRAMP" 2 "ACTIVE_INTEGRATING" 3 "ACTIVE_ONRAMP" 4 "SET_SPEED_SET_REQUESTED" 5 "OFFRAMP_DELAY" 7 "SNA";
VAL_ 585 DAS_autosteerBottsDotsUsage 0 "REJECTED_UNAVAILABLE" 1 "AVAILABLE" 2 "FUSED" 3 "BLACKLISTED";
VAL_ 585 DAS_autosteerHPPUsage 0 "REJECTED_UNAVAILABLE" 1 "AVAILABLE" 2 "FUSED" 3 "BLACKLISTED";
VAL_ 585 DAS_autosteerHealthState 0 "UNAVAILABLE" 1 "NOMINAL" 2 "DEGRADED" 3 "SEVERELY_DEGRADED" 4 "ABORTING" 5 "FAULT";
VAL_ 585 DAS_autosteerModelUsage 0 "REJECTED_UNAVAILABLE" 1 "AVAILABLE" 2 "FUSED" 3 "BLACKLISTED";
VAL_ 585 DAS_autosteerNavigationUsage 0 "REJECTED_UNAVAILABLE" 1 "AVAILABLE" 2 "FUSED" 3 "BLACKLISTED";
VAL_ 585 DAS_autosteerVehiclesUsage 0 "REJECTED_UNAVAILABLE" 1 "AVAILABLE" 2 "FUSED" 3 "BLACKLISTED";
VAL_ 585 DAS_behaviorType 0 "INVALID" 1 "IN_LANE" 2 "LANE_CHANGE_LEFT" 3 "LANE_CHANGE_RIGHT";
VAL_ 585 DAS_lastAutosteerAbortReason 0 "HM_LANE_VIEW_RANGE" 1 "HM_VIRTUAL_LANE_NO_INPUTS" 2 "HM_STEERING_ERROR" 14 "APP_ME_STATE_NOT_VISION" 15 "ME_MAIN_STATE_NOT_VISION" 16 "CAM_MSG_MIA" 17 "CAM_WATCHDOG" 18 "TRAILER_MODE" 19 "SIDE_COLLISION_IMMINENT" 20 "EPAS_EAC_DENIED" 21 "COMPONENT_MIA" 22 "CRUISE_FAULT" 23 "CID_SWITCH_DISABLED" 24 "DRIVING_OFF_NAV" 25 "VEHICLE_SPEED_ABOVE_MAX" 26 "FOLLOWER_OUTPUT_INVALID" 27 "PLANNER_OUTPUT_INVALID" 28 "EPAS_ERROR_CODE" 29 "ACC_CANCEL" 30 "CAMERA_FAILSAFES" 31 "NO_ABORT" 32 "AEB";
VAL_ 585 DAS_lastLinePreferenceReason 0 "OTHER_LANE_DISAGREES_WITH_MODEL" 1 "AGREEMENT_WITH_NEIGHBOR_LANES" 2 "NEIGHBOR_LANE_PROBABILIY" 3 "NAVIGATION_BRANCH" 4 "AVOID_ONCOMING_LANES" 5 "COUNTRY_DRIVING_SIDE" 15 "NONE";
VAL_ 585 DAS_navAvailable 0 "UNAVAILABLE" 1 "AVAILABLE";
VAL_ 585 DAS_offsetSide 0 "NO_OFFSET" 1 "OFFSET_RIGHT_OBJECT" 2 "OFFSET_LEFT_OBJECT" 3 "OFFSET_BOTH_OBJECTS";
VAL_ 585 DAS_plannerState 0 "DISABLED" 1 "VL" 2 "FOLLOW" 3 "LANECHANGE_REQUESTED" 4 "LANECHANGE_IN_PROGRESS" 5 "LANECHANGE_WAIT_FOR_SIDE_OBSTACLE" 6 "LANECHANGE_WAIT_FOR_FWD_OBSTACLE" 7 "LANECHANGE_ABORT";
VAL_ 585 DAS_rearVehDetectedThisCycle 0 "NOT_DETECTED" 1 "DETECTED";
VAL_ 585 DAS_roadSurfaceType 0 "SNA" 1 "NORMAL" 2 "ENHANCED";
VAL_ 585 DAS_ulcInProgress 0 "INACTIVE" 1 "ACTIVE";
VAL_ 585 DAS_ulcType 0 "NONE" 1 "NAV" 2 "SPEED";

VAL_ 57 THC_DBGKey 0 "NONE" 1 "DIAG_ENG_MODE" 2 "DIAG_SEN_MODE" 3 "DIAG_ACT_MODE" 5 "RESET";

VAL_ 528 DCDC_outputCurrent 255 "SNA";
VAL_ 528 DCDC_outputVoltage 255 "SNA";

VAL_ 1280 DCDC_componentBranchOrigin 255 "SNA";
VAL_ 1280 DCDC_componentHardwareRevision 255 "SNA";
VAL_ 1280 DCDC_componentMajorVersion 253 "MFG_BUILD" 254 "LOCAL_BUILD" 255 "SNA";
VAL_ 1280 DCDC_componentMaturity 255 "SNA";
VAL_ 1280 DCDC_platformBranchOrigin 255 "SNA";
VAL_ 1280 DCDC_platformMajorVersion 254 "LOCAL_BUILD" 255 "SNA";
VAL_ 1280 DCDC_platformMaturity 255 "SNA";
VAL_ 1280 DCDC_platformType 255 "SNA";

VAL_ 100 DDM_driverRepeaterState 0 "Off" 1 "On" 2 "Failed" 3 "default";

VAL_ 1290 DDM_childWindowLockStatus 0 "ACTIVE" 1 "INACTIVE" 3 "SNA";
VAL_ 1290 DDM_driverFrontPresentReq 0 "UNPRESSED" 1 "PRESSED" 2 "FAULT" 3 "SNA";
VAL_ 1290 DDM_driverMirrorXRequest 0 "None" 1 "Right" 2 "Left" 3 "Default";
VAL_ 1290 DDM_driverMirrorYRequest 0 "None" 1 "Up" 2 "Down" 3 "Default";
VAL_ 1290 DDM_driverRearPresentReq 0 "UNPRESSED" 1 "PRESSED" 2 "FAULT" 3 "SNA";
VAL_ 1290 DDM_extDriverFrontRelease 0 "UNPRESSED" 1 "PRESSED" 2 "FAULT" 3 "SNA";
VAL_ 1290 DDM_extDriverRearRelease 0 "UNPRESSED" 1 "PRESSED" 2 "FAULT" 3 "SNA";
VAL_ 1290 DDM_intDriverFrontRelease 0 "UNPRESSED" 1 "PRESSED" 2 "FAULT" 3 "SNA";
VAL_ 1290 DDM_intDriverRearRelease 0 "UNPRESSED" 1 "PRESSED" 2 "FAULT" 3 "SNA";
VAL_ 1290 DDM_mirrorFoldCmd 0 "IDLE" 1 "PRESENT" 2 "RETRACT" 3 "SNA";
VAL_ 1290 DDM_passFrontWindowRequest 0 "OFF_WINDOW" 1 "AUTO_UP_WINDOW" 2 "AUTO_DOWN_WINDOW" 3 "UP_WINDOW" 4 "DOWN_WINDOW";
VAL_ 1290 DDM_passMirrorXRequest 0 "None" 1 "Right" 2 "Left" 3 "Default";
VAL_ 1290 DDM_passMirrorYRequest 0 "None" 1 "Up" 2 "Down" 3 "Default";
VAL_ 1290 DDM_passRearWindowRequest 0 "OFF_WINDOW" 1 "AUTO_UP_WINDOW" 2 "AUTO_DOWN_WINDOW" 3 "UP_WINDOW" 4 "DOWN_WINDOW";

VAL_ 554 DF_componentHardwareId 0 "DH1" 1 "DH2" 2 "DH3" 255 "SNA";
VAL_ 554 DF_mainState 0 "HND_STATE_INIT" 1 "HND_STATE_UNKNOWN" 2 "HND_STATE_RETRACTED" 3 "HND_STATE_MOVING_OUT" 4 "HND_STATE_UNUSED_4" 5 "HND_STATE_PRESENTED" 6 "HND_STATE_UNUSED_6" 7 "HND_STATE_MOVING_IN" 8 "HND_STATE_PUSHED" 9 "HND_STATE_PULLED" 10 "HND_STATE_FAULT" 11 "HND_STATE_STOPPED" 12 "HND_STATE_PRESENT_FAIL" 13 "HND_STATE_RETRACT_FAIL" 14 "HND_STATE_GOTOSLEEP" 15 "HND_STATE_SAVECONFIG" 16 "HND_STATE_MFG" 17 "INIT" 18 "RUN" 19 "SLEEP" 20 "RESET" 21 "MFG" 22 "FAULT" 23 "INVALID";
VAL_ 554 DF_motorState 0 "HND_MOTOR_IDLE" 1 "HND_MOTOR_FWD" 2 "HND_MOTOR_REVERSE" 3 "HND_MOTOR_ENDSTOP" 4 "HND_MOTOR_OVERCURRENT" 5 "HND_MOTOR_TIMEOUT" 6 "HND_MOTOR_ERROR" 17 "UNKNOWN" 18 "RETRACTED" 19 "PUSHED" 20 "PRESENTING" 21 "PRESENTED" 22 "PULLING" 23 "PULLED" 24 "CLAMPING" 25 "CLAMPED" 26 "RECLAMPING" 27 "WAIT" 28 "UNCLAMPING" 29 "REPRESENTING" 30 "RETRACTING" 31 "PREUNKNOWN" 32 "WAIT_CLAMP_RELEASE" 33 "WAIT_PUSHED_RELEASE" 34 "REPRESENTING_SOFT_CURRENT" 35 "MEASURE_ARM" 36 "MEASURE" 45 "DH3_INVALIDSUB" 46 "DH3_UNKNOWN" 47 "DH3_FINDHOME" 48 "DH3_RETRACTING" 49 "DH3_PINCHDETECT" 50 "DH3_RETRACTED" 51 "DH3_PUSHED" 52 "DH3_PRESENTING" 53 "DH3_OBSTRUCTION" 54 "DH3_PRESENTED" 55 "DH3_PULLING" 56 "DH3_PULLED" 57 "DH3_CLAMPING" 58 "DH3_CLAMPED" 59 "DH3_WAIT" 60 "DH3_UNCLAMPING" 61 "DH3_RETRACTFAIL" 62 "DH3_PRESENTFAIL" 63 "DH3_OVERDRIVE" 64 "DH3_CALRETRACT" 65 "DH3_CALPRESENT" 66 "DH3_UNCALIBRATED" 67 "DH3_RETRACTINGMORE" 68 "DH3_PUSHEDTORELEASE" 69 "DH3_UNCALIBRATED_PUSH";
VAL_ 554 DF_targetPosition 0 "UNKNOWN" 1 "RETRACTED" 2 "PRESENTED" 3 "RETRACT_FAILED" 4 "PRESENT_FAILED" 5 "MOVING_IN" 6 "MOVING_OUT" 7 "FAILURE";

VAL_ 570 DR_componentHardwareId 0 "DH1" 1 "DH2" 2 "DH3" 255 "SNA";
VAL_ 570 DR_mainState 0 "HND_STATE_INIT" 1 "HND_STATE_UNKNOWN" 2 "HND_STATE_RETRACTED" 3 "HND_STATE_MOVING_OUT" 4 "HND_STATE_UNUSED_4" 5 "HND_STATE_PRESENTED" 6 "HND_STATE_UNUSED_6" 7 "HND_STATE_MOVING_IN" 8 "HND_STATE_PUSHED" 9 "HND_STATE_PULLED" 10 "HND_STATE_FAULT" 11 "HND_STATE_STOPPED" 12 "HND_STATE_PRESENT_FAIL" 13 "HND_STATE_RETRACT_FAIL" 14 "HND_STATE_GOTOSLEEP" 15 "HND_STATE_SAVECONFIG" 16 "HND_STATE_MFG" 17 "INIT" 18 "RUN" 19 "SLEEP" 20 "RESET" 21 "MFG" 22 "FAULT" 23 "INVALID";
VAL_ 570 DR_motorState 0 "HND_MOTOR_IDLE" 1 "HND_MOTOR_FWD" 2 "HND_MOTOR_REVERSE" 3 "HND_MOTOR_ENDSTOP" 4 "HND_MOTOR_OVERCURRENT" 5 "HND_MOTOR_TIMEOUT" 6 "HND_MOTOR_ERROR" 17 "UNKNOWN" 18 "RETRACTED" 19 "PUSHED" 20 "PRESENTING" 21 "PRESENTED" 22 "PULLING" 23 "PULLED" 24 "CLAMPING" 25 "CLAMPED" 26 "RECLAMPING" 27 "WAIT" 28 "UNCLAMPING" 29 "REPRESENTING" 30 "RETRACTING" 31 "PREUNKNOWN" 32 "WAIT_CLAMP_RELEASE" 33 "WAIT_PUSHED_RELEASE" 34 "REPRESENTING_SOFT_CURRENT" 35 "MEASURE_ARM" 36 "MEASURE" 45 "DH3_INVALIDSUB" 46 "DH3_UNKNOWN" 47 "DH3_FINDHOME" 48 "DH3_RETRACTING" 49 "DH3_PINCHDETECT" 50 "DH3_RETRACTED" 51 "DH3_PUSHED" 52 "DH3_PRESENTING" 53 "DH3_OBSTRUCTION" 54 "DH3_PRESENTED" 55 "DH3_PULLING" 56 "DH3_PULLED" 57 "DH3_CLAMPING" 58 "DH3_CLAMPED" 59 "DH3_WAIT" 60 "DH3_UNCLAMPING" 61 "DH3_RETRACTFAIL" 62 "DH3_PRESENTFAIL" 63 "DH3_OVERDRIVE" 64 "DH3_CALRETRACT" 65 "DH3_CALPRESENT" 66 "DH3_UNCALIBRATED" 67 "DH3_RETRACTINGMORE" 68 "DH3_PUSHEDTORELEASE" 69 "DH3_UNCALIBRATED_PUSH";
VAL_ 570 DR_targetPosition 0 "UNKNOWN" 1 "RETRACTED" 2 "PRESENTED" 3 "RETRACT_FAILED" 4 "PRESENT_FAILED" 5 "MOVING_IN" 6 "MOVING_OUT" 7 "FAILURE";

VAL_ 1306 DDM_componentBranchOrigin 254 "LOCAL_BUILD" 255 "SNA";
VAL_ 1306 DDM_componentHardwareRevision 254 "LOCAL_BUILD" 255 "SNA";
VAL_ 1306 DDM_componentMajorVersion 254 "LOCAL_BUILD" 255 "SNA";
VAL_ 1306 DDM_componentMaturity 254 "LOCAL_BUILD" 255 "SNA";
VAL_ 1306 DDM_componentSvn 16777215 "SNA";
VAL_ 1306 DDM_platformType 254 "LOCAL_BUILD" 255 "SNA";

VAL_ 1654 DIS_infoIndex 0 "DEPRECATED_0" 1 "DEPRECATED_1" 2 "DEPRECATED_2" 3 "DEPRECATED_3" 4 "DEPRECATED_4" 5 "DEPRECATED_5" 6 "DEPRECATED_6" 7 "DEPRECATED_7" 8 "DEPRECATED_8" 9 "DEPRECATED_9" 10 "BUILD_HWID_COMPONENTID" 11 "PCBAID_ASSYID_USAGEID" 13 "APP_CRC" 14 "BOOTLOADER_SVN" 15 "BOOTLOADER_CRC" 16 "SUBCOMPONENT" 17 "APP_GITHASH" 18 "BOOTLOADER_GITHASH" 19 "VERSION_DEPRECATED" 20 "UDS_PROTOCOL_BOOTCRC" 255 "END";
VAL_ 1654 DIS_buildType 0 "UNKNOWN_BUILD" 1 "PLATFORM_BUILD" 2 "LOCAL_BUILD" 3 "TRACEABLE_CI_BUILD" 4 "MFG_BUILD";
VAL_ 1654 DIS_hardwareId 252 "CONFIGURABLE_HWID_PLACEHOLDER";
VAL_ 1654 DIS_FPGA_version 254 "LOCAL_BUILD" 255 "SNA";

VAL_ 741 DIS_aps12V 255 "SNA";
VAL_ 741 DIS_dissipation 255 "SNA";
VAL_ 741 DIS_mechPower -1024 "SNA";

VAL_ 277 DIS_motorRPM -32768 "SNA";
VAL_ 277 DIS_soptState 0 "INIT" 1 "PSTG_BRING_UP" 2 "ASC_TEST" 3 "CURRENT_TEST" 4 "TEST_PASSED" 5 "TEST_SKIPPED" 6 "TEST_FAILED" 7 "SNA";

VAL_ 82 DI_d001_replaceDriveUnit 0 "NOT_TESTED_DTC" 1 "PASSED_DTC" 2 "FAILED_DTC" 3 "UNABLE_TO_TEST_DTC";
VAL_ 82 DI_d002_12vSupplyOV 0 "NOT_TESTED_DTC" 1 "PASSED_DTC" 2 "FAILED_DTC" 3 "UNABLE_TO_TEST_DTC";
VAL_ 82 DI_d003_12vSupplyUV 0 "NOT_TESTED_DTC" 1 "PASSED_DTC" 2 "FAILED_DTC" 3 "UNABLE_TO_TEST_DTC";
VAL_ 82 DI_d004_overTemp 0 "NOT_TESTED_DTC" 1 "PASSED_DTC" 2 "FAILED_DTC" 3 "UNABLE_TO_TEST_DTC";
VAL_ 82 DI_d005_lowFlow 0 "NOT_TESTED_DTC" 1 "PASSED_DTC" 2 "FAILED_DTC" 3 "UNABLE_TO_TEST_DTC";
VAL_ 82 DI_d006_proximityLine 0 "NOT_TESTED_DTC" 1 "PASSED_DTC" 2 "FAILED_DTC" 3 "UNABLE_TO_TEST_DTC";
VAL_ 82 DI_d007_busUV 0 "NOT_TESTED_DTC" 1 "PASSED_DTC" 2 "FAILED_DTC" 3 "UNABLE_TO_TEST_DTC";
VAL_ 82 DI_d008_motorEncoder 0 "NOT_TESTED_DTC" 1 "PASSED_DTC" 2 "FAILED_DTC" 3 "UNABLE_TO_TEST_DTC";
VAL_ 82 DI_d009_brakePedal 0 "NOT_TESTED_DTC" 1 "PASSED_DTC" 2 "FAILED_DTC" 3 "UNABLE_TO_TEST_DTC";
VAL_ 82 DI_d010_accelPedal 0 "NOT_TESTED_DTC" 1 "PASSED_DTC" 2 "FAILED_DTC" 3 "UNABLE_TO_TEST_DTC";
VAL_ 82 DI_d011_unused11 0 "NOT_TESTED_DTC" 1 "PASSED_DTC" 2 "FAILED_DTC" 3 "UNABLE_TO_TEST_DTC";
VAL_ 82 DI_d012_unused12 0 "NOT_TESTED_DTC" 1 "PASSED_DTC" 2 "FAILED_DTC" 3 "UNABLE_TO_TEST_DTC";
VAL_ 82 DI_d013_unused13 0 "NOT_TESTED_DTC" 1 "PASSED_DTC" 2 "FAILED_DTC" 3 "UNABLE_TO_TEST_DTC";
VAL_ 82 DI_d014_unused14 0 "NOT_TESTED_DTC" 1 "PASSED_DTC" 2 "FAILED_DTC" 3 "UNABLE_TO_TEST_DTC";
VAL_ 82 DI_d015_unused15 0 "NOT_TESTED_DTC" 1 "PASSED_DTC" 2 "FAILED_DTC" 3 "UNABLE_TO_TEST_DTC";
VAL_ 82 DI_d016_unused16 0 "NOT_TESTED_DTC" 1 "PASSED_DTC" 2 "FAILED_DTC" 3 "UNABLE_TO_TEST_DTC";
VAL_ 82 DI_d017_unused17 0 "NOT_TESTED_DTC" 1 "PASSED_DTC" 2 "FAILED_DTC" 3 "UNABLE_TO_TEST_DTC";
VAL_ 82 DI_d018_unused18 0 "NOT_TESTED_DTC" 1 "PASSED_DTC" 2 "FAILED_DTC" 3 "UNABLE_TO_TEST_DTC";
VAL_ 82 DI_d019_unused19 0 "NOT_TESTED_DTC" 1 "PASSED_DTC" 2 "FAILED_DTC" 3 "UNABLE_TO_TEST_DTC";
VAL_ 82 DI_d020_unused20 0 "NOT_TESTED_DTC" 1 "PASSED_DTC" 2 "FAILED_DTC" 3 "UNABLE_TO_TEST_DTC";
VAL_ 82 DI_d021_unused21 0 "NOT_TESTED_DTC" 1 "PASSED_DTC" 2 "FAILED_DTC" 3 "UNABLE_TO_TEST_DTC";
VAL_ 82 DI_d022_unused22 0 "NOT_TESTED_DTC" 1 "PASSED_DTC" 2 "FAILED_DTC" 3 "UNABLE_TO_TEST_DTC";
VAL_ 82 DI_d023_unused23 0 "NOT_TESTED_DTC" 1 "PASSED_DTC" 2 "FAILED_DTC" 3 "UNABLE_TO_TEST_DTC";
VAL_ 82 DI_d024_unused24 0 "NOT_TESTED_DTC" 1 "PASSED_DTC" 2 "FAILED_DTC" 3 "UNABLE_TO_TEST_DTC";
VAL_ 82 DI_d025_unused25 0 "NOT_TESTED_DTC" 1 "PASSED_DTC" 2 "FAILED_DTC" 3 "UNABLE_TO_TEST_DTC";
VAL_ 82 DI_d026_unused26 0 "NOT_TESTED_DTC" 1 "PASSED_DTC" 2 "FAILED_DTC" 3 "UNABLE_TO_TEST_DTC";
VAL_ 82 DI_d027_unused27 0 "NOT_TESTED_DTC" 1 "PASSED_DTC" 2 "FAILED_DTC" 3 "UNABLE_TO_TEST_DTC";
VAL_ 82 DI_d028_unused28 0 "NOT_TESTED_DTC" 1 "PASSED_DTC" 2 "FAILED_DTC" 3 "UNABLE_TO_TEST_DTC";

VAL_ 1622 DI_infoIndex 0 "DEPRECATED_0" 1 "DEPRECATED_1" 2 "DEPRECATED_2" 3 "DEPRECATED_3" 4 "DEPRECATED_4" 5 "DEPRECATED_5" 6 "DEPRECATED_6" 7 "DEPRECATED_7" 8 "DEPRECATED_8" 9 "DEPRECATED_9" 10 "BUILD_HWID_COMPONENTID" 11 "PCBAID_ASSYID_USAGEID" 13 "APP_CRC" 14 "BOOTLOADER_SVN" 15 "BOOTLOADER_CRC" 16 "SUBCOMPONENT" 17 "APP_GITHASH" 18 "BOOTLOADER_GITHASH" 19 "VERSION_DEPRECATED" 20 "UDS_PROTOCOL_BOOTCRC" 255 "END";
VAL_ 1622 DI_buildType 0 "UNKNOWN_BUILD" 1 "PLATFORM_BUILD" 2 "LOCAL_BUILD" 3 "TRACEABLE_CI_BUILD" 4 "MFG_BUILD";
VAL_ 1622 DI_hardwareId 252 "CONFIGURABLE_HWID_PLACEHOLDER";
VAL_ 1622 DI_FPGA_version 254 "LOCAL_BUILD" 255 "SNA";

VAL_ 1270 DI_crsState 0 "UNAVAILABLE" 1 "STANDBY" 2 "ACTIVE" 3 "SLOWDOWN" 7 "FAULT";
VAL_ 1270 DI_locState 0 "UNAVAILABLE" 1 "STANDBY" 2 "ACTIVE" 3 "OVERRIDE" 4 "STANDSTILL" 5 "PAUSED" 6 "ABORTING" 7 "FAULT";

VAL_ 294 DI_motorCurrent 2047 "SNA";
VAL_ 294 DI_vBat 1023 "SNA";

VAL_ 614 DI_aps12V 255 "SNA";
VAL_ 614 DI_dissipation 255 "SNA";
VAL_ 614 DI_drivePowerMax 1023 "SNA";
VAL_ 614 DI_mechPower -1024 "SNA";
VAL_ 614 DI_regenPowerMax 1023 "SNA";

VAL_ 598 DI_aebState 0 "UNAVAILABLE" 1 "STANDBY" 2 "ENABLED" 3 "STANDSTILL" 4 "FAULT" 7 "SNA";
VAL_ 598 DI_analogSpeed 4095 "SNA";
VAL_ 598 DI_cruiseState 0 "UNAVAILABLE" 1 "STANDBY" 2 "ENABLED" 3 "STANDSTILL" 4 "OVERRIDE" 5 "FAULT" 6 "PRE_FAULT" 7 "PRE_CANCEL";
VAL_ 598 DI_digitalSpeed 255 "SNA";
VAL_ 598 DI_immobilizerState 0 "INIT_SNA" 1 "REQUEST" 2 "AUTHENTICATING" 3 "DISARMED" 4 "IDLE" 5 "RESET" 6 "FAULT";
VAL_ 598 DI_speedUnits 0 "MPH" 1 "KPH";
VAL_ 598 DI_state 0 "UNAVAILABLE" 1 "STANDBY" 2 "FAULT" 3 "ABORT" 4 "ENABLE";
VAL_ 598 DI_systemState 0 "UNAVAILABLE" 1 "STANDBY" 2 "FAULT" 3 "ABORT" 4 "ENABLE";
VAL_ 598 DI_vehicleHoldState 0 "UNAVAILABLE" 1 "STANDBY" 2 "BLEND_IN" 3 "STANDSTILL" 4 "BLEND_OUT" 5 "PARK" 6 "FAULT" 7 "INIT";

VAL_ 648 DI_autoparkState 0 "UNAVAILABLE" 1 "STANDBY" 2 "STARTED" 3 "ACTIVE" 4 "COMPLETE" 5 "PAUSED" 6 "ABORTED" 7 "RESUMED" 8 "UNPARK_COMPLETE" 9 "SELFPARK_STARTED" 15 "SNA";
VAL_ 648 DI_parkBrakeState 0 "UNAVAILABLE" 1 "RELEASED" 2 "REQUESTED" 3 "APPLIED" 4 "FAULTED" 5 "PANIC_EPB" 6 "PANIC_SKID" 7 "RELEASING" 15 "SNA";
VAL_ 648 DI_pmmStatus 0 "INACTIVE" 1 "ACTIVE" 3 "SNA";
VAL_ 648 DI_tractionControlMode 0 "NORMAL" 1 "SLIP_START" 2 "DEV_MODE_1" 3 "DEV_MODE_2" 4 "ROLLS_MODE" 5 "DYNO_MODE";

VAL_ 774 DI_dcCapT 255 "SNA";
VAL_ 774 DI_heatsinkT 255 "SNA";
VAL_ 774 DI_inletT 255 "SNA";
VAL_ 774 DI_inverterT 255 "SNA";
VAL_ 774 DI_inverterTpct 255 "SNA";
VAL_ 774 DI_pcbT 255 "SNA";
VAL_ 774 DI_statorT 255 "SNA";
VAL_ 774 DI_statorTpct 255 "SNA";

VAL_ 262 DI_motorRPM -32768 "SNA";
VAL_ 262 DI_pedalPos 255 "SNA";
VAL_ 262 DI_soptState 0 "INIT" 1 "PSTG_BRING_UP" 2 "ASC_TEST" 3 "CURRENT_TEST" 4 "TEST_PASSED" 5 "TEST_SKIPPED" 6 "TEST_FAILED" 7 "SNA";
VAL_ 262 DI_torqueDriver -4096 "SNA";
VAL_ 262 DI_torqueMotor -4096 "SNA";

VAL_ 4 DI_brakePedal 0 "Not_applied" 1 "Applied";
VAL_ 4 DI_brakePedalState 0 "OFF" 1 "ON" 2 "INVALID" 3 "SNA";
VAL_ 4 DI_epbInterfaceReady 0 "NOT_READY" 1 "READY";
VAL_ 4 DI_epbParkRequest 0 "No_request" 1 "Park_requested";
VAL_ 4 DI_gear 0 "INVALID" 1 "P" 2 "R" 3 "N" 4 "D" 7 "SNA";
VAL_ 4 DI_gearRequest 0 "INVALID" 1 "P" 2 "R" 3 "N" 4 "D" 7 "SNA";
VAL_ 4 DI_torqueEstimate -2048 "SNA";
VAL_ 4 DI_torqueInterfaceFailure 0 "NORMAL" 1 "FAILED";
VAL_ 4 DI_vehicleSpeed 4095 "SNA";

VAL_ 264 DI_aeroCdA 255 "SNA";
VAL_ 264 DI_gradeEst -64 "SNA";
VAL_ 264 DI_gradeEstInternal -64 "SNA";
VAL_ 264 DI_mass 1023 "SNA";
VAL_ 264 DI_massConfidence 0 "NOT_CONFIDED" 1 "CONFIDED";
VAL_ 264 DI_steerCenter -128 "SNA";
VAL_ 264 DI_tireCrr 255 "SNA";
VAL_ 264 DI_tireFitment 0 "SQUARE" 1 "STAGGERED" 3 "SNA";
VAL_ 264 DI_trailerDetected 0 "NOT_DETECTED" 1 "DETECTED";

VAL_ 1286 DI_componentBranchOrigin 254 "LOCAL_BUILD" 255 "SNA";
VAL_ 1286 DI_componentHardwareId 252 "CONFIGURABLE_HWID_PLACEHOLDER";
VAL_ 1286 DI_componentMajorVersion 253 "DYNO_BUILD" 254 "LOCAL_BUILD" 255 "SNA";
VAL_ 1286 DI_componentMaturity 254 "LOCAL_BUILD" 255 "SNA";
VAL_ 1286 DI_platformBranchOrigin 254 "LOCAL_BUILD" 255 "SNA";
VAL_ 1286 DI_platformMajorVersion 254 "LOCAL_BUILD" 255 "SNA";
VAL_ 1286 DI_platformMaturity 254 "LOCAL_BUILD" 255 "SNA";
VAL_ 1286 DI_platformType 254 "LOCAL_BUILD" 255 "SNA";

VAL_ 560 EFUSE_matrixIndex 0 "AlertMatrix0" 1 "AlertMatrix1" 2 "AlertMatrix2";

VAL_ 912 EPAS2_d001_csuFail 0 "NOT_TESTED_DTC" 1 "PASSED_DTC" 2 "FAILED_DTC" 3 "UNABLE_TO_TEST_DTC";
VAL_ 912 EPAS2_d002_csvFail 0 "NOT_TESTED_DTC" 1 "PASSED_DTC" 2 "FAILED_DTC" 3 "UNABLE_TO_TEST_DTC";
VAL_ 912 EPAS2_d003_runningReset 0 "NOT_TESTED_DTC" 1 "PASSED_DTC" 2 "FAILED_DTC" 3 "UNABLE_TO_TEST_DTC";
VAL_ 912 EPAS2_d004_gateDriverEn 0 "NOT_TESTED_DTC" 1 "PASSED_DTC" 2 "FAILED_DTC" 3 "UNABLE_TO_TEST_DTC";
VAL_ 912 EPAS2_d005_subTx 0 "NOT_TESTED_DTC" 1 "PASSED_DTC" 2 "FAILED_DTC" 3 "UNABLE_TO_TEST_DTC";
VAL_ 912 EPAS2_d006_rlyOpen 0 "NOT_TESTED_DTC" 1 "PASSED_DTC" 2 "FAILED_DTC" 3 "UNABLE_TO_TEST_DTC";
VAL_ 912 EPAS2_d007_rlyShort 0 "NOT_TESTED_DTC" 1 "PASSED_DTC" 2 "FAILED_DTC" 3 "UNABLE_TO_TEST_DTC";
VAL_ 912 EPAS2_d008_programFlow 0 "NOT_TESTED_DTC" 1 "PASSED_DTC" 2 "FAILED_DTC" 3 "UNABLE_TO_TEST_DTC";
VAL_ 912 EPAS2_d009_sentCrcError2 0 "NOT_TESTED_DTC" 1 "PASSED_DTC" 2 "FAILED_DTC" 3 "UNABLE_TO_TEST_DTC";
VAL_ 912 EPAS2_d010_sentCrcError1 0 "NOT_TESTED_DTC" 1 "PASSED_DTC" 2 "FAILED_DTC" 3 "UNABLE_TO_TEST_DTC";
VAL_ 912 EPAS2_d011_sentTimeOut2 0 "NOT_TESTED_DTC" 1 "PASSED_DTC" 2 "FAILED_DTC" 3 "UNABLE_TO_TEST_DTC";
VAL_ 912 EPAS2_d012_sentTimeOut1 0 "NOT_TESTED_DTC" 1 "PASSED_DTC" 2 "FAILED_DTC" 3 "UNABLE_TO_TEST_DTC";
VAL_ 912 EPAS2_d013_sentDiff 0 "NOT_TESTED_DTC" 1 "PASSED_DTC" 2 "FAILED_DTC" 3 "UNABLE_TO_TEST_DTC";
VAL_ 912 EPAS2_d014_sent2 0 "NOT_TESTED_DTC" 1 "PASSED_DTC" 2 "FAILED_DTC" 3 "UNABLE_TO_TEST_DTC";
VAL_ 912 EPAS2_d015_sent1 0 "NOT_TESTED_DTC" 1 "PASSED_DTC" 2 "FAILED_DTC" 3 "UNABLE_TO_TEST_DTC";
VAL_ 912 EPAS2_d016_sentSyncTime2 0 "NOT_TESTED_DTC" 1 "PASSED_DTC" 2 "FAILED_DTC" 3 "UNABLE_TO_TEST_DTC";
VAL_ 912 EPAS2_d017_sentSyncTime1 0 "NOT_TESTED_DTC" 1 "PASSED_DTC" 2 "FAILED_DTC" 3 "UNABLE_TO_TEST_DTC";
VAL_ 912 EPAS2_d018_compatibleId 0 "NOT_TESTED_DTC" 1 "PASSED_DTC" 2 "FAILED_DTC" 3 "UNABLE_TO_TEST_DTC";
VAL_ 912 EPAS2_d019_mainInterlock 0 "NOT_TESTED_DTC" 1 "PASSED_DTC" 2 "FAILED_DTC" 3 "UNABLE_TO_TEST_DTC";
VAL_ 912 EPAS2_d020_posAbs 0 "NOT_TESTED_DTC" 1 "PASSED_DTC" 2 "FAILED_DTC" 3 "UNABLE_TO_TEST_DTC";
VAL_ 912 EPAS2_d021_strokeOv 0 "NOT_TESTED_DTC" 1 "PASSED_DTC" 2 "FAILED_DTC" 3 "UNABLE_TO_TEST_DTC";
VAL_ 912 EPAS2_d022_motIdiff 0 "NOT_TESTED_DTC" 1 "PASSED_DTC" 2 "FAILED_DTC" 3 "UNABLE_TO_TEST_DTC";
VAL_ 912 EPAS2_d023_motOvc 0 "NOT_TESTED_DTC" 1 "PASSED_DTC" 2 "FAILED_DTC" 3 "UNABLE_TO_TEST_DTC";
VAL_ 912 EPAS2_d024_gndFault 0 "NOT_TESTED_DTC" 1 "PASSED_DTC" 2 "FAILED_DTC" 3 "UNABLE_TO_TEST_DTC";
VAL_ 912 EPAS2_d025_motShort 0 "NOT_TESTED_DTC" 1 "PASSED_DTC" 2 "FAILED_DTC" 3 "UNABLE_TO_TEST_DTC";
VAL_ 912 EPAS2_d026_motOpen 0 "NOT_TESTED_DTC" 1 "PASSED_DTC" 2 "FAILED_DTC" 3 "UNABLE_TO_TEST_DTC";
VAL_ 912 EPAS2_d027_svcc5 0 "NOT_TESTED_DTC" 1 "PASSED_DTC" 2 "FAILED_DTC" 3 "UNABLE_TO_TEST_DTC";
VAL_ 912 EPAS2_d028_svcc52 0 "NOT_TESTED_DTC" 1 "PASSED_DTC" 2 "FAILED_DTC" 3 "UNABLE_TO_TEST_DTC";
VAL_ 912 EPAS2_d029_variantCheck 0 "NOT_TESTED_DTC" 1 "PASSED_DTC" 2 "FAILED_DTC" 3 "UNABLE_TO_TEST_DTC";
VAL_ 912 EPAS2_d030_batSigOpen 0 "NOT_TESTED_DTC" 1 "PASSED_DTC" 2 "FAILED_DTC" 3 "UNABLE_TO_TEST_DTC";
VAL_ 912 EPAS2_d031_offsetOver 0 "NOT_TESTED_DTC" 1 "PASSED_DTC" 2 "FAILED_DTC" 3 "UNABLE_TO_TEST_DTC";
VAL_ 912 EPAS2_d032_subSpiTime 0 "NOT_TESTED_DTC" 1 "PASSED_DTC" 2 "FAILED_DTC" 3 "UNABLE_TO_TEST_DTC";
VAL_ 912 EPAS2_d033_subWatchdog 0 "NOT_TESTED_DTC" 1 "PASSED_DTC" 2 "FAILED_DTC" 3 "UNABLE_TO_TEST_DTC";
VAL_ 912 EPAS2_d034_batUv 0 "NOT_TESTED_DTC" 1 "PASSED_DTC" 2 "FAILED_DTC" 3 "UNABLE_TO_TEST_DTC";
VAL_ 912 EPAS2_d035_batOv 0 "NOT_TESTED_DTC" 1 "PASSED_DTC" 2 "FAILED_DTC" 3 "UNABLE_TO_TEST_DTC";
VAL_ 912 EPAS2_d036_posInc 0 "NOT_TESTED_DTC" 1 "PASSED_DTC" 2 "FAILED_DTC" 3 "UNABLE_TO_TEST_DTC";
VAL_ 912 EPAS2_d037_precharge 0 "NOT_TESTED_DTC" 1 "PASSED_DTC" 2 "FAILED_DTC" 3 "UNABLE_TO_TEST_DTC";
VAL_ 912 EPAS2_d038_ceOpen 0 "NOT_TESTED_DTC" 1 "PASSED_DTC" 2 "FAILED_DTC" 3 "UNABLE_TO_TEST_DTC";
VAL_ 912 EPAS2_d039_prechargeWl 0 "NOT_TESTED_DTC" 1 "PASSED_DTC" 2 "FAILED_DTC" 3 "UNABLE_TO_TEST_DTC";
VAL_ 912 EPAS2_d040_offsetDiff 0 "NOT_TESTED_DTC" 1 "PASSED_DTC" 2 "FAILED_DTC" 3 "UNABLE_TO_TEST_DTC";
VAL_ 912 EPAS2_d041_tempSensError 0 "NOT_TESTED_DTC" 1 "PASSED_DTC" 2 "FAILED_DTC" 3 "UNABLE_TO_TEST_DTC";
VAL_ 912 EPAS2_d042_overHeatProtect 0 "NOT_TESTED_DTC" 1 "PASSED_DTC" 2 "FAILED_DTC" 3 "UNABLE_TO_TEST_DTC";
VAL_ 912 EPAS2_d043_eepromError 0 "NOT_TESTED_DTC" 1 "PASSED_DTC" 2 "FAILED_DTC" 3 "UNABLE_TO_TEST_DTC";
VAL_ 912 EPAS2_d044_trqSensCal 0 "NOT_TESTED_DTC" 1 "PASSED_DTC" 2 "FAILED_DTC" 3 "UNABLE_TO_TEST_DTC";
VAL_ 912 EPAS2_d045_currentSensCal 0 "NOT_TESTED_DTC" 1 "PASSED_DTC" 2 "FAILED_DTC" 3 "UNABLE_TO_TEST_DTC";
VAL_ 912 EPAS2_d046_canBusOff 0 "NOT_TESTED_DTC" 1 "PASSED_DTC" 2 "FAILED_DTC" 3 "UNABLE_TO_TEST_DTC";
VAL_ 912 EPAS2_d047_dasMia 0 "NOT_TESTED_DTC" 1 "PASSED_DTC" 2 "FAILED_DTC" 3 "UNABLE_TO_TEST_DTC";
VAL_ 912 EPAS2_d048_dasCntError 0 "NOT_TESTED_DTC" 1 "PASSED_DTC" 2 "FAILED_DTC" 3 "UNABLE_TO_TEST_DTC";
VAL_ 912 EPAS2_d049_dasCsError 0 "NOT_TESTED_DTC" 1 "PASSED_DTC" 2 "FAILED_DTC" 3 "UNABLE_TO_TEST_DTC";
VAL_ 912 EPAS2_d050_espWsMia 0 "NOT_TESTED_DTC" 1 "PASSED_DTC" 2 "FAILED_DTC" 3 "UNABLE_TO_TEST_DTC";
VAL_ 912 EPAS2_d051_espWsCntError 0 "NOT_TESTED_DTC" 1 "PASSED_DTC" 2 "FAILED_DTC" 3 "UNABLE_TO_TEST_DTC";
VAL_ 912 EPAS2_d052_espWsCsError 0 "NOT_TESTED_DTC" 1 "PASSED_DTC" 2 "FAILED_DTC" 3 "UNABLE_TO_TEST_DTC";
VAL_ 912 EPAS2_d053_espbMia 0 "NOT_TESTED_DTC" 1 "PASSED_DTC" 2 "FAILED_DTC" 3 "UNABLE_TO_TEST_DTC";
VAL_ 912 EPAS2_d054_espbCntError 0 "NOT_TESTED_DTC" 1 "PASSED_DTC" 2 "FAILED_DTC" 3 "UNABLE_TO_TEST_DTC";
VAL_ 912 EPAS2_d055_espbCsError 0 "NOT_TESTED_DTC" 1 "PASSED_DTC" 2 "FAILED_DTC" 3 "UNABLE_TO_TEST_DTC";
VAL_ 912 EPAS2_d056_espbQf 0 "NOT_TESTED_DTC" 1 "PASSED_DTC" 2 "FAILED_DTC" 3 "UNABLE_TO_TEST_DTC";
VAL_ 912 EPAS2_d057_espcMia 0 "NOT_TESTED_DTC" 1 "PASSED_DTC" 2 "FAILED_DTC" 3 "UNABLE_TO_TEST_DTC";
VAL_ 912 EPAS2_d058_espcCntError 0 "NOT_TESTED_DTC" 1 "PASSED_DTC" 2 "FAILED_DTC" 3 "UNABLE_TO_TEST_DTC";
VAL_ 912 EPAS2_d059_espcCsError 0 "NOT_TESTED_DTC" 1 "PASSED_DTC" 2 "FAILED_DTC" 3 "UNABLE_TO_TEST_DTC";
VAL_ 912 EPAS2_d060_espcQf 0 "NOT_TESTED_DTC" 1 "PASSED_DTC" 2 "FAILED_DTC" 3 "UNABLE_TO_TEST_DTC";
VAL_ 912 EPAS2_d061_gtwMia 0 "NOT_TESTED_DTC" 1 "PASSED_DTC" 2 "FAILED_DTC" 3 "UNABLE_TO_TEST_DTC";
VAL_ 912 EPAS2_d062_gtwCntError 0 "NOT_TESTED_DTC" 1 "PASSED_DTC" 2 "FAILED_DTC" 3 "UNABLE_TO_TEST_DTC";
VAL_ 912 EPAS2_d063_gtwCsError 0 "NOT_TESTED_DTC" 1 "PASSED_DTC" 2 "FAILED_DTC" 3 "UNABLE_TO_TEST_DTC";
VAL_ 912 EPAS2_d064_epbMia 0 "NOT_TESTED_DTC" 1 "PASSED_DTC" 2 "FAILED_DTC" 3 "UNABLE_TO_TEST_DTC";
VAL_ 912 EPAS2_d065_epbCntError 0 "NOT_TESTED_DTC" 1 "PASSED_DTC" 2 "FAILED_DTC" 3 "UNABLE_TO_TEST_DTC";
VAL_ 912 EPAS2_d066_epbCsError 0 "NOT_TESTED_DTC" 1 "PASSED_DTC" 2 "FAILED_DTC" 3 "UNABLE_TO_TEST_DTC";
VAL_ 912 EPAS2_d067_diMia 0 "NOT_TESTED_DTC" 1 "PASSED_DTC" 2 "FAILED_DTC" 3 "UNABLE_TO_TEST_DTC";
VAL_ 912 EPAS2_d068_diCntError 0 "NOT_TESTED_DTC" 1 "PASSED_DTC" 2 "FAILED_DTC" 3 "UNABLE_TO_TEST_DTC";
VAL_ 912 EPAS2_d069_diCsError 0 "NOT_TESTED_DTC" 1 "PASSED_DTC" 2 "FAILED_DTC" 3 "UNABLE_TO_TEST_DTC";
VAL_ 912 EPAS2_d070_sasMia 0 "NOT_TESTED_DTC" 1 "PASSED_DTC" 2 "FAILED_DTC" 3 "UNABLE_TO_TEST_DTC";
VAL_ 912 EPAS2_d071_sasCntError 0 "NOT_TESTED_DTC" 1 "PASSED_DTC" 2 "FAILED_DTC" 3 "UNABLE_TO_TEST_DTC";
VAL_ 912 EPAS2_d072_sasCsError 0 "NOT_TESTED_DTC" 1 "PASSED_DTC" 2 "FAILED_DTC" 3 "UNABLE_TO_TEST_DTC";
VAL_ 912 EPAS2_d073_sasStat 0 "NOT_TESTED_DTC" 1 "PASSED_DTC" 2 "FAILED_DTC" 3 "UNABLE_TO_TEST_DTC";
VAL_ 912 EPAS2_d074_eacCancelled 0 "NOT_TESTED_DTC" 1 "PASSED_DTC" 2 "FAILED_DTC" 3 "UNABLE_TO_TEST_DTC";
VAL_ 912 EPAS2_d075_espWsQf 0 "NOT_TESTED_DTC" 1 "PASSED_DTC" 2 "FAILED_DTC" 3 "UNABLE_TO_TEST_DTC";
VAL_ 912 EPAS2_d076_gtwOdoMia 0 "NOT_TESTED_DTC" 1 "PASSED_DTC" 2 "FAILED_DTC" 3 "UNABLE_TO_TEST_DTC";
VAL_ 912 EPAS2_d077_pinionVelDiff 0 "NOT_TESTED_DTC" 1 "PASSED_DTC" 2 "FAILED_DTC" 3 "UNABLE_TO_TEST_DTC";
VAL_ 912 EPAS2_d078_can2BusOff 0 "NOT_TESTED_DTC" 1 "PASSED_DTC" 2 "FAILED_DTC" 3 "UNABLE_TO_TEST_DTC";
VAL_ 912 EPAS2_d079_espPrivate1Mia 0 "NOT_TESTED_DTC" 1 "PASSED_DTC" 2 "FAILED_DTC" 3 "UNABLE_TO_TEST_DTC";
VAL_ 912 EPAS2_d080_abnormalShutdown 0 "NOT_TESTED_DTC" 1 "PASSED_DTC" 2 "FAILED_DTC" 3 "UNABLE_TO_TEST_DTC";

VAL_ 914 EPAS3P_d001_sent1Mia 0 "NOT_TESTED_DTC" 1 "PASSED_DTC" 2 "FAILED_DTC" 3 "UNABLE_TO_TEST_DTC";
VAL_ 914 EPAS3P_d002_sent1Error 0 "NOT_TESTED_DTC" 1 "PASSED_DTC" 2 "FAILED_DTC" 3 "UNABLE_TO_TEST_DTC";
VAL_ 914 EPAS3P_d003_trqSens1Supply 0 "NOT_TESTED_DTC" 1 "PASSED_DTC" 2 "FAILED_DTC" 3 "UNABLE_TO_TEST_DTC";
VAL_ 914 EPAS3P_d004_trqSens1Eeprom 0 "NOT_TESTED_DTC" 1 "PASSED_DTC" 2 "FAILED_DTC" 3 "UNABLE_TO_TEST_DTC";
VAL_ 914 EPAS3P_d005_sent2Mia 0 "NOT_TESTED_DTC" 1 "PASSED_DTC" 2 "FAILED_DTC" 3 "UNABLE_TO_TEST_DTC";
VAL_ 914 EPAS3P_d006_sent2Error 0 "NOT_TESTED_DTC" 1 "PASSED_DTC" 2 "FAILED_DTC" 3 "UNABLE_TO_TEST_DTC";
VAL_ 914 EPAS3P_d007_trqSens2Supply 0 "NOT_TESTED_DTC" 1 "PASSED_DTC" 2 "FAILED_DTC" 3 "UNABLE_TO_TEST_DTC";
VAL_ 914 EPAS3P_d008_trqSens2Eeprom 0 "NOT_TESTED_DTC" 1 "PASSED_DTC" 2 "FAILED_DTC" 3 "UNABLE_TO_TEST_DTC";
VAL_ 914 EPAS3P_d009_sentDiff 0 "NOT_TESTED_DTC" 1 "PASSED_DTC" 2 "FAILED_DTC" 3 "UNABLE_TO_TEST_DTC";
VAL_ 914 EPAS3P_d010_trqSensCalError 0 "NOT_TESTED_DTC" 1 "PASSED_DTC" 2 "FAILED_DTC" 3 "UNABLE_TO_TEST_DTC";
VAL_ 914 EPAS3P_d011_currentSensError 0 "NOT_TESTED_DTC" 1 "PASSED_DTC" 2 "FAILED_DTC" 3 "UNABLE_TO_TEST_DTC";
VAL_ 914 EPAS3P_d012_currentSensCalError 0 "NOT_TESTED_DTC" 1 "PASSED_DTC" 2 "FAILED_DTC" 3 "UNABLE_TO_TEST_DTC";
VAL_ 914 EPAS3P_d013_gateDriveError 0 "NOT_TESTED_DTC" 1 "PASSED_DTC" 2 "FAILED_DTC" 3 "UNABLE_TO_TEST_DTC";
VAL_ 914 EPAS3P_d014_gateDriveTxError 0 "NOT_TESTED_DTC" 1 "PASSED_DTC" 2 "FAILED_DTC" 3 "UNABLE_TO_TEST_DTC";
VAL_ 914 EPAS3P_d015_gateDriveEeprom 0 "NOT_TESTED_DTC" 1 "PASSED_DTC" 2 "FAILED_DTC" 3 "UNABLE_TO_TEST_DTC";
VAL_ 914 EPAS3P_d016_phaseUhighUv 0 "NOT_TESTED_DTC" 1 "PASSED_DTC" 2 "FAILED_DTC" 3 "UNABLE_TO_TEST_DTC";
VAL_ 914 EPAS3P_d017_phaseUlowUv 0 "NOT_TESTED_DTC" 1 "PASSED_DTC" 2 "FAILED_DTC" 3 "UNABLE_TO_TEST_DTC";
VAL_ 914 EPAS3P_d018_phaseVhighUv 0 "NOT_TESTED_DTC" 1 "PASSED_DTC" 2 "FAILED_DTC" 3 "UNABLE_TO_TEST_DTC";
VAL_ 914 EPAS3P_d019_phaseVlowUv 0 "NOT_TESTED_DTC" 1 "PASSED_DTC" 2 "FAILED_DTC" 3 "UNABLE_TO_TEST_DTC";
VAL_ 914 EPAS3P_d020_phaseWhighUv 0 "NOT_TESTED_DTC" 1 "PASSED_DTC" 2 "FAILED_DTC" 3 "UNABLE_TO_TEST_DTC";
VAL_ 914 EPAS3P_d021_phaseWlowUv 0 "NOT_TESTED_DTC" 1 "PASSED_DTC" 2 "FAILED_DTC" 3 "UNABLE_TO_TEST_DTC";
VAL_ 914 EPAS3P_d022_phaseUhighOv 0 "NOT_TESTED_DTC" 1 "PASSED_DTC" 2 "FAILED_DTC" 3 "UNABLE_TO_TEST_DTC";
VAL_ 914 EPAS3P_d023_phaseUlowOv 0 "NOT_TESTED_DTC" 1 "PASSED_DTC" 2 "FAILED_DTC" 3 "UNABLE_TO_TEST_DTC";
VAL_ 914 EPAS3P_d024_phaseVhighOv 0 "NOT_TESTED_DTC" 1 "PASSED_DTC" 2 "FAILED_DTC" 3 "UNABLE_TO_TEST_DTC";
VAL_ 914 EPAS3P_d025_phaseVlowOv 0 "NOT_TESTED_DTC" 1 "PASSED_DTC" 2 "FAILED_DTC" 3 "UNABLE_TO_TEST_DTC";
VAL_ 914 EPAS3P_d026_phaseWhighOv 0 "NOT_TESTED_DTC" 1 "PASSED_DTC" 2 "FAILED_DTC" 3 "UNABLE_TO_TEST_DTC";
VAL_ 914 EPAS3P_d027_phaseWlowOv 0 "NOT_TESTED_DTC" 1 "PASSED_DTC" 2 "FAILED_DTC" 3 "UNABLE_TO_TEST_DTC";
VAL_ 914 EPAS3P_d028_phaseUbootUv 0 "NOT_TESTED_DTC" 1 "PASSED_DTC" 2 "FAILED_DTC" 3 "UNABLE_TO_TEST_DTC";
VAL_ 914 EPAS3P_d029_phaseVbootUv 0 "NOT_TESTED_DTC" 1 "PASSED_DTC" 2 "FAILED_DTC" 3 "UNABLE_TO_TEST_DTC";
VAL_ 914 EPAS3P_d030_phaseWbootUv 0 "NOT_TESTED_DTC" 1 "PASSED_DTC" 2 "FAILED_DTC" 3 "UNABLE_TO_TEST_DTC";
VAL_ 914 EPAS3P_d031_abnormalShutdown 0 "NOT_TESTED_DTC" 1 "PASSED_DTC" 2 "FAILED_DTC" 3 "UNABLE_TO_TEST_DTC";
VAL_ 914 EPAS3P_d032_vRegOutputUv 0 "NOT_TESTED_DTC" 1 "PASSED_DTC" 2 "FAILED_DTC" 3 "UNABLE_TO_TEST_DTC";
VAL_ 914 EPAS3P_d033_vRegOutputOv 0 "NOT_TESTED_DTC" 1 "PASSED_DTC" 2 "FAILED_DTC" 3 "UNABLE_TO_TEST_DTC";
VAL_ 914 EPAS3P_d034_vRegError 0 "NOT_TESTED_DTC" 1 "PASSED_DTC" 2 "FAILED_DTC" 3 "UNABLE_TO_TEST_DTC";
VAL_ 914 EPAS3P_d035_vbbSupplyUv 0 "NOT_TESTED_DTC" 1 "PASSED_DTC" 2 "FAILED_DTC" 3 "UNABLE_TO_TEST_DTC";
VAL_ 914 EPAS3P_d036_vbbSupplyOv 0 "NOT_TESTED_DTC" 1 "PASSED_DTC" 2 "FAILED_DTC" 3 "UNABLE_TO_TEST_DTC";
VAL_ 914 EPAS3P_d037_motPos1ParityError 0 "NOT_TESTED_DTC" 1 "PASSED_DTC" 2 "FAILED_DTC" 3 "UNABLE_TO_TEST_DTC";
VAL_ 914 EPAS3P_d038_motPos1Uv 0 "NOT_TESTED_DTC" 1 "PASSED_DTC" 2 "FAILED_DTC" 3 "UNABLE_TO_TEST_DTC";
VAL_ 914 EPAS3P_d039_motPos1MagnetMia 0 "NOT_TESTED_DTC" 1 "PASSED_DTC" 2 "FAILED_DTC" 3 "UNABLE_TO_TEST_DTC";
VAL_ 914 EPAS3P_d040_motPos1LogicError 0 "NOT_TESTED_DTC" 1 "PASSED_DTC" 2 "FAILED_DTC" 3 "UNABLE_TO_TEST_DTC";
VAL_ 914 EPAS3P_d041_motPos1tempError 0 "NOT_TESTED_DTC" 1 "PASSED_DTC" 2 "FAILED_DTC" 3 "UNABLE_TO_TEST_DTC";
VAL_ 914 EPAS3P_d042_motPos2ParityError 0 "NOT_TESTED_DTC" 1 "PASSED_DTC" 2 "FAILED_DTC" 3 "UNABLE_TO_TEST_DTC";
VAL_ 914 EPAS3P_d043_motPos2Uv 0 "NOT_TESTED_DTC" 1 "PASSED_DTC" 2 "FAILED_DTC" 3 "UNABLE_TO_TEST_DTC";
VAL_ 914 EPAS3P_d044_motPos2MagnetMia 0 "NOT_TESTED_DTC" 1 "PASSED_DTC" 2 "FAILED_DTC" 3 "UNABLE_TO_TEST_DTC";
VAL_ 914 EPAS3P_d045_motPos2LogicError 0 "NOT_TESTED_DTC" 1 "PASSED_DTC" 2 "FAILED_DTC" 3 "UNABLE_TO_TEST_DTC";
VAL_ 914 EPAS3P_d046_motPos2tempError 0 "NOT_TESTED_DTC" 1 "PASSED_DTC" 2 "FAILED_DTC" 3 "UNABLE_TO_TEST_DTC";
VAL_ 914 EPAS3P_d047_motPosCorrError 0 "NOT_TESTED_DTC" 1 "PASSED_DTC" 2 "FAILED_DTC" 3 "UNABLE_TO_TEST_DTC";
VAL_ 914 EPAS3P_d048_motPosCalError 0 "NOT_TESTED_DTC" 1 "PASSED_DTC" 2 "FAILED_DTC" 3 "UNABLE_TO_TEST_DTC";
VAL_ 914 EPAS3P_d049_piCtrlError 0 "NOT_TESTED_DTC" 1 "PASSED_DTC" 2 "FAILED_DTC" 3 "UNABLE_TO_TEST_DTC";
VAL_ 914 EPAS3P_d050_mcuSmuError 0 "NOT_TESTED_DTC" 1 "PASSED_DTC" 2 "FAILED_DTC" 3 "UNABLE_TO_TEST_DTC";
VAL_ 914 EPAS3P_d051_mcuSupError 0 "NOT_TESTED_DTC" 1 "PASSED_DTC" 2 "FAILED_DTC" 3 "UNABLE_TO_TEST_DTC";
VAL_ 914 EPAS3P_d052_intWatchdogError 0 "NOT_TESTED_DTC" 1 "PASSED_DTC" 2 "FAILED_DTC" 3 "UNABLE_TO_TEST_DTC";
VAL_ 914 EPAS3P_d053_extWatchdogError 0 "NOT_TESTED_DTC" 1 "PASSED_DTC" 2 "FAILED_DTC" 3 "UNABLE_TO_TEST_DTC";
VAL_ 914 EPAS3P_d054_memoryProtectError 0 "NOT_TESTED_DTC" 1 "PASSED_DTC" 2 "FAILED_DTC" 3 "UNABLE_TO_TEST_DTC";
VAL_ 914 EPAS3P_d055_floatPointError 0 "NOT_TESTED_DTC" 1 "PASSED_DTC" 2 "FAILED_DTC" 3 "UNABLE_TO_TEST_DTC";
VAL_ 914 EPAS3P_d056_battUv 0 "NOT_TESTED_DTC" 1 "PASSED_DTC" 2 "FAILED_DTC" 3 "UNABLE_TO_TEST_DTC";
VAL_ 914 EPAS3P_d057_battUvReduced 0 "NOT_TESTED_DTC" 1 "PASSED_DTC" 2 "FAILED_DTC" 3 "UNABLE_TO_TEST_DTC";
VAL_ 914 EPAS3P_d058_battOv 0 "NOT_TESTED_DTC" 1 "PASSED_DTC" 2 "FAILED_DTC" 3 "UNABLE_TO_TEST_DTC";
VAL_ 914 EPAS3P_d059_battOvReduced 0 "NOT_TESTED_DTC" 1 "PASSED_DTC" 2 "FAILED_DTC" 3 "UNABLE_TO_TEST_DTC";
VAL_ 914 EPAS3P_d060_battBridgeDiff 0 "NOT_TESTED_DTC" 1 "PASSED_DTC" 2 "FAILED_DTC" 3 "UNABLE_TO_TEST_DTC";
VAL_ 914 EPAS3P_d061_bridgeUv 0 "NOT_TESTED_DTC" 1 "PASSED_DTC" 2 "FAILED_DTC" 3 "UNABLE_TO_TEST_DTC";
VAL_ 914 EPAS3P_d062_assistCorrError 0 "NOT_TESTED_DTC" 1 "PASSED_DTC" 2 "FAILED_DTC" 3 "UNABLE_TO_TEST_DTC";
VAL_ 914 EPAS3P_d063_dampCorrError 0 "NOT_TESTED_DTC" 1 "PASSED_DTC" 2 "FAILED_DTC" 3 "UNABLE_TO_TEST_DTC";
VAL_ 914 EPAS3P_d064_phaseCompCorrError 0 "NOT_TESTED_DTC" 1 "PASSED_DTC" 2 "FAILED_DTC" 3 "UNABLE_TO_TEST_DTC";
VAL_ 914 EPAS3P_d065_trqTarCorrError 0 "NOT_TESTED_DTC" 1 "PASSED_DTC" 2 "FAILED_DTC" 3 "UNABLE_TO_TEST_DTC";
VAL_ 914 EPAS3P_d066_returnCorrError 0 "NOT_TESTED_DTC" 1 "PASSED_DTC" 2 "FAILED_DTC" 3 "UNABLE_TO_TEST_DTC";
VAL_ 914 EPAS3P_d067_yawDampCorrError 0 "NOT_TESTED_DTC" 1 "PASSED_DTC" 2 "FAILED_DTC" 3 "UNABLE_TO_TEST_DTC";
VAL_ 914 EPAS3P_d068_hystCorrError 0 "NOT_TESTED_DTC" 1 "PASSED_DTC" 2 "FAILED_DTC" 3 "UNABLE_TO_TEST_DTC";
VAL_ 914 EPAS3P_d069_eacCorrError 0 "NOT_TESTED_DTC" 1 "PASSED_DTC" 2 "FAILED_DTC" 3 "UNABLE_TO_TEST_DTC";
VAL_ 914 EPAS3P_d070_hodCorrError 0 "NOT_TESTED_DTC" 1 "PASSED_DTC" 2 "FAILED_DTC" 3 "UNABLE_TO_TEST_DTC";
VAL_ 914 EPAS3P_d071_vehSpdCorrError 0 "NOT_TESTED_DTC" 1 "PASSED_DTC" 2 "FAILED_DTC" 3 "UNABLE_TO_TEST_DTC";
VAL_ 914 EPAS3P_d072_motFeedFwdError 0 "NOT_TESTED_DTC" 1 "PASSED_DTC" 2 "FAILED_DTC" 3 "UNABLE_TO_TEST_DTC";
VAL_ 914 EPAS3P_d073_motParEstError 0 "NOT_TESTED_DTC" 1 "PASSED_DTC" 2 "FAILED_DTC" 3 "UNABLE_TO_TEST_DTC";
VAL_ 914 EPAS3P_d074_overHeatProtect 0 "NOT_TESTED_DTC" 1 "PASSED_DTC" 2 "FAILED_DTC" 3 "UNABLE_TO_TEST_DTC";
VAL_ 914 EPAS3P_d075_fspPwrCut 0 "NOT_TESTED_DTC" 1 "PASSED_DTC" 2 "FAILED_DTC" 3 "UNABLE_TO_TEST_DTC";
VAL_ 914 EPAS3P_d076_tempSensOutofRange 0 "NOT_TESTED_DTC" 1 "PASSED_DTC" 2 "FAILED_DTC" 3 "UNABLE_TO_TEST_DTC";
VAL_ 914 EPAS3P_d077_highSideFetError 0 "NOT_TESTED_DTC" 1 "PASSED_DTC" 2 "FAILED_DTC" 3 "UNABLE_TO_TEST_DTC";
VAL_ 914 EPAS3P_d078_phaseDisconnectError 0 "NOT_TESTED_DTC" 1 "PASSED_DTC" 2 "FAILED_DTC" 3 "UNABLE_TO_TEST_DTC";
VAL_ 914 EPAS3P_d079_backupCurrentPlaus 0 "NOT_TESTED_DTC" 1 "PASSED_DTC" 2 "FAILED_DTC" 3 "UNABLE_TO_TEST_DTC";
VAL_ 914 EPAS3P_d080_ecuInitArbError 0 "NOT_TESTED_DTC" 1 "PASSED_DTC" 2 "FAILED_DTC" 3 "UNABLE_TO_TEST_DTC";
VAL_ 914 EPAS3P_d081_coggCompError 0 "NOT_TESTED_DTC" 1 "PASSED_DTC" 2 "FAILED_DTC" 3 "UNABLE_TO_TEST_DTC";
VAL_ 914 EPAS3P_d082_polarityCalError 0 "NOT_TESTED_DTC" 1 "PASSED_DTC" 2 "FAILED_DTC" 3 "UNABLE_TO_TEST_DTC";
VAL_ 914 EPAS3P_d083_crcMismatch 0 "NOT_TESTED_DTC" 1 "PASSED_DTC" 2 "FAILED_DTC" 3 "UNABLE_TO_TEST_DTC";
VAL_ 914 EPAS3P_d084_eacCancelled 0 "NOT_TESTED_DTC" 1 "PASSED_DTC" 2 "FAILED_DTC" 3 "UNABLE_TO_TEST_DTC";
VAL_ 914 EPAS3P_d085_canBusOff 0 "NOT_TESTED_DTC" 1 "PASSED_DTC" 2 "FAILED_DTC" 3 "UNABLE_TO_TEST_DTC";
VAL_ 914 EPAS3P_d086_dasMia 0 "NOT_TESTED_DTC" 1 "PASSED_DTC" 2 "FAILED_DTC" 3 "UNABLE_TO_TEST_DTC";
VAL_ 914 EPAS3P_d087_dasCntError 0 "NOT_TESTED_DTC" 1 "PASSED_DTC" 2 "FAILED_DTC" 3 "UNABLE_TO_TEST_DTC";
VAL_ 914 EPAS3P_d088_dasCsError 0 "NOT_TESTED_DTC" 1 "PASSED_DTC" 2 "FAILED_DTC" 3 "UNABLE_TO_TEST_DTC";
VAL_ 914 EPAS3P_d089_espWsMia 0 "NOT_TESTED_DTC" 1 "PASSED_DTC" 2 "FAILED_DTC" 3 "UNABLE_TO_TEST_DTC";
VAL_ 914 EPAS3P_d090_espWsCntError 0 "NOT_TESTED_DTC" 1 "PASSED_DTC" 2 "FAILED_DTC" 3 "UNABLE_TO_TEST_DTC";
VAL_ 914 EPAS3P_d091_espWsCsError 0 "NOT_TESTED_DTC" 1 "PASSED_DTC" 2 "FAILED_DTC" 3 "UNABLE_TO_TEST_DTC";
VAL_ 914 EPAS3P_d092_espbMia 0 "NOT_TESTED_DTC" 1 "PASSED_DTC" 2 "FAILED_DTC" 3 "UNABLE_TO_TEST_DTC";
VAL_ 914 EPAS3P_d093_espbCntError 0 "NOT_TESTED_DTC" 1 "PASSED_DTC" 2 "FAILED_DTC" 3 "UNABLE_TO_TEST_DTC";
VAL_ 914 EPAS3P_d094_espbCsError 0 "NOT_TESTED_DTC" 1 "PASSED_DTC" 2 "FAILED_DTC" 3 "UNABLE_TO_TEST_DTC";
VAL_ 914 EPAS3P_d095_espbQf 0 "NOT_TESTED_DTC" 1 "PASSED_DTC" 2 "FAILED_DTC" 3 "UNABLE_TO_TEST_DTC";
VAL_ 914 EPAS3P_d096_espcMia 0 "NOT_TESTED_DTC" 1 "PASSED_DTC" 2 "FAILED_DTC" 3 "UNABLE_TO_TEST_DTC";
VAL_ 914 EPAS3P_d097_espcCntError 0 "NOT_TESTED_DTC" 1 "PASSED_DTC" 2 "FAILED_DTC" 3 "UNABLE_TO_TEST_DTC";
VAL_ 914 EPAS3P_d098_espcCsError 0 "NOT_TESTED_DTC" 1 "PASSED_DTC" 2 "FAILED_DTC" 3 "UNABLE_TO_TEST_DTC";
VAL_ 914 EPAS3P_d099_espcQf 0 "NOT_TESTED_DTC" 1 "PASSED_DTC" 2 "FAILED_DTC" 3 "UNABLE_TO_TEST_DTC";
VAL_ 914 EPAS3P_d100_gtwMia 0 "NOT_TESTED_DTC" 1 "PASSED_DTC" 2 "FAILED_DTC" 3 "UNABLE_TO_TEST_DTC";
VAL_ 914 EPAS3P_d101_gtwCntError 0 "NOT_TESTED_DTC" 1 "PASSED_DTC" 2 "FAILED_DTC" 3 "UNABLE_TO_TEST_DTC";
VAL_ 914 EPAS3P_d102_gtwCsError 0 "NOT_TESTED_DTC" 1 "PASSED_DTC" 2 "FAILED_DTC" 3 "UNABLE_TO_TEST_DTC";
VAL_ 914 EPAS3P_d103_apsMia 0 "NOT_TESTED_DTC" 1 "PASSED_DTC" 2 "FAILED_DTC" 3 "UNABLE_TO_TEST_DTC";
VAL_ 914 EPAS3P_d104_apsCntError 0 "NOT_TESTED_DTC" 1 "PASSED_DTC" 2 "FAILED_DTC" 3 "UNABLE_TO_TEST_DTC";
VAL_ 914 EPAS3P_d105_apsCsError 0 "NOT_TESTED_DTC" 1 "PASSED_DTC" 2 "FAILED_DTC" 3 "UNABLE_TO_TEST_DTC";
VAL_ 914 EPAS3P_d106_diMia 0 "NOT_TESTED_DTC" 1 "PASSED_DTC" 2 "FAILED_DTC" 3 "UNABLE_TO_TEST_DTC";
VAL_ 914 EPAS3P_d107_diCntError 0 "NOT_TESTED_DTC" 1 "PASSED_DTC" 2 "FAILED_DTC" 3 "UNABLE_TO_TEST_DTC";
VAL_ 914 EPAS3P_d108_diCsError 0 "NOT_TESTED_DTC" 1 "PASSED_DTC" 2 "FAILED_DTC" 3 "UNABLE_TO_TEST_DTC";
VAL_ 914 EPAS3P_d109_sasMia 0 "NOT_TESTED_DTC" 1 "PASSED_DTC" 2 "FAILED_DTC" 3 "UNABLE_TO_TEST_DTC";
VAL_ 914 EPAS3P_d110_sasCntError 0 "NOT_TESTED_DTC" 1 "PASSED_DTC" 2 "FAILED_DTC" 3 "UNABLE_TO_TEST_DTC";
VAL_ 914 EPAS3P_d111_sasCsError 0 "NOT_TESTED_DTC" 1 "PASSED_DTC" 2 "FAILED_DTC" 3 "UNABLE_TO_TEST_DTC";
VAL_ 914 EPAS3P_d112_sasStatError 0 "NOT_TESTED_DTC" 1 "PASSED_DTC" 2 "FAILED_DTC" 3 "UNABLE_TO_TEST_DTC";
VAL_ 914 EPAS3P_d113_espWsQf 0 "NOT_TESTED_DTC" 1 "PASSED_DTC" 2 "FAILED_DTC" 3 "UNABLE_TO_TEST_DTC";
VAL_ 914 EPAS3P_d114_gtwOdoMia 0 "NOT_TESTED_DTC" 1 "PASSED_DTC" 2 "FAILED_DTC" 3 "UNABLE_TO_TEST_DTC";
VAL_ 914 EPAS3P_d115_ecuStatMia 0 "NOT_TESTED_DTC" 1 "PASSED_DTC" 2 "FAILED_DTC" 3 "UNABLE_TO_TEST_DTC";
VAL_ 914 EPAS3P_d116_ecuStatCntError 0 "NOT_TESTED_DTC" 1 "PASSED_DTC" 2 "FAILED_DTC" 3 "UNABLE_TO_TEST_DTC";
VAL_ 914 EPAS3P_d117_ecuStatCrcError 0 "NOT_TESTED_DTC" 1 "PASSED_DTC" 2 "FAILED_DTC" 3 "UNABLE_TO_TEST_DTC";
VAL_ 914 EPAS3P_d118_espPriv1Mia 0 "NOT_TESTED_DTC" 1 "PASSED_DTC" 2 "FAILED_DTC" 3 "UNABLE_TO_TEST_DTC";
VAL_ 914 EPAS3P_d119_espPriv1CntError 0 "NOT_TESTED_DTC" 1 "PASSED_DTC" 2 "FAILED_DTC" 3 "UNABLE_TO_TEST_DTC";
VAL_ 914 EPAS3P_d120_espPriv1CsError 0 "NOT_TESTED_DTC" 1 "PASSED_DTC" 2 "FAILED_DTC" 3 "UNABLE_TO_TEST_DTC";
VAL_ 914 EPAS3P_d121_espPriv1Qf 0 "NOT_TESTED_DTC" 1 "PASSED_DTC" 2 "FAILED_DTC" 3 "UNABLE_TO_TEST_DTC";
VAL_ 914 EPAS3P_d122_privateBusOff 0 "NOT_TESTED_DTC" 1 "PASSED_DTC" 2 "FAILED_DTC" 3 "UNABLE_TO_TEST_DTC";
VAL_ 914 EPAS3P_d123_pvtEcuStatMia 0 "NOT_TESTED_DTC" 1 "PASSED_DTC" 2 "FAILED_DTC" 3 "UNABLE_TO_TEST_DTC";
VAL_ 914 EPAS3P_d124_pvtEcuStatCntError 0 "NOT_TESTED_DTC" 1 "PASSED_DTC" 2 "FAILED_DTC" 3 "UNABLE_TO_TEST_DTC";
VAL_ 914 EPAS3P_d125_pvtEcuStatCrcError 0 "NOT_TESTED_DTC" 1 "PASSED_DTC" 2 "FAILED_DTC" 3 "UNABLE_TO_TEST_DTC";
VAL_ 914 EPAS3P_d126_olpActive 0 "NOT_TESTED_DTC" 1 "PASSED_DTC" 2 "FAILED_DTC" 3 "UNABLE_TO_TEST_DTC";
VAL_ 914 EPAS3P_d127_combEcu2StatFail 0 "NOT_TESTED_DTC" 1 "PASSED_DTC" 2 "FAILED_DTC" 3 "UNABLE_TO_TEST_DTC";
VAL_ 914 EPAS3P_d128_tempSensStuckInRange 0 "NOT_TESTED_DTC" 1 "PASSED_DTC" 2 "FAILED_DTC" 3 "UNABLE_TO_TEST_DTC";
VAL_ 914 EPAS3P_d129_trqSensTrimOutRange 0 "NOT_TESTED_DTC" 1 "PASSED_DTC" 2 "FAILED_DTC" 3 "UNABLE_TO_TEST_DTC";
VAL_ 914 EPAS3P_d130_combEcu1StatFail 0 "NOT_TESTED_DTC" 1 "PASSED_DTC" 2 "FAILED_DTC" 3 "UNABLE_TO_TEST_DTC";
VAL_ 914 EPAS3P_d131_sasOffsetNotCal 0 "NOT_TESTED_DTC" 1 "PASSED_DTC" 2 "FAILED_DTC" 3 "UNABLE_TO_TEST_DTC";
VAL_ 914 EPAS3P_d132_phaseFeedbackError 0 "NOT_TESTED_DTC" 1 "PASSED_DTC" 2 "FAILED_DTC" 3 "UNABLE_TO_TEST_DTC";

VAL_ 913 EPAS3S_d001_sent1Mia 0 "NOT_TESTED_DTC" 1 "PASSED_DTC" 2 "FAILED_DTC" 3 "UNABLE_TO_TEST_DTC";
VAL_ 913 EPAS3S_d002_sent1Error 0 "NOT_TESTED_DTC" 1 "PASSED_DTC" 2 "FAILED_DTC" 3 "UNABLE_TO_TEST_DTC";
VAL_ 913 EPAS3S_d003_trqSens1Supply 0 "NOT_TESTED_DTC" 1 "PASSED_DTC" 2 "FAILED_DTC" 3 "UNABLE_TO_TEST_DTC";
VAL_ 913 EPAS3S_d004_trqSens1Eeprom 0 "NOT_TESTED_DTC" 1 "PASSED_DTC" 2 "FAILED_DTC" 3 "UNABLE_TO_TEST_DTC";
VAL_ 913 EPAS3S_d005_sent2Mia 0 "NOT_TESTED_DTC" 1 "PASSED_DTC" 2 "FAILED_DTC" 3 "UNABLE_TO_TEST_DTC";
VAL_ 913 EPAS3S_d006_sent2Error 0 "NOT_TESTED_DTC" 1 "PASSED_DTC" 2 "FAILED_DTC" 3 "UNABLE_TO_TEST_DTC";
VAL_ 913 EPAS3S_d007_trqSens2Supply 0 "NOT_TESTED_DTC" 1 "PASSED_DTC" 2 "FAILED_DTC" 3 "UNABLE_TO_TEST_DTC";
VAL_ 913 EPAS3S_d008_trqSens2Eeprom 0 "NOT_TESTED_DTC" 1 "PASSED_DTC" 2 "FAILED_DTC" 3 "UNABLE_TO_TEST_DTC";
VAL_ 913 EPAS3S_d009_sentDiff 0 "NOT_TESTED_DTC" 1 "PASSED_DTC" 2 "FAILED_DTC" 3 "UNABLE_TO_TEST_DTC";
VAL_ 913 EPAS3S_d010_trqSensCalError 0 "NOT_TESTED_DTC" 1 "PASSED_DTC" 2 "FAILED_DTC" 3 "UNABLE_TO_TEST_DTC";
VAL_ 913 EPAS3S_d011_currentSensError 0 "NOT_TESTED_DTC" 1 "PASSED_DTC" 2 "FAILED_DTC" 3 "UNABLE_TO_TEST_DTC";
VAL_ 913 EPAS3S_d012_currentSensCalError 0 "NOT_TESTED_DTC" 1 "PASSED_DTC" 2 "FAILED_DTC" 3 "UNABLE_TO_TEST_DTC";
VAL_ 913 EPAS3S_d013_gateDriveError 0 "NOT_TESTED_DTC" 1 "PASSED_DTC" 2 "FAILED_DTC" 3 "UNABLE_TO_TEST_DTC";
VAL_ 913 EPAS3S_d014_gateDriveTxError 0 "NOT_TESTED_DTC" 1 "PASSED_DTC" 2 "FAILED_DTC" 3 "UNABLE_TO_TEST_DTC";
VAL_ 913 EPAS3S_d015_gateDriveEeprom 0 "NOT_TESTED_DTC" 1 "PASSED_DTC" 2 "FAILED_DTC" 3 "UNABLE_TO_TEST_DTC";
VAL_ 913 EPAS3S_d016_phaseUhighUv 0 "NOT_TESTED_DTC" 1 "PASSED_DTC" 2 "FAILED_DTC" 3 "UNABLE_TO_TEST_DTC";
VAL_ 913 EPAS3S_d017_phaseUlowUv 0 "NOT_TESTED_DTC" 1 "PASSED_DTC" 2 "FAILED_DTC" 3 "UNABLE_TO_TEST_DTC";
VAL_ 913 EPAS3S_d018_phaseVhighUv 0 "NOT_TESTED_DTC" 1 "PASSED_DTC" 2 "FAILED_DTC" 3 "UNABLE_TO_TEST_DTC";
VAL_ 913 EPAS3S_d019_phaseVlowUv 0 "NOT_TESTED_DTC" 1 "PASSED_DTC" 2 "FAILED_DTC" 3 "UNABLE_TO_TEST_DTC";
VAL_ 913 EPAS3S_d020_phaseWhighUv 0 "NOT_TESTED_DTC" 1 "PASSED_DTC" 2 "FAILED_DTC" 3 "UNABLE_TO_TEST_DTC";
VAL_ 913 EPAS3S_d021_phaseWlowUv 0 "NOT_TESTED_DTC" 1 "PASSED_DTC" 2 "FAILED_DTC" 3 "UNABLE_TO_TEST_DTC";
VAL_ 913 EPAS3S_d022_phaseUhighOv 0 "NOT_TESTED_DTC" 1 "PASSED_DTC" 2 "FAILED_DTC" 3 "UNABLE_TO_TEST_DTC";
VAL_ 913 EPAS3S_d023_phaseUlowOv 0 "NOT_TESTED_DTC" 1 "PASSED_DTC" 2 "FAILED_DTC" 3 "UNABLE_TO_TEST_DTC";
VAL_ 913 EPAS3S_d024_phaseVhighOv 0 "NOT_TESTED_DTC" 1 "PASSED_DTC" 2 "FAILED_DTC" 3 "UNABLE_TO_TEST_DTC";
VAL_ 913 EPAS3S_d025_phaseVlowOv 0 "NOT_TESTED_DTC" 1 "PASSED_DTC" 2 "FAILED_DTC" 3 "UNABLE_TO_TEST_DTC";
VAL_ 913 EPAS3S_d026_phaseWhighOv 0 "NOT_TESTED_DTC" 1 "PASSED_DTC" 2 "FAILED_DTC" 3 "UNABLE_TO_TEST_DTC";
VAL_ 913 EPAS3S_d027_phaseWlowOv 0 "NOT_TESTED_DTC" 1 "PASSED_DTC" 2 "FAILED_DTC" 3 "UNABLE_TO_TEST_DTC";
VAL_ 913 EPAS3S_d028_phaseUbootUv 0 "NOT_TESTED_DTC" 1 "PASSED_DTC" 2 "FAILED_DTC" 3 "UNABLE_TO_TEST_DTC";
VAL_ 913 EPAS3S_d029_phaseVbootUv 0 "NOT_TESTED_DTC" 1 "PASSED_DTC" 2 "FAILED_DTC" 3 "UNABLE_TO_TEST_DTC";
VAL_ 913 EPAS3S_d030_phaseWbootUv 0 "NOT_TESTED_DTC" 1 "PASSED_DTC" 2 "FAILED_DTC" 3 "UNABLE_TO_TEST_DTC";
VAL_ 913 EPAS3S_d031_abnormalShutdown 0 "NOT_TESTED_DTC" 1 "PASSED_DTC" 2 "FAILED_DTC" 3 "UNABLE_TO_TEST_DTC";
VAL_ 913 EPAS3S_d032_vRegOutputUv 0 "NOT_TESTED_DTC" 1 "PASSED_DTC" 2 "FAILED_DTC" 3 "UNABLE_TO_TEST_DTC";
VAL_ 913 EPAS3S_d033_vRegOutputOv 0 "NOT_TESTED_DTC" 1 "PASSED_DTC" 2 "FAILED_DTC" 3 "UNABLE_TO_TEST_DTC";
VAL_ 913 EPAS3S_d034_vRegError 0 "NOT_TESTED_DTC" 1 "PASSED_DTC" 2 "FAILED_DTC" 3 "UNABLE_TO_TEST_DTC";
VAL_ 913 EPAS3S_d035_vbbSupplyUv 0 "NOT_TESTED_DTC" 1 "PASSED_DTC" 2 "FAILED_DTC" 3 "UNABLE_TO_TEST_DTC";
VAL_ 913 EPAS3S_d036_vbbSupplyOv 0 "NOT_TESTED_DTC" 1 "PASSED_DTC" 2 "FAILED_DTC" 3 "UNABLE_TO_TEST_DTC";
VAL_ 913 EPAS3S_d037_motPos1ParityError 0 "NOT_TESTED_DTC" 1 "PASSED_DTC" 2 "FAILED_DTC" 3 "UNABLE_TO_TEST_DTC";
VAL_ 913 EPAS3S_d038_motPos1Uv 0 "NOT_TESTED_DTC" 1 "PASSED_DTC" 2 "FAILED_DTC" 3 "UNABLE_TO_TEST_DTC";
VAL_ 913 EPAS3S_d039_motPos1MagnetMia 0 "NOT_TESTED_DTC" 1 "PASSED_DTC" 2 "FAILED_DTC" 3 "UNABLE_TO_TEST_DTC";
VAL_ 913 EPAS3S_d040_motPos1LogicError 0 "NOT_TESTED_DTC" 1 "PASSED_DTC" 2 "FAILED_DTC" 3 "UNABLE_TO_TEST_DTC";
VAL_ 913 EPAS3S_d041_motPos1tempError 0 "NOT_TESTED_DTC" 1 "PASSED_DTC" 2 "FAILED_DTC" 3 "UNABLE_TO_TEST_DTC";
VAL_ 913 EPAS3S_d042_motPos2ParityError 0 "NOT_TESTED_DTC" 1 "PASSED_DTC" 2 "FAILED_DTC" 3 "UNABLE_TO_TEST_DTC";
VAL_ 913 EPAS3S_d043_motPos2Uv 0 "NOT_TESTED_DTC" 1 "PASSED_DTC" 2 "FAILED_DTC" 3 "UNABLE_TO_TEST_DTC";
VAL_ 913 EPAS3S_d044_motPos2MagnetMia 0 "NOT_TESTED_DTC" 1 "PASSED_DTC" 2 "FAILED_DTC" 3 "UNABLE_TO_TEST_DTC";
VAL_ 913 EPAS3S_d045_motPos2LogicError 0 "NOT_TESTED_DTC" 1 "PASSED_DTC" 2 "FAILED_DTC" 3 "UNABLE_TO_TEST_DTC";
VAL_ 913 EPAS3S_d046_motPos2tempError 0 "NOT_TESTED_DTC" 1 "PASSED_DTC" 2 "FAILED_DTC" 3 "UNABLE_TO_TEST_DTC";
VAL_ 913 EPAS3S_d047_motPosCorrError 0 "NOT_TESTED_DTC" 1 "PASSED_DTC" 2 "FAILED_DTC" 3 "UNABLE_TO_TEST_DTC";
VAL_ 913 EPAS3S_d048_motPosCalError 0 "NOT_TESTED_DTC" 1 "PASSED_DTC" 2 "FAILED_DTC" 3 "UNABLE_TO_TEST_DTC";
VAL_ 913 EPAS3S_d049_piCtrlError 0 "NOT_TESTED_DTC" 1 "PASSED_DTC" 2 "FAILED_DTC" 3 "UNABLE_TO_TEST_DTC";
VAL_ 913 EPAS3S_d050_mcuSmuError 0 "NOT_TESTED_DTC" 1 "PASSED_DTC" 2 "FAILED_DTC" 3 "UNABLE_TO_TEST_DTC";
VAL_ 913 EPAS3S_d051_mcuSupError 0 "NOT_TESTED_DTC" 1 "PASSED_DTC" 2 "FAILED_DTC" 3 "UNABLE_TO_TEST_DTC";
VAL_ 913 EPAS3S_d052_intWatchdogError 0 "NOT_TESTED_DTC" 1 "PASSED_DTC" 2 "FAILED_DTC" 3 "UNABLE_TO_TEST_DTC";
VAL_ 913 EPAS3S_d053_extWatchdogError 0 "NOT_TESTED_DTC" 1 "PASSED_DTC" 2 "FAILED_DTC" 3 "UNABLE_TO_TEST_DTC";
VAL_ 913 EPAS3S_d054_memoryProtectError 0 "NOT_TESTED_DTC" 1 "PASSED_DTC" 2 "FAILED_DTC" 3 "UNABLE_TO_TEST_DTC";
VAL_ 913 EPAS3S_d055_floatPointError 0 "NOT_TESTED_DTC" 1 "PASSED_DTC" 2 "FAILED_DTC" 3 "UNABLE_TO_TEST_DTC";
VAL_ 913 EPAS3S_d056_battUv 0 "NOT_TESTED_DTC" 1 "PASSED_DTC" 2 "FAILED_DTC" 3 "UNABLE_TO_TEST_DTC";
VAL_ 913 EPAS3S_d057_battUvReduced 0 "NOT_TESTED_DTC" 1 "PASSED_DTC" 2 "FAILED_DTC" 3 "UNABLE_TO_TEST_DTC";
VAL_ 913 EPAS3S_d058_battOv 0 "NOT_TESTED_DTC" 1 "PASSED_DTC" 2 "FAILED_DTC" 3 "UNABLE_TO_TEST_DTC";
VAL_ 913 EPAS3S_d059_battOvReduced 0 "NOT_TESTED_DTC" 1 "PASSED_DTC" 2 "FAILED_DTC" 3 "UNABLE_TO_TEST_DTC";
VAL_ 913 EPAS3S_d060_battBridgeDiff 0 "NOT_TESTED_DTC" 1 "PASSED_DTC" 2 "FAILED_DTC" 3 "UNABLE_TO_TEST_DTC";
VAL_ 913 EPAS3S_d061_bridgeUv 0 "NOT_TESTED_DTC" 1 "PASSED_DTC" 2 "FAILED_DTC" 3 "UNABLE_TO_TEST_DTC";
VAL_ 913 EPAS3S_d062_assistCorrError 0 "NOT_TESTED_DTC" 1 "PASSED_DTC" 2 "FAILED_DTC" 3 "UNABLE_TO_TEST_DTC";
VAL_ 913 EPAS3S_d063_dampCorrError 0 "NOT_TESTED_DTC" 1 "PASSED_DTC" 2 "FAILED_DTC" 3 "UNABLE_TO_TEST_DTC";
VAL_ 913 EPAS3S_d064_phaseCompCorrError 0 "NOT_TESTED_DTC" 1 "PASSED_DTC" 2 "FAILED_DTC" 3 "UNABLE_TO_TEST_DTC";
VAL_ 913 EPAS3S_d065_trqTarCorrError 0 "NOT_TESTED_DTC" 1 "PASSED_DTC" 2 "FAILED_DTC" 3 "UNABLE_TO_TEST_DTC";
VAL_ 913 EPAS3S_d066_returnCorrError 0 "NOT_TESTED_DTC" 1 "PASSED_DTC" 2 "FAILED_DTC" 3 "UNABLE_TO_TEST_DTC";
VAL_ 913 EPAS3S_d067_yawDampCorrError 0 "NOT_TESTED_DTC" 1 "PASSED_DTC" 2 "FAILED_DTC" 3 "UNABLE_TO_TEST_DTC";
VAL_ 913 EPAS3S_d068_hystCorrError 0 "NOT_TESTED_DTC" 1 "PASSED_DTC" 2 "FAILED_DTC" 3 "UNABLE_TO_TEST_DTC";
VAL_ 913 EPAS3S_d069_eacCorrError 0 "NOT_TESTED_DTC" 1 "PASSED_DTC" 2 "FAILED_DTC" 3 "UNABLE_TO_TEST_DTC";
VAL_ 913 EPAS3S_d070_hodCorrError 0 "NOT_TESTED_DTC" 1 "PASSED_DTC" 2 "FAILED_DTC" 3 "UNABLE_TO_TEST_DTC";
VAL_ 913 EPAS3S_d071_vehSpdCorrError 0 "NOT_TESTED_DTC" 1 "PASSED_DTC" 2 "FAILED_DTC" 3 "UNABLE_TO_TEST_DTC";
VAL_ 913 EPAS3S_d072_motFeedFwdError 0 "NOT_TESTED_DTC" 1 "PASSED_DTC" 2 "FAILED_DTC" 3 "UNABLE_TO_TEST_DTC";
VAL_ 913 EPAS3S_d073_motParEstError 0 "NOT_TESTED_DTC" 1 "PASSED_DTC" 2 "FAILED_DTC" 3 "UNABLE_TO_TEST_DTC";
VAL_ 913 EPAS3S_d074_overHeatProtect 0 "NOT_TESTED_DTC" 1 "PASSED_DTC" 2 "FAILED_DTC" 3 "UNABLE_TO_TEST_DTC";
VAL_ 913 EPAS3S_d075_fspPwrCut 0 "NOT_TESTED_DTC" 1 "PASSED_DTC" 2 "FAILED_DTC" 3 "UNABLE_TO_TEST_DTC";
VAL_ 913 EPAS3S_d076_tempSensOutofRange 0 "NOT_TESTED_DTC" 1 "PASSED_DTC" 2 "FAILED_DTC" 3 "UNABLE_TO_TEST_DTC";
VAL_ 913 EPAS3S_d077_highSideFetError 0 "NOT_TESTED_DTC" 1 "PASSED_DTC" 2 "FAILED_DTC" 3 "UNABLE_TO_TEST_DTC";
VAL_ 913 EPAS3S_d078_phaseDisconnectError 0 "NOT_TESTED_DTC" 1 "PASSED_DTC" 2 "FAILED_DTC" 3 "UNABLE_TO_TEST_DTC";
VAL_ 913 EPAS3S_d079_backupCurrentPlaus 0 "NOT_TESTED_DTC" 1 "PASSED_DTC" 2 "FAILED_DTC" 3 "UNABLE_TO_TEST_DTC";
VAL_ 913 EPAS3S_d080_ecuInitArbError 0 "NOT_TESTED_DTC" 1 "PASSED_DTC" 2 "FAILED_DTC" 3 "UNABLE_TO_TEST_DTC";
VAL_ 913 EPAS3S_d081_coggCompError 0 "NOT_TESTED_DTC" 1 "PASSED_DTC" 2 "FAILED_DTC" 3 "UNABLE_TO_TEST_DTC";
VAL_ 913 EPAS3S_d082_polarityCalError 0 "NOT_TESTED_DTC" 1 "PASSED_DTC" 2 "FAILED_DTC" 3 "UNABLE_TO_TEST_DTC";
VAL_ 913 EPAS3S_d083_crcMismatch 0 "NOT_TESTED_DTC" 1 "PASSED_DTC" 2 "FAILED_DTC" 3 "UNABLE_TO_TEST_DTC";
VAL_ 913 EPAS3S_d084_eacCancelled 0 "NOT_TESTED_DTC" 1 "PASSED_DTC" 2 "FAILED_DTC" 3 "UNABLE_TO_TEST_DTC";
VAL_ 913 EPAS3S_d085_canBusOff 0 "NOT_TESTED_DTC" 1 "PASSED_DTC" 2 "FAILED_DTC" 3 "UNABLE_TO_TEST_DTC";
VAL_ 913 EPAS3S_d086_dasMia 0 "NOT_TESTED_DTC" 1 "PASSED_DTC" 2 "FAILED_DTC" 3 "UNABLE_TO_TEST_DTC";
VAL_ 913 EPAS3S_d087_dasCntError 0 "NOT_TESTED_DTC" 1 "PASSED_DTC" 2 "FAILED_DTC" 3 "UNABLE_TO_TEST_DTC";
VAL_ 913 EPAS3S_d088_dasCsError 0 "NOT_TESTED_DTC" 1 "PASSED_DTC" 2 "FAILED_DTC" 3 "UNABLE_TO_TEST_DTC";
VAL_ 913 EPAS3S_d089_espWsMia 0 "NOT_TESTED_DTC" 1 "PASSED_DTC" 2 "FAILED_DTC" 3 "UNABLE_TO_TEST_DTC";
VAL_ 913 EPAS3S_d090_espWsCntError 0 "NOT_TESTED_DTC" 1 "PASSED_DTC" 2 "FAILED_DTC" 3 "UNABLE_TO_TEST_DTC";
VAL_ 913 EPAS3S_d091_espWsCsError 0 "NOT_TESTED_DTC" 1 "PASSED_DTC" 2 "FAILED_DTC" 3 "UNABLE_TO_TEST_DTC";
VAL_ 913 EPAS3S_d092_espbMia 0 "NOT_TESTED_DTC" 1 "PASSED_DTC" 2 "FAILED_DTC" 3 "UNABLE_TO_TEST_DTC";
VAL_ 913 EPAS3S_d093_espbCntError 0 "NOT_TESTED_DTC" 1 "PASSED_DTC" 2 "FAILED_DTC" 3 "UNABLE_TO_TEST_DTC";
VAL_ 913 EPAS3S_d094_espbCsError 0 "NOT_TESTED_DTC" 1 "PASSED_DTC" 2 "FAILED_DTC" 3 "UNABLE_TO_TEST_DTC";
VAL_ 913 EPAS3S_d095_espbQf 0 "NOT_TESTED_DTC" 1 "PASSED_DTC" 2 "FAILED_DTC" 3 "UNABLE_TO_TEST_DTC";
VAL_ 913 EPAS3S_d096_espcMia 0 "NOT_TESTED_DTC" 1 "PASSED_DTC" 2 "FAILED_DTC" 3 "UNABLE_TO_TEST_DTC";
VAL_ 913 EPAS3S_d097_espcCntError 0 "NOT_TESTED_DTC" 1 "PASSED_DTC" 2 "FAILED_DTC" 3 "UNABLE_TO_TEST_DTC";
VAL_ 913 EPAS3S_d098_espcCsError 0 "NOT_TESTED_DTC" 1 "PASSED_DTC" 2 "FAILED_DTC" 3 "UNABLE_TO_TEST_DTC";
VAL_ 913 EPAS3S_d099_espcQf 0 "NOT_TESTED_DTC" 1 "PASSED_DTC" 2 "FAILED_DTC" 3 "UNABLE_TO_TEST_DTC";
VAL_ 913 EPAS3S_d100_gtwMia 0 "NOT_TESTED_DTC" 1 "PASSED_DTC" 2 "FAILED_DTC" 3 "UNABLE_TO_TEST_DTC";
VAL_ 913 EPAS3S_d101_gtwCntError 0 "NOT_TESTED_DTC" 1 "PASSED_DTC" 2 "FAILED_DTC" 3 "UNABLE_TO_TEST_DTC";
VAL_ 913 EPAS3S_d102_gtwCsError 0 "NOT_TESTED_DTC" 1 "PASSED_DTC" 2 "FAILED_DTC" 3 "UNABLE_TO_TEST_DTC";
VAL_ 913 EPAS3S_d103_apsMia 0 "NOT_TESTED_DTC" 1 "PASSED_DTC" 2 "FAILED_DTC" 3 "UNABLE_TO_TEST_DTC";
VAL_ 913 EPAS3S_d104_apsCntError 0 "NOT_TESTED_DTC" 1 "PASSED_DTC" 2 "FAILED_DTC" 3 "UNABLE_TO_TEST_DTC";
VAL_ 913 EPAS3S_d105_apsCsError 0 "NOT_TESTED_DTC" 1 "PASSED_DTC" 2 "FAILED_DTC" 3 "UNABLE_TO_TEST_DTC";
VAL_ 913 EPAS3S_d106_diMia 0 "NOT_TESTED_DTC" 1 "PASSED_DTC" 2 "FAILED_DTC" 3 "UNABLE_TO_TEST_DTC";
VAL_ 913 EPAS3S_d107_diCntError 0 "NOT_TESTED_DTC" 1 "PASSED_DTC" 2 "FAILED_DTC" 3 "UNABLE_TO_TEST_DTC";
VAL_ 913 EPAS3S_d108_diCsError 0 "NOT_TESTED_DTC" 1 "PASSED_DTC" 2 "FAILED_DTC" 3 "UNABLE_TO_TEST_DTC";
VAL_ 913 EPAS3S_d109_sasMia 0 "NOT_TESTED_DTC" 1 "PASSED_DTC" 2 "FAILED_DTC" 3 "UNABLE_TO_TEST_DTC";
VAL_ 913 EPAS3S_d110_sasCntError 0 "NOT_TESTED_DTC" 1 "PASSED_DTC" 2 "FAILED_DTC" 3 "UNABLE_TO_TEST_DTC";
VAL_ 913 EPAS3S_d111_sasCsError 0 "NOT_TESTED_DTC" 1 "PASSED_DTC" 2 "FAILED_DTC" 3 "UNABLE_TO_TEST_DTC";
VAL_ 913 EPAS3S_d112_sasStatError 0 "NOT_TESTED_DTC" 1 "PASSED_DTC" 2 "FAILED_DTC" 3 "UNABLE_TO_TEST_DTC";
VAL_ 913 EPAS3S_d113_espWsQf 0 "NOT_TESTED_DTC" 1 "PASSED_DTC" 2 "FAILED_DTC" 3 "UNABLE_TO_TEST_DTC";
VAL_ 913 EPAS3S_d114_gtwOdoMia 0 "NOT_TESTED_DTC" 1 "PASSED_DTC" 2 "FAILED_DTC" 3 "UNABLE_TO_TEST_DTC";
VAL_ 913 EPAS3S_d115_ecuStatMia 0 "NOT_TESTED_DTC" 1 "PASSED_DTC" 2 "FAILED_DTC" 3 "UNABLE_TO_TEST_DTC";
VAL_ 913 EPAS3S_d116_ecuStatCntError 0 "NOT_TESTED_DTC" 1 "PASSED_DTC" 2 "FAILED_DTC" 3 "UNABLE_TO_TEST_DTC";
VAL_ 913 EPAS3S_d117_ecuStatCrcError 0 "NOT_TESTED_DTC" 1 "PASSED_DTC" 2 "FAILED_DTC" 3 "UNABLE_TO_TEST_DTC";
VAL_ 913 EPAS3S_d118_espPriv1Mia 0 "NOT_TESTED_DTC" 1 "PASSED_DTC" 2 "FAILED_DTC" 3 "UNABLE_TO_TEST_DTC";
VAL_ 913 EPAS3S_d119_espPriv1CntError 0 "NOT_TESTED_DTC" 1 "PASSED_DTC" 2 "FAILED_DTC" 3 "UNABLE_TO_TEST_DTC";
VAL_ 913 EPAS3S_d120_espPriv1CsError 0 "NOT_TESTED_DTC" 1 "PASSED_DTC" 2 "FAILED_DTC" 3 "UNABLE_TO_TEST_DTC";
VAL_ 913 EPAS3S_d121_espPriv1Qf 0 "NOT_TESTED_DTC" 1 "PASSED_DTC" 2 "FAILED_DTC" 3 "UNABLE_TO_TEST_DTC";
VAL_ 913 EPAS3S_d122_privateBusOff 0 "NOT_TESTED_DTC" 1 "PASSED_DTC" 2 "FAILED_DTC" 3 "UNABLE_TO_TEST_DTC";
VAL_ 913 EPAS3S_d123_pvtEcuStatMia 0 "NOT_TESTED_DTC" 1 "PASSED_DTC" 2 "FAILED_DTC" 3 "UNABLE_TO_TEST_DTC";
VAL_ 913 EPAS3S_d124_pvtEcuStatCntError 0 "NOT_TESTED_DTC" 1 "PASSED_DTC" 2 "FAILED_DTC" 3 "UNABLE_TO_TEST_DTC";
VAL_ 913 EPAS3S_d125_pvtEcuStatCrcError 0 "NOT_TESTED_DTC" 1 "PASSED_DTC" 2 "FAILED_DTC" 3 "UNABLE_TO_TEST_DTC";
VAL_ 913 EPAS3S_d126_olpActive 0 "NOT_TESTED_DTC" 1 "PASSED_DTC" 2 "FAILED_DTC" 3 "UNABLE_TO_TEST_DTC";
VAL_ 913 EPAS3S_d127_combEcu2StatFail 0 "NOT_TESTED_DTC" 1 "PASSED_DTC" 2 "FAILED_DTC" 3 "UNABLE_TO_TEST_DTC";
VAL_ 913 EPAS3S_d128_tempSensStuckInRange 0 "NOT_TESTED_DTC" 1 "PASSED_DTC" 2 "FAILED_DTC" 3 "UNABLE_TO_TEST_DTC";
VAL_ 913 EPAS3S_d129_trqSensTrimOutRange 0 "NOT_TESTED_DTC" 1 "PASSED_DTC" 2 "FAILED_DTC" 3 "UNABLE_TO_TEST_DTC";
VAL_ 913 EPAS3S_d130_combEcu1StatFail 0 "NOT_TESTED_DTC" 1 "PASSED_DTC" 2 "FAILED_DTC" 3 "UNABLE_TO_TEST_DTC";
VAL_ 913 EPAS3S_d131_sasOffsetNotCal 0 "NOT_TESTED_DTC" 1 "PASSED_DTC" 2 "FAILED_DTC" 3 "UNABLE_TO_TEST_DTC";
VAL_ 913 EPAS3S_d132_phaseFeedbackError 0 "NOT_TESTED_DTC" 1 "PASSED_DTC" 2 "FAILED_DTC" 3 "UNABLE_TO_TEST_DTC";

VAL_ 896 EPAS_d001_KFC_STORQUE_0 0 "NOT_TESTED_DTC" 1 "PASSED_DTC" 2 "FAILED_DTC" 3 "UNABLE_TO_TEST_DTC";
VAL_ 896 EPAS_d002_KFC_NVRAM_MNG_READ 0 "NOT_TESTED_DTC" 1 "PASSED_DTC" 2 "FAILED_DTC" 3 "UNABLE_TO_TEST_DTC";
VAL_ 896 EPAS_d003_KFC_NVRAM_MNG_WRITE 0 "NOT_TESTED_DTC" 1 "PASSED_DTC" 2 "FAILED_DTC" 3 "UNABLE_TO_TEST_DTC";
VAL_ 896 EPAS_d004_KFC_NVRAM_MNG_VERIFY 0 "NOT_TESTED_DTC" 1 "PASSED_DTC" 2 "FAILED_DTC" 3 "UNABLE_TO_TEST_DTC";
VAL_ 896 EPAS_d005_KFC_ASIC 0 "NOT_TESTED_DTC" 1 "PASSED_DTC" 2 "FAILED_DTC" 3 "UNABLE_TO_TEST_DTC";
VAL_ 896 EPAS_d006_KFC_CLOCKMON 0 "NOT_TESTED_DTC" 1 "PASSED_DTC" 2 "FAILED_DTC" 3 "UNABLE_TO_TEST_DTC";
VAL_ 896 EPAS_d007_KFC_OUTPUT_STAGE_DRV 0 "NOT_TESTED_DTC" 1 "PASSED_DTC" 2 "FAILED_DTC" 3 "UNABLE_TO_TEST_DTC";
VAL_ 896 EPAS_d008_KFC_SHUT_DOWN 0 "NOT_TESTED_DTC" 1 "PASSED_DTC" 2 "FAILED_DTC" 3 "UNABLE_TO_TEST_DTC";
VAL_ 896 EPAS_d009_KFC_WD_CHECK 0 "NOT_TESTED_DTC" 1 "PASSED_DTC" 2 "FAILED_DTC" 3 "UNABLE_TO_TEST_DTC";
VAL_ 896 EPAS_d010_KFC_COMP_L1 0 "NOT_TESTED_DTC" 1 "PASSED_DTC" 2 "FAILED_DTC" 3 "UNABLE_TO_TEST_DTC";
VAL_ 896 EPAS_d011_KFC_COMP_L2 0 "NOT_TESTED_DTC" 1 "PASSED_DTC" 2 "FAILED_DTC" 3 "UNABLE_TO_TEST_DTC";
VAL_ 896 EPAS_d012_KFC_ADC 0 "NOT_TESTED_DTC" 1 "PASSED_DTC" 2 "FAILED_DTC" 3 "UNABLE_TO_TEST_DTC";
VAL_ 896 EPAS_d013_KFC_UKL30_2H 0 "NOT_TESTED_DTC" 1 "PASSED_DTC" 2 "FAILED_DTC" 3 "UNABLE_TO_TEST_DTC";
VAL_ 896 EPAS_d014_KFC_UKL30_2L 0 "NOT_TESTED_DTC" 1 "PASSED_DTC" 2 "FAILED_DTC" 3 "UNABLE_TO_TEST_DTC";
VAL_ 896 EPAS_d015_KFC_UCU_RED 0 "NOT_TESTED_DTC" 1 "PASSED_DTC" 2 "FAILED_DTC" 3 "UNABLE_TO_TEST_DTC";
VAL_ 896 EPAS_d016_KFC_CCU_RED 0 "NOT_TESTED_DTC" 1 "PASSED_DTC" 2 "FAILED_DTC" 3 "UNABLE_TO_TEST_DTC";
VAL_ 896 EPAS_d017_KFC_UUT_RED 0 "NOT_TESTED_DTC" 1 "PASSED_DTC" 2 "FAILED_DTC" 3 "UNABLE_TO_TEST_DTC";
VAL_ 896 EPAS_d018_KFC_UKL30_2H_OFF 0 "NOT_TESTED_DTC" 1 "PASSED_DTC" 2 "FAILED_DTC" 3 "UNABLE_TO_TEST_DTC";
VAL_ 896 EPAS_d019_KFC_UKL30_2L_OFF 0 "NOT_TESTED_DTC" 1 "PASSED_DTC" 2 "FAILED_DTC" 3 "UNABLE_TO_TEST_DTC";
VAL_ 896 EPAS_d020_KFC_RAM 0 "NOT_TESTED_DTC" 1 "PASSED_DTC" 2 "FAILED_DTC" 3 "UNABLE_TO_TEST_DTC";
VAL_ 896 EPAS_d021_KFC_SPI_COM_TIMO 0 "NOT_TESTED_DTC" 1 "PASSED_DTC" 2 "FAILED_DTC" 3 "UNABLE_TO_TEST_DTC";
VAL_ 896 EPAS_d022_KFC_SPI_SYNC_REG 0 "NOT_TESTED_DTC" 1 "PASSED_DTC" 2 "FAILED_DTC" 3 "UNABLE_TO_TEST_DTC";
VAL_ 896 EPAS_d023_KFC_PWD 0 "NOT_TESTED_DTC" 1 "PASSED_DTC" 2 "FAILED_DTC" 3 "UNABLE_TO_TEST_DTC";
VAL_ 896 EPAS_d024_KFC_PROGFLOW 0 "NOT_TESTED_DTC" 1 "PASSED_DTC" 2 "FAILED_DTC" 3 "UNABLE_TO_TEST_DTC";
VAL_ 896 EPAS_d025_KFC_STORQUE_OC 0 "NOT_TESTED_DTC" 1 "PASSED_DTC" 2 "FAILED_DTC" 3 "UNABLE_TO_TEST_DTC";
VAL_ 896 EPAS_d026_KFC_STORQUE_RAD 0 "NOT_TESTED_DTC" 1 "PASSED_DTC" 2 "FAILED_DTC" 3 "UNABLE_TO_TEST_DTC";
VAL_ 896 EPAS_d027_KFC_FOR_TIMO 0 "NOT_TESTED_DTC" 1 "PASSED_DTC" 2 "FAILED_DTC" 3 "UNABLE_TO_TEST_DTC";
VAL_ 896 EPAS_d028_KFC_PROG_WD 0 "NOT_TESTED_DTC" 1 "PASSED_DTC" 2 "FAILED_DTC" 3 "UNABLE_TO_TEST_DTC";
VAL_ 896 EPAS_d029_KFC_CST 0 "NOT_TESTED_DTC" 1 "PASSED_DTC" 2 "FAILED_DTC" 3 "UNABLE_TO_TEST_DTC";
VAL_ 896 EPAS_d030_KFC_REG_CHECK 0 "NOT_TESTED_DTC" 1 "PASSED_DTC" 2 "FAILED_DTC" 3 "UNABLE_TO_TEST_DTC";
VAL_ 896 EPAS_d031_KFC_CR_RED 0 "NOT_TESTED_DTC" 1 "PASSED_DTC" 2 "FAILED_DTC" 3 "UNABLE_TO_TEST_DTC";
VAL_ 896 EPAS_d032_KFC_ROM 0 "NOT_TESTED_DTC" 1 "PASSED_DTC" 2 "FAILED_DTC" 3 "UNABLE_TO_TEST_DTC";
VAL_ 896 EPAS_d033_KFC_SWGEN 0 "NOT_TESTED_DTC" 1 "PASSED_DTC" 2 "FAILED_DTC" 3 "UNABLE_TO_TEST_DTC";
VAL_ 896 EPAS_d034_KFC_FOR_OC 0 "NOT_TESTED_DTC" 1 "PASSED_DTC" 2 "FAILED_DTC" 3 "UNABLE_TO_TEST_DTC";
VAL_ 896 EPAS_d035_KFC_FOR_WREL 0 "NOT_TESTED_DTC" 1 "PASSED_DTC" 2 "FAILED_DTC" 3 "UNABLE_TO_TEST_DTC";
VAL_ 896 EPAS_d036_KFC_FOR_ANGLE 0 "NOT_TESTED_DTC" 1 "PASSED_DTC" 2 "FAILED_DTC" 3 "UNABLE_TO_TEST_DTC";
VAL_ 896 EPAS_d037_KFC_FOR_LENGTH 0 "NOT_TESTED_DTC" 1 "PASSED_DTC" 2 "FAILED_DTC" 3 "UNABLE_TO_TEST_DTC";
VAL_ 896 EPAS_d038_KFC_BUS_OFF 0 "NOT_TESTED_DTC" 1 "PASSED_DTC" 2 "FAILED_DTC" 3 "UNABLE_TO_TEST_DTC";
VAL_ 896 EPAS_d039_KFC_RESET 0 "NOT_TESTED_DTC" 1 "PASSED_DTC" 2 "FAILED_DTC" 3 "UNABLE_TO_TEST_DTC";
VAL_ 896 EPAS_d040_KFC_RSRADIUS 0 "NOT_TESTED_DTC" 1 "PASSED_DTC" 2 "FAILED_DTC" 3 "UNABLE_TO_TEST_DTC";
VAL_ 896 EPAS_d041_KFC_U_REDUNDANT 0 "NOT_TESTED_DTC" 1 "PASSED_DTC" 2 "FAILED_DTC" 3 "UNABLE_TO_TEST_DTC";
VAL_ 896 EPAS_d042_KFC_RSDIFF 0 "NOT_TESTED_DTC" 1 "PASSED_DTC" 2 "FAILED_DTC" 3 "UNABLE_TO_TEST_DTC";
VAL_ 896 EPAS_d043_KFC_ESP_TIMO 0 "NOT_TESTED_DTC" 1 "PASSED_DTC" 2 "FAILED_DTC" 3 "UNABLE_TO_TEST_DTC";
VAL_ 896 EPAS_d044_KFC_GTW_TIMO 0 "NOT_TESTED_DTC" 1 "PASSED_DTC" 2 "FAILED_DTC" 3 "UNABLE_TO_TEST_DTC";
VAL_ 896 EPAS_d045_KFC_DI_Torque1_TIMO 0 "NOT_TESTED_DTC" 1 "PASSED_DTC" 2 "FAILED_DTC" 3 "UNABLE_TO_TEST_DTC";
VAL_ 896 EPAS_d046_KFC_SAS_TIMO 0 "NOT_TESTED_DTC" 1 "PASSED_DTC" 2 "FAILED_DTC" 3 "UNABLE_TO_TEST_DTC";
VAL_ 896 EPAS_d047_KFC_EACALLOW 0 "NOT_TESTED_DTC" 1 "PASSED_DTC" 2 "FAILED_DTC" 3 "UNABLE_TO_TEST_DTC";
VAL_ 896 EPAS_d048_KFC_EPB_TIMO 0 "NOT_TESTED_DTC" 1 "PASSED_DTC" 2 "FAILED_DTC" 3 "UNABLE_TO_TEST_DTC";
VAL_ 896 EPAS_d049_KFC_ESRA_CANCELLED 0 "NOT_TESTED_DTC" 1 "PASSED_DTC" 2 "FAILED_DTC" 3 "UNABLE_TO_TEST_DTC";
VAL_ 896 EPAS_d050_KFC_STEERING_ANGLE 0 "NOT_TESTED_DTC" 1 "PASSED_DTC" 2 "FAILED_DTC" 3 "UNABLE_TO_TEST_DTC";
VAL_ 896 EPAS_d051_KFC_VEHICLE_SPEED 0 "NOT_TESTED_DTC" 1 "PASSED_DTC" 2 "FAILED_DTC" 3 "UNABLE_TO_TEST_DTC";
VAL_ 896 EPAS_d052_KFC_UNUSED_52 0 "NOT_TESTED_DTC" 1 "PASSED_DTC" 2 "FAILED_DTC" 3 "UNABLE_TO_TEST_DTC";
VAL_ 896 EPAS_d053_KFC_UNUSED_53 0 "NOT_TESTED_DTC" 1 "PASSED_DTC" 2 "FAILED_DTC" 3 "UNABLE_TO_TEST_DTC";
VAL_ 896 EPAS_d054_KFC_CCF_NOT_CONFIGURED 0 "NOT_TESTED_DTC" 1 "PASSED_DTC" 2 "FAILED_DTC" 3 "UNABLE_TO_TEST_DTC";
VAL_ 896 EPAS_d055_KFC_CCF_INVALID 0 "NOT_TESTED_DTC" 1 "PASSED_DTC" 2 "FAILED_DTC" 3 "UNABLE_TO_TEST_DTC";
VAL_ 896 EPAS_d056_KFC_UNUSED_56 0 "NOT_TESTED_DTC" 1 "PASSED_DTC" 2 "FAILED_DTC" 3 "UNABLE_TO_TEST_DTC";
VAL_ 896 EPAS_d057_KFC_FRICTION 0 "NOT_TESTED_DTC" 1 "PASSED_DTC" 2 "FAILED_DTC" 3 "UNABLE_TO_TEST_DTC";
VAL_ 896 EPAS_d058_KFC_EXPULSION_MODE 0 "NOT_TESTED_DTC" 1 "PASSED_DTC" 2 "FAILED_DTC" 3 "UNABLE_TO_TEST_DTC";
VAL_ 896 EPAS_d059_KFC_TEMP_DIAG_DEV 0 "NOT_TESTED_DTC" 1 "PASSED_DTC" 2 "FAILED_DTC" 3 "UNABLE_TO_TEST_DTC";
VAL_ 896 EPAS_d060_KFC_POWER_MODE 0 "NOT_TESTED_DTC" 1 "PASSED_DTC" 2 "FAILED_DTC" 3 "UNABLE_TO_TEST_DTC";
VAL_ 896 EPAS_d061_KFC_UNUSED_61 0 "NOT_TESTED_DTC" 1 "PASSED_DTC" 2 "FAILED_DTC" 3 "UNABLE_TO_TEST_DTC";
VAL_ 896 EPAS_d062_KFC_WHEEL_SPEEDS 0 "NOT_TESTED_DTC" 1 "PASSED_DTC" 2 "FAILED_DTC" 3 "UNABLE_TO_TEST_DTC";
VAL_ 896 EPAS_d063_KFC_UNUSED_63 0 "NOT_TESTED_DTC" 1 "PASSED_DTC" 2 "FAILED_DTC" 3 "UNABLE_TO_TEST_DTC";
VAL_ 896 EPAS_d064_KFC_DI_MOTORRPM 0 "NOT_TESTED_DTC" 1 "PASSED_DTC" 2 "FAILED_DTC" 3 "UNABLE_TO_TEST_DTC";
VAL_ 896 EPAS_d065_KFC_YAW_RATE 0 "NOT_TESTED_DTC" 1 "PASSED_DTC" 2 "FAILED_DTC" 3 "UNABLE_TO_TEST_DTC";
VAL_ 896 EPAS_d066_KFC_UCU_RED_INFO 0 "NOT_TESTED_DTC" 1 "PASSED_DTC" 2 "FAILED_DTC" 3 "UNABLE_TO_TEST_DTC";
VAL_ 896 EPAS_d067_KFC_CCU_RED_INFO 0 "NOT_TESTED_DTC" 1 "PASSED_DTC" 2 "FAILED_DTC" 3 "UNABLE_TO_TEST_DTC";
VAL_ 896 EPAS_d068_KFC_UCO_RED_INFO 0 "NOT_TESTED_DTC" 1 "PASSED_DTC" 2 "FAILED_DTC" 3 "UNABLE_TO_TEST_DTC";
VAL_ 896 EPAS_d069_KFC_CR_RED_INFO 0 "NOT_TESTED_DTC" 1 "PASSED_DTC" 2 "FAILED_DTC" 3 "UNABLE_TO_TEST_DTC";
VAL_ 896 EPAS_d070_KFC_ROTANG 0 "NOT_TESTED_DTC" 1 "PASSED_DTC" 2 "FAILED_DTC" 3 "UNABLE_TO_TEST_DTC";
VAL_ 896 EPAS_d071_KFC_PD_RED 0 "NOT_TESTED_DTC" 1 "PASSED_DTC" 2 "FAILED_DTC" 3 "UNABLE_TO_TEST_DTC";
VAL_ 896 EPAS_d072_KFC_OS_MON 0 "NOT_TESTED_DTC" 1 "PASSED_DTC" 2 "FAILED_DTC" 3 "UNABLE_TO_TEST_DTC";
VAL_ 896 EPAS_d073_KFC_UCO_RED 0 "NOT_TESTED_DTC" 1 "PASSED_DTC" 2 "FAILED_DTC" 3 "UNABLE_TO_TEST_DTC";
VAL_ 896 EPAS_d074_KFC_SSW 0 "NOT_TESTED_DTC" 1 "PASSED_DTC" 2 "FAILED_DTC" 3 "UNABLE_TO_TEST_DTC";
VAL_ 896 EPAS_d075_KFC_BLOCKED_STEERING 0 "NOT_TESTED_DTC" 1 "PASSED_DTC" 2 "FAILED_DTC" 3 "UNABLE_TO_TEST_DTC";
VAL_ 896 EPAS_d076_KFC_DAS_TIMO 0 "NOT_TESTED_DTC" 1 "PASSED_DTC" 2 "FAILED_DTC" 3 "UNABLE_TO_TEST_DTC";
VAL_ 896 EPAS_d077_KFC_STEERING_CONTROL 0 "NOT_TESTED_DTC" 1 "PASSED_DTC" 2 "FAILED_DTC" 3 "UNABLE_TO_TEST_DTC";

VAL_ 1328 EPAS_infoIndex 0 "DEPRECATED_0" 1 "DEPRECATED_1" 2 "DEPRECATED_2" 3 "DEPRECATED_3" 4 "DEPRECATED_4" 5 "DEPRECATED_5" 6 "DEPRECATED_6" 7 "DEPRECATED_7" 8 "DEPRECATED_8" 9 "DEPRECATED_9" 10 "BUILD_HWID_COMPONENTID" 11 "PCBAID_ASSYID_USAGEID" 13 "APP_CRC" 14 "BOOTLOADER_SVN" 15 "BOOTLOADER_CRC" 16 "SUBCOMPONENT" 17 "APP_GITHASH" 18 "BOOTLOADER_GITHASH" 19 "VERSION_DEPRECATED" 20 "UDS_PROTOCOL_BOOTCRC" 255 "END";

VAL_ 880 EPAS_handsOnLevel 0 "0" 1 "1" 2 "2" 3 "3";
VAL_ 880 EPAS_torsionBarTorque 4094 "UNDEFINABLE_DATA" 4095 "SNA";
